VERSION ""

NS_ :

BS_:

BU_: VDM CMR_DSMC SOBDMC_HPCM_FD1 IPMA_ADAS PSCM ABS_ESC TCCM TCM_DSL PCM_HEV PCM ECM_Diesel GENERIC_GWMWakeup GWM _delete TSTR

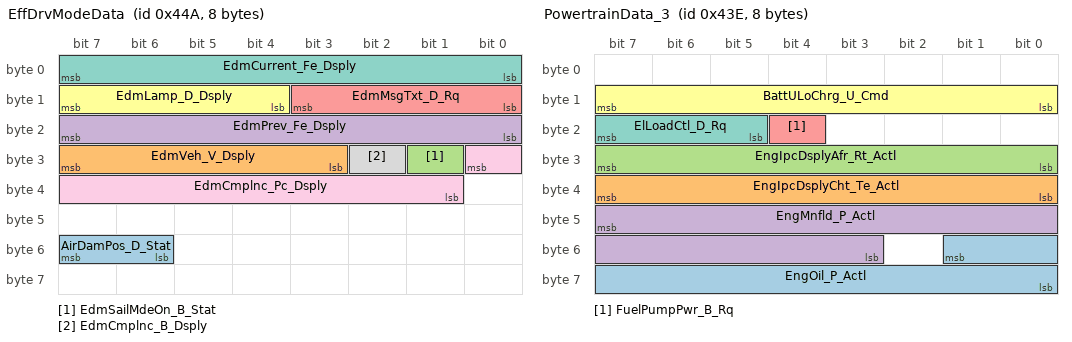
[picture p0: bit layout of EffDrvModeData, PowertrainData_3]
BO_ 1098 EffDrvModeData: 8 ECM_Diesel
 SG_ AirDamPos_D_Stat : 55|2@0+ (1,0) [0|3] "SED"  GWM
 SG_ EdmVeh_V_Dsply : 31|5@0+ (5,0) [0|155] "km/h"  GWM
 SG_ EdmSailMdeOn_B_Stat : 25|1@0+ (1,0) [0|1] "SED"  GWM
 SG_ EdmPrev_Fe_Dsply : 23|8@0+ (0.1,0) [0|25.5] "litre/100km"  GWM
 SG_ EdmMsgTxt_D_Rq : 11|4@0+ (1,0) [0|15] "SED"  GWM
 SG_ EdmLamp_D_Dsply : 15|4@0+ (1,0) [0|15] "SED"  GWM
 SG_ EdmCurrent_Fe_Dsply : 7|8@0+ (0.1,0) [0|25.5] "litre/100km"  GWM
 SG_ EdmCmplnc_B_Dsply : 26|1@0+ (1,0) [0|1] "SED"  GWM
 SG_ EdmCmplnc_Pc_Dsply : 24|8@0+ (0.392157,0) [0|100.000035] "percent"  GWM

BO_ 1086 PowertrainData_3: 8 PCM_HEV
 SG_ EngOil_P_Actl : 49|10@0+ (1,0) [0|1023] "kilopascal"  GWM
 SG_ EngIpcDsplyCht_Te_Actl : 39|8@0+ (1,-60) [-60|195] "degC"  GWM
 SG_ EngIpcDsplyAfr_Rt_Actl : 31|8@0+ (0.1,0) [0|25.5] "unitless"  GWM
 SG_ EngMnfld_P_Actl : 47|13@0+ (0.1,-206.8) [-206.8|612.3] "kilopascal"  GWM
 SG_ FuelPumpPwr_B_Rq : 20|1@0+ (1,0) [0|1] "SED"  GWM
 SG_ BattULoChrg_U_Cmd : 15|8@0+ (0.025,10.6) [10.6|16.975] "volt"  GWM
 SG_ ElLoadCtl_D_Rq : 23|3@0+ (1,0) [0|7] "SED"  GWM

BO_ 1071 Engine_Clutch_Data: 8 PCM_HEV
 SG_ EngAout_N_Dsply : 52|13@0+ (2,0) [0|16382] "rpm"  GWM
 SG_ CluPdl_PcRate_Actl : 7|8@0+ (0.04,-5) [-5|5.2] "%/ms"  GWM
 SG_ CluPdlPosPcMeas_D_Qf : 11|2@0+ (1,0) [0|3] "SED"  ABS_ESC,GWM
 SG_ CluPdlPos_Pc_Meas : 9|10@0+ (0.1,0) [0|102.3] "%"  ABS_ESC,GWM
 SG_ EngAoutIdl_N_Ntrl : 31|11@0+ (2,0) [0|4094] "rpm"  ABS_ESC,GWM

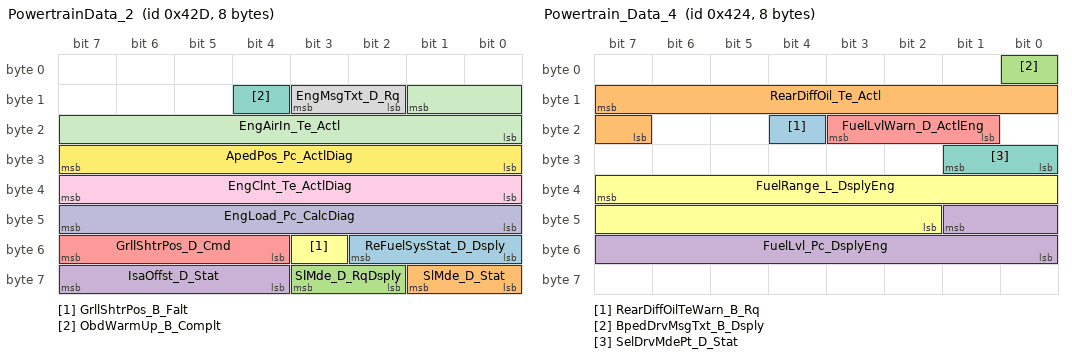
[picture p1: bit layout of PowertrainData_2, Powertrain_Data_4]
BO_ 1069 PowertrainData_2: 8 PCM_HEV
 SG_ ReFuelSysStat_D_Dsply : 50|3@0+ (1,0) [0|7] "SED"  GWM
 SG_ SlMde_D_Stat : 57|2@0+ (1,0) [0|3] "SED"  GWM
 SG_ SlMde_D_RqDsply : 59|2@0+ (1,0) [0|3] "SED"  GWM
 SG_ IsaOffst_D_Stat : 63|4@0+ (1,0) [0|15] "SED"  GWM
 SG_ GrllShtrPos_D_Cmd : 55|4@0+ (1,0) [0|15] "SED"  GWM
 SG_ GrllShtrPos_B_Falt : 51|1@0+ (1,0) [0|1] "SED"  GWM
 SG_ ObdWarmUp_B_Complt : 12|1@0+ (1,0) [0|1] "SED"  SOBDMC_HPCM_FD1,GWM
 SG_ EngMsgTxt_D_Rq : 11|2@0+ (1,0) [0|3] "SED"  GWM
 SG_ EngClnt_Te_ActlDiag : 39|8@0+ (1,-40) [-40|215] "degC"  SOBDMC_HPCM_FD1,TCM_DSL,GWM
 SG_ EngLoad_Pc_CalcDiag : 47|8@0+ (0.392157,0) [0|100.000035] "%"  SOBDMC_HPCM_FD1,TCM_DSL,GWM
 SG_ EngAirIn_Te_Actl : 9|10@0+ (0.25,-128) [-128|127.25] "degC"  GWM,TCM_DSL
 SG_ ApedPos_Pc_ActlDiag : 31|8@0+ (0.392157,0) [0|100.000035] "%"  SOBDMC_HPCM_FD1,TCM_DSL,GWM

BO_ 1060 Powertrain_Data_4: 8 PCM_HEV
 SG_ RearDiffOilTeWarn_B_Rq : 20|1@0+ (1,0) [0|1] "SED"  GWM
 SG_ RearDiffOil_Te_Actl : 15|9@0+ (1,-40) [-40|470] "degC"  GWM
 SG_ BpedDrvMsgTxt_B_Dsply : 0|1@0+ (1,0) [0|1] "SED"  GWM
 SG_ FuelLvl_Pc_DsplyEng : 41|10@0+ (0.108696,-5.217408) [-5.217408|105.9786] "percent"  GWM
 SG_ FuelLvlWarn_D_ActlEng : 19|3@0+ (1,0) [0|7] "SED"  GWM
 SG_ FuelRange_L_DsplyEng : 39|14@0+ (0.1,0) [0|1638.3] "kilometer"  GWM
 SG_ SelDrvMdePt_D_Stat : 25|2@0+ (1,0) [0|3] "SED"  ABS_ESC,GWM

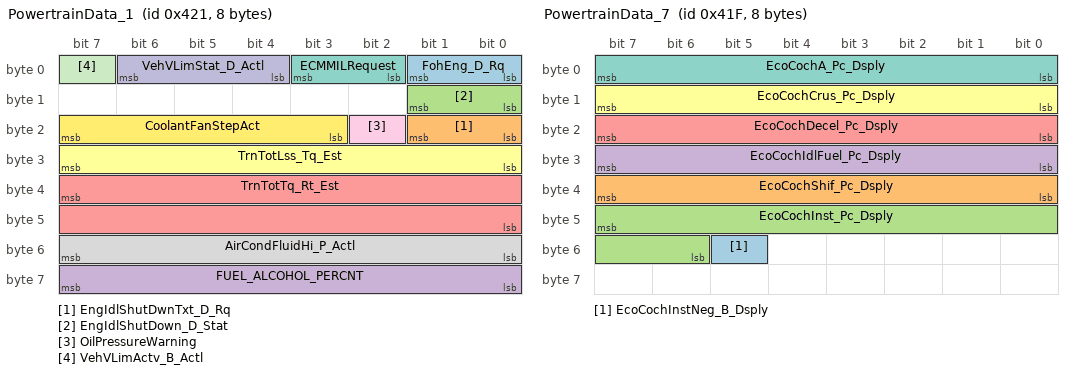
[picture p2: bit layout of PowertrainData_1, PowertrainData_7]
BO_ 1057 PowertrainData_1: 8 PCM_HEV
 SG_ FohEng_D_Rq : 1|2@0+ (1,0) [0|3] "SED"  GWM
 SG_ EngIdlShutDwnTxt_D_Rq : 17|2@0+ (1,0) [0|3] "SED"  GWM
 SG_ EngIdlShutDown_D_Stat : 9|2@0+ (1,0) [0|3] "SED"  GWM
 SG_ FUEL_ALCOHOL_PERCNT : 63|8@0+ (0.393700787,0) [0|99.999899898] "Percent"  GWM
 SG_ TrnTotTq_Rt_Est : 39|16@0+ (0.001,0) [0|65.533] "Unitless"  GWM
 SG_ TrnTotLss_Tq_Est : 31|8@0+ (0.5,0) [0|126.5] "Nm"  GWM
 SG_ ECMMILRequest : 3|2@0+ (1,0) [0|3] "SED"  GWM
 SG_ AirCondFluidHi_P_Actl : 55|8@0+ (0.125,0) [0|31.625] "bar"  SOBDMC_HPCM_FD1,GWM
 SG_ OilPressureWarning : 18|1@0+ (1,0) [0|1] "SED"  GWM
 SG_ VehVLimStat_D_Actl : 6|3@0+ (1,0) [0|7] "SED"  GWM,TCM_DSL
 SG_ VehVLimActv_B_Actl : 7|1@0+ (1,0) [0|1] "SED"  GWM,TCM_DSL
 SG_ CoolantFanStepAct : 23|5@0+ (1,0) [0|31] "Steps"  GWM

BO_ 1055 PowertrainData_7: 8 PCM_HEV
 SG_ EcoCochInstNeg_B_Dsply : 53|1@0+ (1,0) [0|1] "SED"  GWM
 SG_ EcoCochShif_Pc_Dsply : 39|8@0+ (0.392157,0) [0|100.000035] "percent"  GWM
 SG_ EcoCochInst_Pc_Dsply : 47|10@0+ (0.1,0) [0|102.3] "percent"  GWM
 SG_ EcoCochIdlFuel_Pc_Dsply : 31|8@0+ (0.392157,0) [0|100.000035] "percent"  GWM
 SG_ EcoCochDecel_Pc_Dsply : 23|8@0+ (0.392157,0) [0|100.000035] "percent"  GWM
 SG_ EcoCochCrus_Pc_Dsply : 15|8@0+ (0.392157,0) [0|100.000035] "percent"  GWM
 SG_ EcoCochA_Pc_Dsply : 7|8@0+ (0.392157,0) [0|100.000035] "percent"  GWM

BO_ 562 PowertrainData_11: 8 ECM_Diesel
 SG_ GearNtrl_No_Cs : 15|8@0+ (1,0) [0|255] "unitless"  GWM
 SG_ GearNtrl_No_Cnt : 5|4@0+ (1,0) [0|15] "unitless"  GWM
 SG_ GearNtrl_D_Stat : 7|2@0+ (1,0) [0|3] "SED"  ABS_ESC,GWM

BO_ 523 Engine_Data_18: 8 ECM_Diesel
 SG_ EngAirFiltMsgTxt_D_Rq : 2|3@0+ (1,0) [0|7] "SED"  GWM
 SG_ WaterInFuel_B_Falt : 8|1@0+ (1,0) [0|1] "SED"  GWM
 SG_ UreaMnAdd_L2_Actl : 23|8@0+ (0.1,0) [0|25.4] "litre"  GWM
 SG_ VehUreaRnge3_L_DsplyMx : 31|16@0+ (1,0) [0|65535] "unitless"  GWM
 SG_ UreaMxAdd_L2_Actl : 47|9@0+ (0.1,0) [0|51] "litre"  GWM

BO_ 517 PowertrainData_6: 8 PCM_HEV
 SG_ FapLc_B_Err : 10|1@0+ (1,0) [0|1] "SED"  IPMA_ADAS,GWM
 SG_ BrkTot_Tq_RqFapLc : 7|13@0+ (4,0) [0|32764] "Nm"  ABS_ESC,GWM
 SG_ TrnAin_Pc_RqDrv : 9|10@0+ (0.1,0) [0|102.3] "percent"  TCCM,GWM

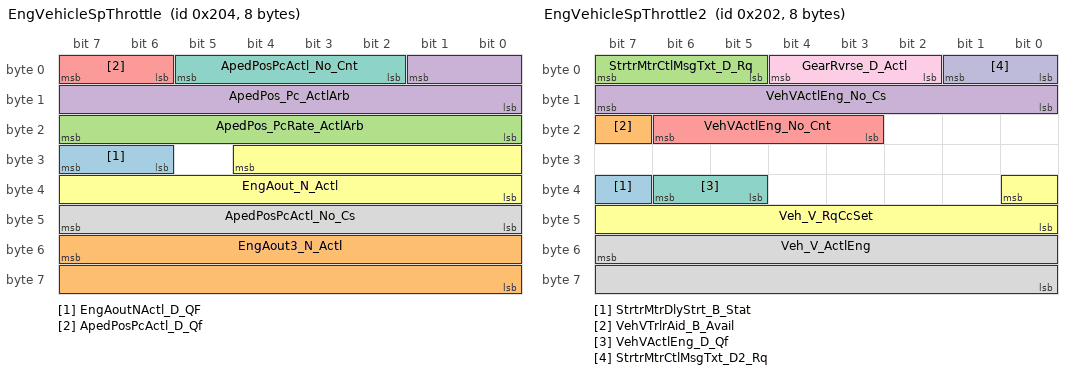
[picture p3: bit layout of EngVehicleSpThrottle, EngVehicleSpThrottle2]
BO_ 516 EngVehicleSpThrottle: 8 PCM_HEV
 SG_ EngAoutNActl_D_QF : 31|2@0+ (1,0) [0|3] "SED"  TCM_DSL,GWM
 SG_ EngAout3_N_Actl : 55|16@0+ (0.25,0) [0|16383.5] "RPM"  SOBDMC_HPCM_FD1,GWM
 SG_ ApedPos_PcRate_ActlArb : 23|8@0+ (0.04,-5) [-5|5.12] "%/ms"  TCM_DSL,GWM
 SG_ ApedPos_Pc_ActlArb : 1|10@0+ (0.1,0) [0|102.3] "%"  VDM,CMR_DSMC,SOBDMC_HPCM_FD1,IPMA_ADAS,TCCM,ABS_ESC,PSCM,TCM_DSL,GWM
 SG_ ApedPosPcActl_D_Qf : 7|2@0+ (1,0) [0|3] "SED"  VDM,CMR_DSMC,IPMA_ADAS,SOBDMC_HPCM_FD1,ABS_ESC,PSCM,TCM_DSL,GWM
 SG_ EngAout_N_Actl : 28|13@0+ (2,0) [0|16382] "rpm"  VDM,ABS_ESC,PSCM,TCCM,TCM_DSL,GWM
 SG_ ApedPosPcActl_No_Cnt : 5|4@0+ (1,0) [0|15] "Unitless"  SOBDMC_HPCM_FD1,GWM
 SG_ ApedPosPcActl_No_Cs : 47|8@0+ (1,0) [0|255] "Unitless"  ABS_ESC,SOBDMC_HPCM_FD1,GWM

BO_ 514 EngVehicleSpThrottle2: 8 PCM_HEV
 SG_ StrtrMtrDlyStrt_B_Stat : 39|1@0+ (1,0) [0|1] "SED"  GWM
 SG_ VehVTrlrAid_B_Avail : 23|1@0+ (1,0) [0|1] "SED"  PSCM,GWM
 SG_ StrtrMtrCtlMsgTxt_D_Rq : 7|3@0+ (1,0) [0|7] "SED"  GWM
 SG_ VehVActlEng_No_Cs : 15|8@0+ (1,0) [0|255] "Unitless"  PSCM,GWM
 SG_ VehVActlEng_No_Cnt : 22|4@0+ (1,0) [0|15] "Unitless"  PSCM,GWM
 SG_ Veh_V_RqCcSet : 32|9@0+ (0.5,0) [0|255.5] "kph"  IPMA_ADAS,ABS_ESC,TCM_DSL,GWM
 SG_ VehVActlEng_D_Qf : 38|2@0+ (1,0) [0|3] "SED"  VDM,IPMA_ADAS,ABS_ESC,PSCM,TCM_DSL,GWM
 SG_ Veh_V_ActlEng : 55|16@0+ (0.01,0) [0|655.35] "kph"  VDM,SOBDMC_HPCM_FD1,IPMA_ADAS,ABS_ESC,PSCM,TCM_DSL,GWM
 SG_ GearRvrse_D_Actl : 4|3@0+ (1,0) [0|7] "SED"  CMR_DSMC,IPMA_ADAS,ABS_ESC,PSCM,GWM
 SG_ StrtrMtrCtlMsgTxt_D2_Rq : 1|2@0+ (1,0) [0|3] "SED"  GWM

BO_ 512 TorqueDataEngFlags: 8 PCM_HEV
 SG_ PrplWhlTotTqRq_No_Cs : 63|8@0+ (1,0) [0|255] "Unitless"  ABS_ESC,GWM
 SG_ PrplWhlTotTqRq_No_Cnt : 51|4@0+ (1,0) [0|15] "Unitless"  ABS_ESC,GWM
 SG_ PrplWhlTot_Tq_Rq : 39|16@0+ (4,-131072) [-131072|131068] "Nm"  VDM,TCCM,ABS_ESC,GWM
 SG_ PrplWhlTot_Tq_LimMn : 23|16@0+ (4,-131072) [-131072|131068] "Nm"  ABS_ESC,GWM
 SG_ PtDrvMde_D_Stat : 55|4@0+ (1,0) [0|15] "SED"  IPMA_ADAS,GWM

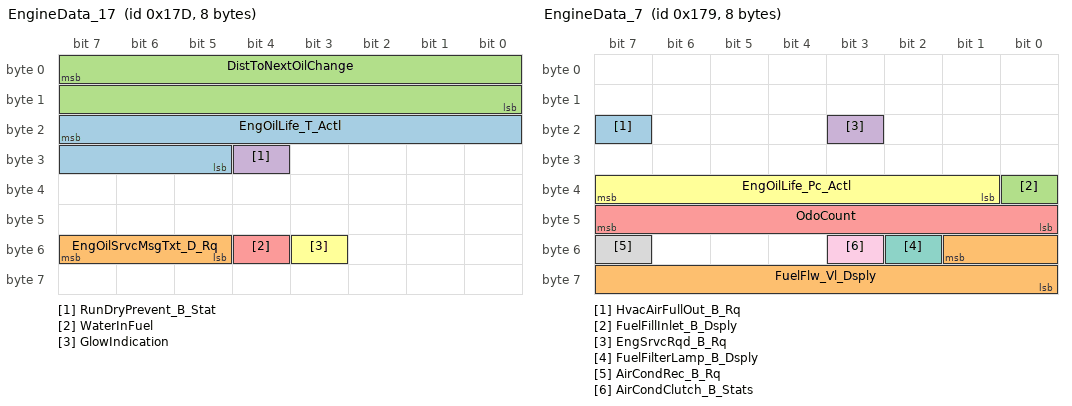
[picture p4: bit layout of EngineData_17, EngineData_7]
BO_ 381 EngineData_17: 8 ECM_Diesel
 SG_ EngOilLife_T_Actl : 23|11@0+ (1,0) [0|2047] "days"  GWM
 SG_ EngOilSrvcMsgTxt_D_Rq : 55|3@0+ (1,0) [0|7] "SED"  GWM
 SG_ DistToNextOilChange : 7|16@0+ (1,0) [0|65535] "unitless"  GWM
 SG_ RunDryPrevent_B_Stat : 28|1@0+ (1,0) [0|1] "SED"  GWM
 SG_ WaterInFuel : 52|1@0+ (1,0) [0|1] "SED"  GWM
 SG_ GlowIndication : 51|1@0+ (1,0) [0|1] "SED"  GWM

BO_ 380 EngineData_16: 8 PCM
 SG_ EngOilLvlWarn_D_Rq1 : 55|3@0+ (1,0) [0|7] "SED"  GWM
 SG_ EngExhBrkOnLamp_B_Rq : 27|1@0+ (1,0) [0|1] "SED"  GWM
 SG_ EngExhBrkAutoLamp_B_Rq : 3|1@0+ (1,0) [0|1] "SED"  GWM
 SG_ EngAout_N_MxAllw : 52|13@0+ (2,0) [0|16382] "rpm"  SOBDMC_HPCM_FD1,GWM
 SG_ EngExhBrkMde_D_Actl : 31|4@0+ (1,0) [0|15] "SED"  TCM_DSL,GWM

BO_ 377 EngineData_7: 8 PCM_HEV
 SG_ HvacAirFullOut_B_Rq : 23|1@0+ (1,0) [0|1] "SED"  GWM
 SG_ FuelFlw_Vl_Dsply : 49|10@0+ (25,0) [0|25575] "Micro_Liter"  GWM
 SG_ FuelFillInlet_B_Dsply : 32|1@0+ (1,0) [0|1] "SED"  GWM
 SG_ EngSrvcRqd_B_Rq : 19|1@0+ (1,0) [0|1] "SED"  GWM
 SG_ OdoCount : 47|8@0+ (0.2,0) [0|50.8] "Meters"  GWM
 SG_ EngOilLife_Pc_Actl : 39|7@0+ (1,0) [0|100] "Percent"  GWM
 SG_ FuelFilterLamp_B_Dsply : 50|1@0+ (1,0) [0|1] "SED"  GWM
 SG_ AirCondRec_B_Rq : 55|1@0+ (1,0) [0|1] "SED"  GWM
 SG_ AirCondClutch_B_Stats : 51|1@0+ (1,0) [0|1] "SED"  GWM

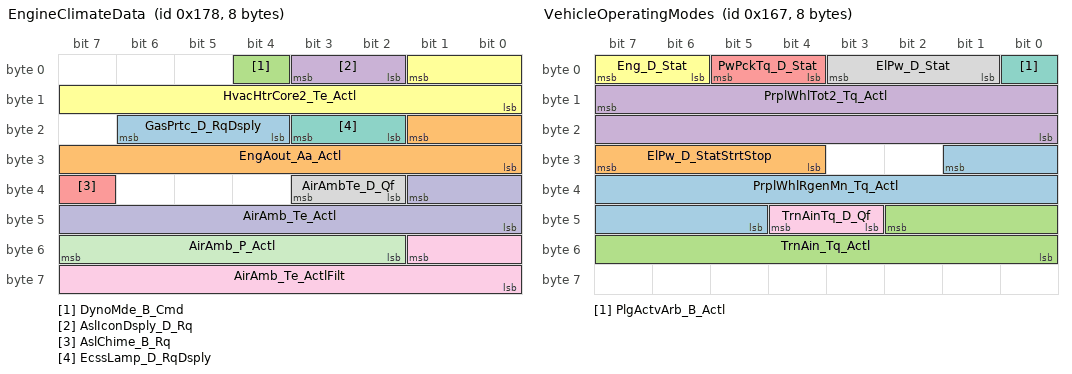
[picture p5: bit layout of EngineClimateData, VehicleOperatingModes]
BO_ 376 EngineClimateData: 8 PCM_HEV
 SG_ GasPrtc_D_RqDsply : 22|3@0+ (1,0) [0|7] "SED"  GWM
 SG_ EngAout_Aa_Actl : 17|10@0+ (0.05,-25.6) [-25.6|25.55] "rpm/ms"  ABS_ESC,GWM
 SG_ DynoMde_B_Cmd : 4|1@0+ (1,0) [0|1] "SED"  TCM_DSL,ABS_ESC,GWM
 SG_ AslIconDsply_D_Rq : 3|2@0+ (1,0) [0|3] "SED"  GWM
 SG_ AslChime_B_Rq : 39|1@0+ (1,0) [0|1] "SED"  GWM
 SG_ HvacHtrCore2_Te_Actl : 1|10@0+ (0.25,-50) [-50|205.5] "degC"  SOBDMC_HPCM_FD1,GWM
 SG_ EcssLamp_D_RqDsply : 19|2@0+ (1,0) [0|3] "SED"  GWM
 SG_ AirAmbTe_D_Qf : 35|2@0+ (1,0) [0|3] "SED"  SOBDMC_HPCM_FD1,IPMA_ADAS,ABS_ESC,TCCM,GWM
 SG_ AirAmb_Te_ActlFilt : 49|10@0+ (0.25,-128) [-128|127.75] "deg C"  SOBDMC_HPCM_FD1,IPMA_ADAS,GWM
 SG_ AirAmb_Te_Actl : 33|10@0+ (0.25,-128) [-128|127.75] "degC"  ABS_ESC,TCCM,GWM
 SG_ AirAmb_P_Actl : 55|6@0+ (10,500) [500|1110] "mbar"  ABS_ESC,TCM_DSL,GWM

BO_ 373 EngineData_11: 8 ECM_Diesel
 SG_ DieslPrtc2_D_RqDsply : 47|4@0+ (1,0) [0|15] "SED"  GWM
 SG_ DieslPrtcRgen_D_Actl : 38|2@0+ (1,0) [0|3] "SED"  TCM_DSL,GWM
 SG_ EngTeColdPrtct_D_Stats : 4|2@0+ (1,0) [0|3] "SED"  GWM
 SG_ EngExhOvrTe_B_RqDsply : 39|1@0+ (1,0) [0|1] "SED"  GWM

BO_ 359 VehicleOperatingModes: 8 PCM_HEV
 SG_ PrplWhlRgenMn_Tq_Actl : 25|13@0+ (4,-16380) [-16380|16380] "Nm"  ABS_ESC,GWM
 SG_ ElPw_D_StatStrtStop : 31|4@0+ (1,0) [0|15] "SED"  ABS_ESC,PSCM,GWM
 SG_ TrnAin_Tq_Actl : 42|11@0+ (1,-500) [-500|1547] "Nm"  ABS_ESC,GWM
 SG_ PrplWhlTot2_Tq_Actl : 15|16@0+ (4,-131072) [-131072|131060] "Nm"  ABS_ESC,PSCM,TCCM,GWM
 SG_ PwPckTq_D_Stat : 5|2@0+ (1,0) [0|3] "SED"  SOBDMC_HPCM_FD1,VDM,CMR_DSMC,IPMA_ADAS,ABS_ESC,PSCM,TCCM,TCM_DSL,GWM
 SG_ Eng_D_Stat : 7|2@0+ (1,0) [0|3] "SED"  ABS_ESC,GWM
 SG_ PlgActvArb_B_Actl : 0|1@0+ (1,0) [0|1] "SED"  GWM
 SG_ ElPw_D_Stat : 3|3@0+ (1,0) [0|7] "SED"  VDM,CMR_DSMC,IPMA_ADAS,ABS_ESC,PSCM,TCCM,TCM_DSL,GWM
 SG_ TrnAinTq_D_Qf : 44|2@0+ (1,0) [0|3] "SED"  ABS_ESC,GWM

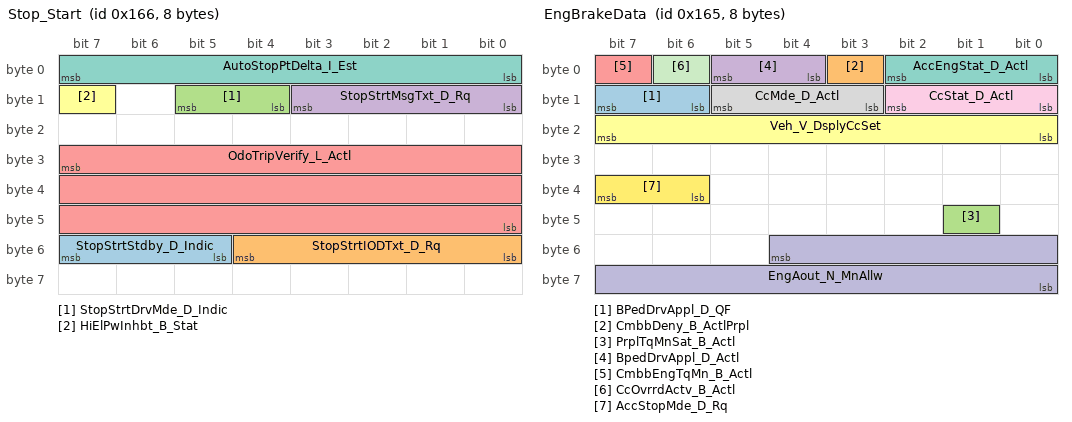
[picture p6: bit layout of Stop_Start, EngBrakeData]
BO_ 358 Stop_Start: 8 PCM_HEV
 SG_ StopStrtStdby_D_Indic : 55|3@0+ (1,0) [0|7] "SED"  GWM
 SG_ StopStrtIODTxt_D_Rq : 52|5@0+ (1,0) [0|31] "SED"  GWM
 SG_ StopStrtDrvMde_D_Indic : 13|2@0+ (1,0) [0|3] "SED"  GWM
 SG_ StopStrtMsgTxt_D_Rq : 11|4@0+ (1,0) [0|15] "SED"  GWM
 SG_ OdoTripVerify_L_Actl : 31|24@0+ (0.1,0) [0|1677721.4] "km"  GWM
 SG_ HiElPwInhbt_B_Stat : 15|1@0+ (1,0) [0|1] "SED"  GWM
 SG_ AutoStopPtDelta_I_Est : 7|8@0+ (1,-127) [-127|127] "Amps"  GWM

BO_ 357 EngBrakeData: 8 PCM_HEV
 SG_ BPedDrvAppl_D_QF : 15|2@0+ (1,0) [0|3] "SED"  CMR_DSMC,SOBDMC_HPCM_FD1,IPMA_ADAS,ABS_ESC,PSCM,TCM_DSL,GWM
 SG_ CmbbDeny_B_ActlPrpl : 3|1@0+ (1,0) [0|1] "SED"  IPMA_ADAS,GWM
 SG_ PrplTqMnSat_B_Actl : 41|1@0+ (1,0) [0|1] "SED"  IPMA_ADAS,GWM
 SG_ BpedDrvAppl_D_Actl : 5|2@0+ (1,0) [0|3] "SED"  CMR_DSMC,SOBDMC_HPCM_FD1,IPMA_ADAS,ABS_ESC,PSCM,TCCM,TCM_DSL,GWM
 SG_ CmbbEngTqMn_B_Actl : 7|1@0+ (1,0) [0|1] "SED"  IPMA_ADAS,GWM
 SG_ Veh_V_DsplyCcSet : 23|8@0+ (1,0) [0|253] "Unitless"  GWM,IPMA_ADAS
 SG_ AccEngStat_D_Actl : 2|3@0+ (1,0) [0|7] "SED"  IPMA_ADAS,GWM
 SG_ CcMde_D_Actl : 13|3@0+ (1,0) [0|7] "SED"  VDM,TCM_DSL,ABS_ESC,GWM
 SG_ CcStat_D_Actl : 10|3@0+ (1,0) [0|7] "SED"  CMR_DSMC,SOBDMC_HPCM_FD1,IPMA_ADAS,ABS_ESC,TCCM,TCM_DSL,GWM
 SG_ EngAout_N_MnAllw : 52|13@0+ (2,0) [0|16382] "rpm"  SOBDMC_HPCM_FD1,GWM
 SG_ CcOvrrdActv_B_Actl : 6|1@0+ (1,0) [0|1] "SED"  VDM,IPMA_ADAS,ABS_ESC,TCCM,TCM_DSL,GWM
 SG_ AccStopMde_D_Rq : 39|2@0+ (1,0) [0|3] "SED"  IPMA_ADAS,ABS_ESC,GWM

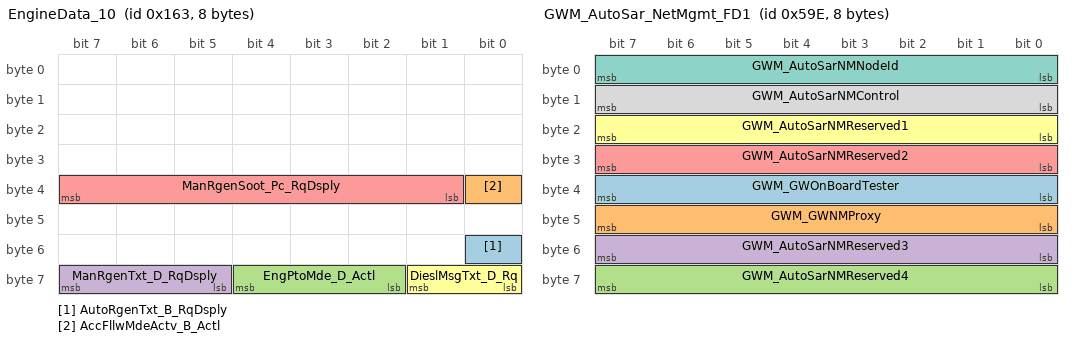
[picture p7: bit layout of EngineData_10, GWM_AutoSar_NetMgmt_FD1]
BO_ 355 EngineData_10: 8 ECM_Diesel
 SG_ AutoRgenTxt_B_RqDsply : 48|1@0+ (1,0) [0|1] "SED"  GWM
 SG_ AccFllwMdeActv_B_Actl : 32|1@0+ (1,0) [0|1] "SED"  GWM
 SG_ EngPtoMde_D_Actl : 60|3@0+ (1,0) [0|7] "SED"  GWM
 SG_ ManRgenTxt_D_RqDsply : 63|3@0+ (1,0) [0|7] "SED"  GWM
 SG_ ManRgenSoot_Pc_RqDsply : 39|7@0+ (1,0) [0|126] "%"  GWM
 SG_ DieslMsgTxt_D_Rq : 57|2@0+ (1,0) [0|3] "SED"  GWM

BO_ 342 EngineData_6: 8 PCM_HEV
 SG_ EngOvrhtMitgActv_D_Ind : 36|2@0+ (1,0) [0|3] "SED"  GWM
 SG_ EngClntTe_D_Qf : 33|2@0+ (1,0) [0|3] "SED"  VDM,SOBDMC_HPCM_FD1,TCM_DSL,GWM
 SG_ EngGoutLss_Tq_Est : 31|8@0+ (1,0) [0|255] "Nm"  SOBDMC_HPCM_FD1,GWM
 SG_ EngOil_Te_Actl : 15|8@0+ (1,-60) [-60|193] "degC"  GWM
 SG_ EngClnt_Te_Actl : 7|8@0+ (1,-60) [-60|195] "degC"  VDM,SOBDMC_HPCM_FD1,TCM_DSL,GWM

BO_ 71 Global_PATS_TargetInfo: 8 PCM_HEV
 SG_ immoTarget1Status : 7|3@0+ (1,0) [0|7] "SED"  ABS_ESC,TCM_DSL,GWM
 SG_ immoTarget1Data : 15|40@0+ (1,0) [0|1099511627775] "Encrypted"  ABS_ESC,GWM
 SG_ immoTarget1Cmd : 4|3@0+ (1,0) [0|7] "SED"  ABS_ESC,GWM

BO_ 1822 TesterPhysicalResGWM_FD1: 64 GWM
 SG_ TesterPhysicalResGWM_F1 : 7|64@0+ (1,0) [0|1.84467E+019] "unitless"  TSTR

BO_ 1438 GWM_AutoSar_NetMgmt_FD1: 8 GWM
 SG_ GWM_GWOnBoardTester : 39|8@0+ (1,0) [0|255] "unitless"  CMR_DSMC,PCM_HEV,PCM,SOBDMC_HPCM_FD1,PSCM,ABS_ESC
 SG_ GWM_GWNMProxy : 47|8@0+ (1,0) [0|255] "unitless"  CMR_DSMC,PCM_HEV,PCM,SOBDMC_HPCM_FD1,PSCM,ABS_ESC
 SG_ GWM_AutoSarNMReserved4 : 63|8@0+ (1,0) [0|255] "unitless"  CMR_DSMC,PCM_HEV,PCM,SOBDMC_HPCM_FD1,PSCM,ABS_ESC
 SG_ GWM_AutoSarNMReserved3 : 55|8@0+ (1,0) [0|255] "unitless"  CMR_DSMC,PCM_HEV,PCM,SOBDMC_HPCM_FD1,PSCM,ABS_ESC
 SG_ GWM_AutoSarNMReserved2 : 31|8@0+ (1,0) [0|255] "unitless"  CMR_DSMC,PCM_HEV,PCM,SOBDMC_HPCM_FD1,PSCM,ABS_ESC
 SG_ GWM_AutoSarNMReserved1 : 23|8@0+ (1,0) [0|255] "unitless"  CMR_DSMC,PCM_HEV,PCM,SOBDMC_HPCM_FD1,PSCM,ABS_ESC
 SG_ GWM_AutoSarNMNodeId : 7|8@0+ (1,0) [0|255] "unitless"  CMR_DSMC,PCM_HEV,PCM,SOBDMC_HPCM_FD1,PSCM,ABS_ESC
 SG_ GWM_AutoSarNMControl : 15|8@0+ (1,0) [0|255] "unitless"  CMR_DSMC,PCM_HEV,PCM,SOBDMC_HPCM_FD1,PSCM,ABS_ESC

BO_ 954 Body_Info_10_FD1: 8 GWM
 SG_ GenericSwtch3_No_Actl : 15|3@0+ (1,0) [0|7] "unitless" Vector__XXX
 SG_ GenericSwtch2_No_Actl : 4|3@0+ (1,0) [0|7] "unitless"  PCM_HEV,PCM
 SG_ GenericSwtch1_No_Actl : 7|3@0+ (1,0) [0|7] "unitless" Vector__XXX

BO_ 1006 Personality_IPMB_Data: 8 IPMA_ADAS
 SG_ PersIndexIpmb_D_Actl : 39|3@0+ (1,0) [0|7] "SED"  GWM
 SG_ FeatNoIpmbActl : 23|16@0+ (1,0) [0|65535] "Number"  GWM
 SG_ FeatConfigIpmbActl : 7|16@0+ (1,0) [0|65535] "Undefined"  GWM

BO_ 820 Adaptive_Headlamp_Stat: 8 GWM
 SG_ AhbStatGfhbFdbk_D_Actl : 53|2@0+ (1,0) [0|3] "SED"  IPMA_ADAS
 SG_ HeadLghtDrvSide_B_Stat : 33|1@0+ (1,0) [0|1] "SED"  IPMA_ADAS
 SG_ HeadLghtHiOn_B_StatHcm : 0|1@0+ (1,0) [0|1] "SED" Vector__XXX
 SG_ Adaptive_Hdlmp_Fault : 7|1@0+ (1,0) [0|1] "SED" Vector__XXX

BO_ 137 ActiveFrontStrg_Stat_FD1: 8 GWM
 SG_ SteWhlOffstRq_D_Stat : 43|2@0+ (1,0) [0|3] "SED" Vector__XXX
 SG_ SteWhlOffst_An_TotActl : 23|15@0+ (0.1,-1600) [-1600|1676.5] "degrees" Vector__XXX
 SG_ SteWhlBrkOffst_An_Actl : 7|15@0+ (0.1,-1600) [-1600|1676.5] "degrees" Vector__XXX
 SG_ SteWhlBrkAnActl_No_Cs : 39|8@0+ (1,0) [0|255] "Unitless" Vector__XXX
 SG_ SteWhlBrkAnActl_No_Cnt : 47|4@0+ (1,0) [0|15] "Unitless" Vector__XXX

BO_ 129 Steering_Wheel_Data2_FD1: 8 GWM
 SG_ SelDrvMdeSwtch3_D_Stat4 : 25|2@0+ (1,0) [0|3] "SED"  ABS_ESC
 SG_ SelDrvMdeSwtch2_D_Stat4 : 27|2@0+ (1,0) [0|3] "SED"  ABS_ESC
 SG_ SelDrvMdeSwtch1_D_Stat4 : 29|2@0+ (1,0) [0|3] "SED"  ABS_ESC
 SG_ SelDrvMdeSwtch_D_Stat4 : 21|2@0+ (1,0) [0|3] "SED"  ABS_ESC
 SG_ SteWhlSwtchView_B_Stat : 23|1@0+ (1,0) [0|1] "SED" Vector__XXX
 SG_ SteWhlSwtchSet_B_Stat : 8|1@0+ (1,0) [0|1] "SED" Vector__XXX
 SG_ SteWhlSwtchPhon_B_Stat : 9|1@0+ (1,0) [0|1] "SED" Vector__XXX
 SG_ SteWhlSwtchNav_B_Stat : 10|1@0+ (1,0) [0|1] "SED" Vector__XXX
 SG_ SteWhlSwtchMed_B_Stat : 11|1@0+ (1,0) [0|1] "SED" Vector__XXX
 SG_ SteWhlSwtchIod_B_Stat : 12|1@0+ (1,0) [0|1] "SED" Vector__XXX
 SG_ SteWhlSwtchHud_B_Stat : 13|1@0+ (1,0) [0|1] "SED" Vector__XXX
 SG_ SteWhlSwtchBack_B_Stat : 14|1@0+ (1,0) [0|1] "SED" Vector__XXX
 SG_ SteWhlSwtchMenu_B_Stat : 22|1@0+ (1,0) [0|1] "SED" Vector__XXX
 SG_ SteEffortInc_B_RqDrv : 5|1@0+ (1,0) [0|1] "SED" Vector__XXX
 SG_ SelDrvMdeInc_B_RqDrv : 6|1@0+ (1,0) [0|1] "SED" Vector__XXX
 SG_ SelDrvMdeDec_B_RqDrv : 7|1@0+ (1,0) [0|1] "SED" Vector__XXX
 SG_ SuspDampInc_B_RqDrv : 15|1@0+ (1,0) [0|1] "SED" Vector__XXX
 SG_ SteWhlSwtchUp_B_Stat : 3|1@0+ (1,0) [0|1] "SED" Vector__XXX
 SG_ SteWhlSwtchRght_B_Stat : 2|1@0+ (1,0) [0|1] "SED" Vector__XXX
 SG_ SteWhlSwtchOk_B_Stat : 4|1@0+ (1,0) [0|1] "SED" Vector__XXX
 SG_ SteWhlSwtchLeft_B_Stat : 1|1@0+ (1,0) [0|1] "SED" Vector__XXX
 SG_ SteWhlSwtchDown_B_Stat : 0|1@0+ (1,0) [0|1] "SED" Vector__XXX
 SG_ SteWhlSwtchHome_B_Stat : 19|1@0+ (1,0) [0|1] "SED" Vector__XXX
 SG_ SteWhlSwtchInfo_B_Stat : 18|1@0+ (1,0) [0|1] "SED" Vector__XXX

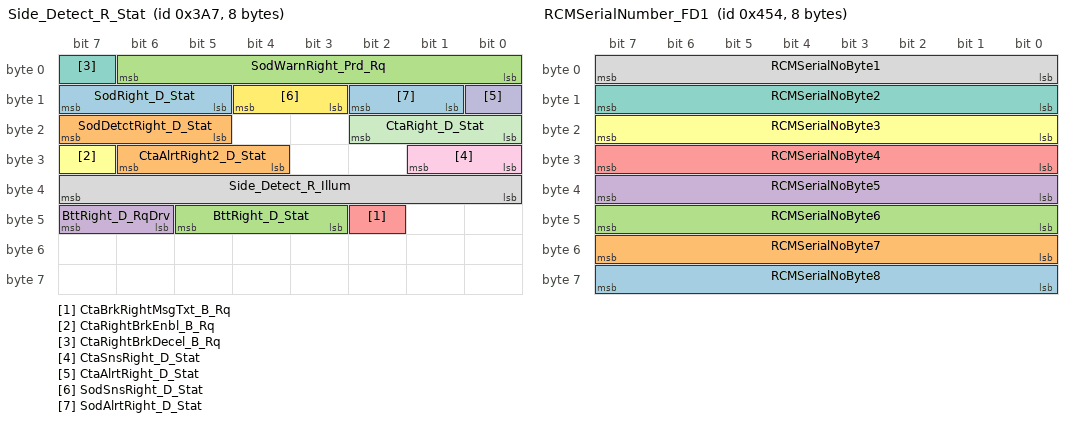
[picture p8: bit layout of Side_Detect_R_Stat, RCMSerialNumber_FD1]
BO_ 935 Side_Detect_R_Stat: 8 IPMA_ADAS
 SG_ SodRight_D_Stat : 15|3@0+ (1,0) [0|7] "SED"  GWM
 SG_ CtaAlrtRight2_D_Stat : 30|3@0+ (1,0) [0|7] "SED"  GWM
 SG_ BttRight_D_Stat : 45|3@0+ (1,0) [0|7] "SED"  GWM
 SG_ BttRight_D_RqDrv : 47|2@0+ (1,0) [0|3] "SED"  GWM
 SG_ CtaBrkRightMsgTxt_B_Rq : 42|1@0+ (1,0) [0|1] "SED"  GWM
 SG_ CtaRightBrkEnbl_B_Rq : 31|1@0+ (1,0) [0|1] "SED"  GWM,ABS_ESC
 SG_ CtaRightBrkDecel_B_Rq : 7|1@0+ (1,0) [0|1] "SED"  GWM,ABS_ESC
 SG_ Side_Detect_R_Illum : 39|8@0+ (1,0) [0|255] "Percent"  GWM
 SG_ CtaSnsRight_D_Stat : 25|2@0+ (1,0) [0|3] "SED"  GWM
 SG_ CtaAlrtRight_D_Stat : 8|1@0+ (1,0) [0|1] "SED"  GWM
 SG_ CtaRight_D_Stat : 18|3@0+ (1,0) [0|7] "SED"  GWM
 SG_ SodSnsRight_D_Stat : 12|2@0+ (1,0) [0|3] "SED"  GWM
 SG_ SodAlrtRight_D_Stat : 10|2@0+ (1,0) [0|3] "SED"  GWM
 SG_ SodDetctRight_D_Stat : 23|3@0+ (1,0) [0|7] "SED"  GWM
 SG_ SodWarnRight_Prd_Rq : 6|7@0+ (1,0) [0|127] "millisecond"  GWM

BO_ 1108 RCMSerialNumber_FD1: 8 GWM
 SG_ RCMSerialNoByte8 : 63|8@0+ (1,0) [0|253] "Unitless"  ABS_ESC
 SG_ RCMSerialNoByte7 : 55|8@0+ (1,0) [0|253] "Unitless"  ABS_ESC
 SG_ RCMSerialNoByte6 : 47|8@0+ (1,0) [0|253] "Unitless"  ABS_ESC
 SG_ RCMSerialNoByte5 : 39|8@0+ (1,0) [0|253] "Unitless"  ABS_ESC
 SG_ RCMSerialNoByte4 : 31|8@0+ (1,0) [0|253] "Unitless"  ABS_ESC
 SG_ RCMSerialNoByte3 : 23|8@0+ (1,0) [0|253] "Unitless"  ABS_ESC
 SG_ RCMSerialNoByte2 : 15|8@0+ (1,0) [0|253] "Unitless"  ABS_ESC
 SG_ RCMSerialNoByte1 : 7|8@0+ (1,0) [0|253] "Unitless"  ABS_ESC

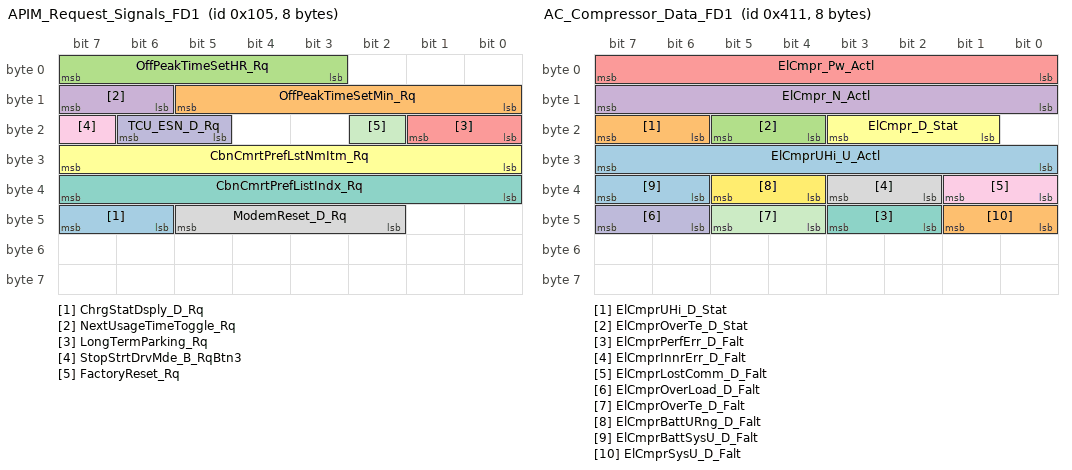
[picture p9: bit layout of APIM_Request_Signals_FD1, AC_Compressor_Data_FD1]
BO_ 261 APIM_Request_Signals_FD1: 8 GWM
 SG_ ChrgStatDsply_D_Rq : 47|2@0+ (1,0) [0|3] "SED" Vector__XXX
 SG_ OffPeakTimeSetMin_Rq : 13|6@0+ (1,0) [0|63] "unitless" Vector__XXX
 SG_ OffPeakTimeSetHR_Rq : 7|5@0+ (1,0) [0|31] "unitless" Vector__XXX
 SG_ NextUsageTimeToggle_Rq : 15|2@0+ (1,0) [0|3] "SED" Vector__XXX
 SG_ LongTermParking_Rq : 17|2@0+ (1,0) [0|3] "SED" Vector__XXX
 SG_ CbnCmrtPrefLstNmItm_Rq : 31|8@0+ (1,0) [0|255] "unitless" Vector__XXX
 SG_ CbnCmrtPrefListIndx_Rq : 39|8@0+ (1,0) [0|255] "unitless" Vector__XXX
 SG_ ModemReset_D_Rq : 45|4@0+ (1,0) [0|15] "SED"  SOBDMC_HPCM_FD1
 SG_ StopStrtDrvMde_B_RqBtn3 : 23|1@0+ (1,0) [0|1] "SED" Vector__XXX
 SG_ TCU_ESN_D_Rq : 22|2@0+ (1,0) [0|3] "SED" Vector__XXX
 SG_ FactoryReset_Rq : 18|1@0+ (1,0) [0|1] "SED"  SOBDMC_HPCM_FD1

BO_ 1146 TrailerInfo_2_FD1: 8 GWM
 SG_ TrlrAidSwtch_D_RqDrv : 35|2@0+ (1,0) [0|3] "SED"  PSCM,IPMA_ADAS
 SG_ TrlrAidCtl_U_RqDrv : 31|12@0+ (0.00125,0) [0|5.11625] "volt"  PSCM

BO_ 533 APIM_Send_Signals_2_FD1: 8 GWM
 SG_ DcacPw_D_Rq : 62|2@0+ (1,0) [0|3] "SED"  PCM_HEV,PCM
 SG_ DcacPwReset_B_Rq : 63|1@0+ (1,0) [0|1] "SED"  PCM_HEV,PCM
 SG_ DcacMdeButtn_B_Stat : 8|1@0+ (1,0) [0|1] "SED"  PCM_HEV,PCM
 SG_ DcacPwButtn_B_Stat : 10|1@0+ (1,0) [0|1] "SED"  PCM_HEV,PCM
 SG_ DcacGfciTestBttn_B_Stat : 9|1@0+ (1,0) [0|1] "SED"  PCM,PCM_HEV
 SG_ TrlrBrkGain_No_Rq : 55|5@0+ (0.5,0) [0|15.5] "unitless" Vector__XXX
 SG_ DcacPwResetButtn_B_Stat : 11|1@0+ (1,0) [0|1] "SED"  PCM,PCM_HEV
 SG_ DcacPwOffButtn_B_Stat : 12|1@0+ (1,0) [0|1] "SED"  PCM,PCM_HEV
 SG_ DcacPwLoButtn_B_Stat : 13|1@0+ (1,0) [0|1] "SED"  PCM,PCM_HEV
 SG_ DcacPwHiButtn_B_Stat : 14|1@0+ (1,0) [0|1] "SED"  PCM,PCM_HEV
 SG_ DcacPwButtn_B_Falt : 15|1@0+ (1,0) [0|1] "SED"  PCM,PCM_HEV
 SG_ TrlrHitch_D_RqMnu : 23|4@0+ (1,0) [0|15] "SED"  IPMA_ADAS
 SG_ AutoEpbZoomView_B_Stat : 32|1@0+ (1,0) [0|1] "SED"  ABS_ESC
 SG_ AutoEpbButtn_B_Stat : 19|1@0+ (1,0) [0|1] "SED"  ABS_ESC
 SG_ TrlrAidMde_D_Rq : 5|2@0+ (1,0) [0|3] "SED"  PSCM
 SG_ TCU_Init_Actvtn_St : 1|2@0+ (1,0) [0|3] "SED" Vector__XXX
 SG_ TCU_Final_Actvtn_St : 3|2@0+ (1,0) [0|3] "SED" Vector__XXX
 SG_ OtaTrg_D_Stat : 41|2@0+ (1,0) [0|3] "SED" Vector__XXX
 SG_ OnbChrgGoTTouch_D_Rq : 43|2@0+ (1,0) [0|3] "SED"  SOBDMC_HPCM_FD1
 SG_ OnbChrgGoTPrcond_D_Rq : 34|2@0+ (1,0) [0|3] "SED"  SOBDMC_HPCM_FD1
 SG_ OnbChrgGoTOn_D_Rq : 25|2@0+ (1,0) [0|3] "SED"  SOBDMC_HPCM_FD1
 SG_ OnbChrgGoTMnte_D_Rq : 47|4@0+ (1,0) [0|15] "minute"  SOBDMC_HPCM_FD1
 SG_ OnbChrgGoTHr_T_Rq : 39|5@0+ (1,0) [0|29] "hour"  SOBDMC_HPCM_FD1
 SG_ OnbChrgGoTExtHtr_D_Rq : 27|2@0+ (1,0) [0|3] "SED"  SOBDMC_HPCM_FD1
 SG_ OnbChrgGoTElement_D_Rq : 31|4@0+ (1,0) [0|15] "Unitless"  SOBDMC_HPCM_FD1
 SG_ OnbChrgGoTDelete_B_Rq : 17|1@0+ (1,0) [0|1] "SED"  SOBDMC_HPCM_FD1
 SG_ OnbChrgClearAll_B_Rq : 18|1@0+ (1,0) [0|1] "SED"  SOBDMC_HPCM_FD1
 SG_ PaakMyKey_D_Rq : 7|2@0+ (1,0) [0|3] "SED" Vector__XXX
 SG_ OnbChrgGoTUpdate_B_Rq : 16|1@0+ (1,0) [0|1] "SED"  SOBDMC_HPCM_FD1

BO_ 1041 AC_Compressor_Data_FD1: 8 GWM
 SG_ ElCmprUHi_U_Actl : 31|8@0+ (2,0) [0|510] "volt"  SOBDMC_HPCM_FD1
 SG_ ElCmprUHi_D_Stat : 23|2@0+ (1,0) [0|3] "SED"  SOBDMC_HPCM_FD1
 SG_ ElCmprOverTe_D_Stat : 21|2@0+ (1,0) [0|3] "SED"  SOBDMC_HPCM_FD1
 SG_ ElCmpr_N_Actl : 15|8@0+ (50,0) [0|12700] "RPM"  SOBDMC_HPCM_FD1
 SG_ ElCmpr_Pw_Actl : 7|8@0+ (40,0) [0|10160] "watts"  SOBDMC_HPCM_FD1,PCM_HEV
 SG_ ElCmpr_D_Stat : 19|3@0+ (1,0) [0|7] "SED"  SOBDMC_HPCM_FD1
 SG_ ElCmprPerfErr_D_Falt : 43|2@0+ (1,0) [0|3] "SED"  SOBDMC_HPCM_FD1
 SG_ ElCmprInnrErr_D_Falt : 35|2@0+ (1,0) [0|3] "SED"  SOBDMC_HPCM_FD1
 SG_ ElCmprLostComm_D_Falt : 33|2@0+ (1,0) [0|3] "SED"  SOBDMC_HPCM_FD1
 SG_ ElCmprOverLoad_D_Falt : 47|2@0+ (1,0) [0|3] "SED"  SOBDMC_HPCM_FD1
 SG_ ElCmprOverTe_D_Falt : 45|2@0+ (1,0) [0|3] "SED"  SOBDMC_HPCM_FD1
 SG_ ElCmprBattURng_D_Falt : 37|2@0+ (1,0) [0|3] "SED"  SOBDMC_HPCM_FD1
 SG_ ElCmprBattSysU_D_Falt : 39|2@0+ (1,0) [0|3] "SED"  SOBDMC_HPCM_FD1
 SG_ ElCmprSysU_D_Falt : 41|2@0+ (1,0) [0|3] "SED"  SOBDMC_HPCM_FD1

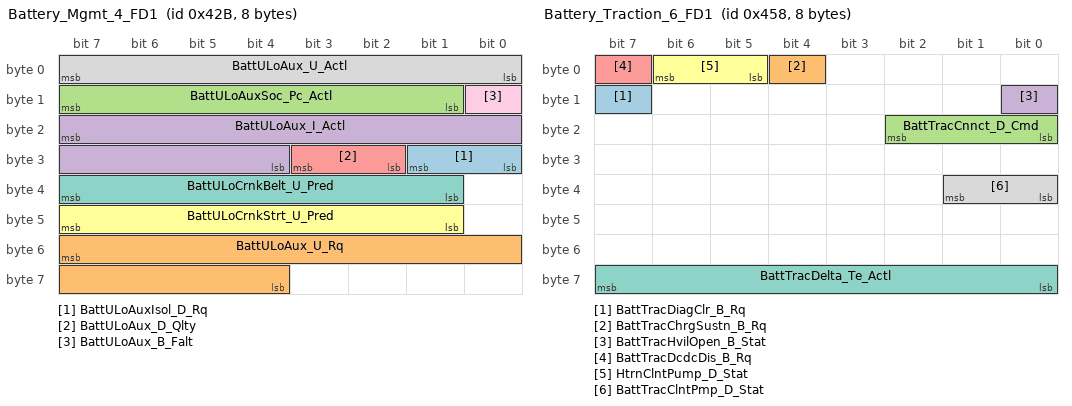
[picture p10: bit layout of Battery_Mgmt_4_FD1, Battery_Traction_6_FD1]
BO_ 1067 Battery_Mgmt_4_FD1: 8 GWM
 SG_ BattULoAuxIsol_D_Rq : 25|2@0+ (1,0) [0|3] "SED" Vector__XXX
 SG_ BattULoAux_U_Rq : 55|12@0+ (0.00390625,0) [0|15.9921875] "volt" Vector__XXX
 SG_ BattULoAuxSoc_Pc_Actl : 15|7@0+ (1,0) [0|127] "percent" Vector__XXX
 SG_ BattULoAux_I_Actl : 23|12@0+ (0.0625,-128) [-128|127.875] "ampere" Vector__XXX
 SG_ BattULoAux_D_Qlty : 27|2@0+ (1,0) [0|3] "SED" Vector__XXX
 SG_ BattULoCrnkStrt_U_Pred : 47|7@0+ (0.1,0) [0|12.7] "volt" Vector__XXX
 SG_ BattULoCrnkBelt_U_Pred : 39|7@0+ (0.1,0) [0|12.7] "volt" Vector__XXX
 SG_ BattULoAux_U_Actl : 7|8@0+ (0.0625,0) [0|15.875] "volt" Vector__XXX
 SG_ BattULoAux_B_Falt : 8|1@0+ (1,0) [0|1] "SED" Vector__XXX

BO_ 1112 Battery_Traction_6_FD1: 8 GWM
 SG_ BattTracDiagClr_B_Rq : 15|1@0+ (1,0) [0|1] "SED"  PCM_HEV
 SG_ BattTracChrgSustn_B_Rq : 4|1@0+ (1,0) [0|1] "SED"  SOBDMC_HPCM_FD1
 SG_ BattTracCnnct_D_Cmd : 18|3@0+ (1,0) [0|7] "SED"  SOBDMC_HPCM_FD1,PCM_HEV
 SG_ BattTracHvilOpen_B_Stat : 8|1@0+ (1,0) [0|1] "SED"  SOBDMC_HPCM_FD1,PCM_HEV
 SG_ BattTracDcdcDis_B_Rq : 7|1@0+ (1,0) [0|1] "SED"  PCM_HEV
 SG_ HtrnClntPump_D_Stat : 6|2@0+ (1,0) [0|3] "SED"  SOBDMC_HPCM_FD1
 SG_ BattTracDelta_Te_Actl : 63|8@0+ (0.5,-60) [-60|67.5] "degC"  SOBDMC_HPCM_FD1
 SG_ BattTracClntPmp_D_Stat : 33|2@0+ (1,0) [0|3] "SED"  SOBDMC_HPCM_FD1

BO_ 139 CruiseCtrl_Strg_Data_FD1: 8 GWM
 SG_ AfsPw_B_Rq : 24|1@0+ (1,0) [0|1] "SED"  PCM
 SG_ AccButtnGpTogglePress2 : 25|1@0+ (1,0) [0|1] "SED" Vector__XXX
 SG_ TjaButtnOnOffPress2 : 26|1@0+ (1,0) [0|1] "SED" Vector__XXX
 SG_ ActvFrontSteMsgTxt_D_Rq : 31|3@0+ (1,0) [0|7] "SED" Vector__XXX
 SG_ ActvFrontSteLck_D_Stat : 17|2@0+ (1,0) [0|3] "SED"  ECM_Diesel,PCM,PCM_HEV
 SG_ SelDrvMdeAdptSte_D_Stat : 28|2@0+ (1,0) [0|3] "SED"  ABS_ESC
 SG_ AslButtnOnOffPress2 : 4|1@0+ (1,0) [0|1] "SED" Vector__XXX
 SG_ AslButtnOnOffCnclPres2 : 5|1@0+ (1,0) [0|1] "SED" Vector__XXX
 SG_ CcButtnOnPress2 : 18|1@0+ (1,0) [0|1] "SED" Vector__XXX
 SG_ CcButtnOnOffPress2 : 19|1@0+ (1,0) [0|1] "SED" Vector__XXX
 SG_ CcButtnOnOffCnclPress2 : 20|1@0+ (1,0) [0|1] "SED" Vector__XXX
 SG_ CcButtnOffPress2 : 21|1@0+ (1,0) [0|1] "SED" Vector__XXX
 SG_ CcAsllButtnResPress2 : 22|1@0+ (1,0) [0|1] "SED" Vector__XXX
 SG_ CcAslButtnSetPress2 : 23|1@0+ (1,0) [0|1] "SED" Vector__XXX
 SG_ CcAslButtnSetIncPress2 : 8|1@0+ (1,0) [0|1] "SED" Vector__XXX
 SG_ CcAslButtnSetDecPress2 : 9|1@0+ (1,0) [0|1] "SED" Vector__XXX
 SG_ CcAslButtnResIncPress2 : 10|1@0+ (1,0) [0|1] "SED" Vector__XXX
 SG_ CcAslButtnResDecPress2 : 11|1@0+ (1,0) [0|1] "SED" Vector__XXX
 SG_ CcAslButtnOnPress2 : 12|1@0+ (1,0) [0|1] "SED" Vector__XXX
 SG_ CcAslButtnOnOffCncl2 : 13|1@0+ (1,0) [0|1] "SED" Vector__XXX
 SG_ CcAslButtnOffCnclPres2 : 14|1@0+ (1,0) [0|1] "SED" Vector__XXX
 SG_ CcAslButtnIndxIncPres2 : 15|1@0+ (1,0) [0|1] "SED" Vector__XXX
 SG_ CcAslButtnIndxDecPres2 : 0|1@0+ (1,0) [0|1] "SED" Vector__XXX
 SG_ CcAslButtnDeny_B_Actl2 : 1|1@0+ (1,0) [0|1] "SED" Vector__XXX
 SG_ CcAslButtnCnclResPres2 : 2|1@0+ (1,0) [0|1] "SED" Vector__XXX
 SG_ CcAslButtnCnclPress2 : 3|1@0+ (1,0) [0|1] "SED" Vector__XXX
 SG_ AccButtnGapIncPress2 : 6|1@0+ (1,0) [0|1] "SED" Vector__XXX
 SG_ AccButtnGapDecPress2 : 7|1@0+ (1,0) [0|1] "SED" Vector__XXX

BO_ 1121 AllTerrainControlData_FD1: 8 GWM
 SG_ SelDrvMdeSwtch_No_Actl : 2|2@0+ (1,0) [0|3] "unitless"  ABS_ESC
 SG_ SelDrvMdeSwtch_D_Stat : 4|2@0+ (1,0) [0|3] "SED"  ABS_ESC
 SG_ SelDrvMdeCnt_D_Stat : 7|3@0+ (1,0) [0|7] "Counts"  ABS_ESC

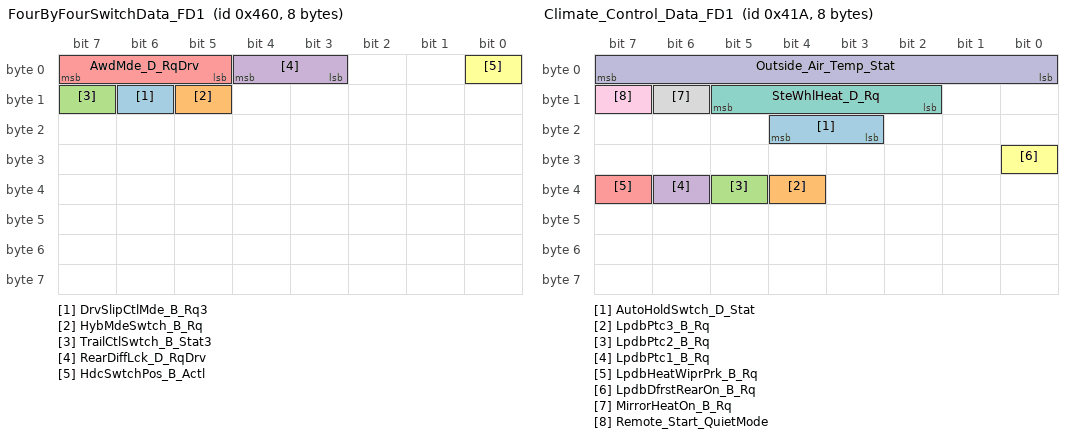
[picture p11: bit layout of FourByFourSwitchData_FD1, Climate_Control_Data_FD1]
BO_ 1120 FourByFourSwitchData_FD1: 8 GWM
 SG_ DrvSlipCtlMde_B_Rq3 : 14|1@0+ (1,0) [0|1] "SED"  ABS_ESC
 SG_ HybMdeSwtch_B_Rq : 13|1@0+ (1,0) [0|1] "SED"  PCM_HEV
 SG_ TrailCtlSwtch_B_Stat3 : 15|1@0+ (1,0) [0|1] "SED" Vector__XXX
 SG_ RearDiffLck_D_RqDrv : 4|2@0+ (1,0) [0|3] "SED"  PCM,TCCM
 SG_ AwdMde_D_RqDrv : 7|3@0+ (1,0) [0|7] "SED"  TCCM
 SG_ HdcSwtchPos_B_Actl : 0|1@0+ (1,0) [0|1] "SED"  ABS_ESC

BO_ 1050 Climate_Control_Data_FD1: 8 GWM
 SG_ AutoHoldSwtch_D_Stat : 20|2@0+ (1,0) [0|3] "SED"  ABS_ESC
 SG_ LpdbPtc3_B_Rq : 36|1@0+ (1,0) [0|1] "SED" Vector__XXX
 SG_ LpdbPtc2_B_Rq : 37|1@0+ (1,0) [0|1] "SED" Vector__XXX
 SG_ LpdbPtc1_B_Rq : 38|1@0+ (1,0) [0|1] "SED" Vector__XXX
 SG_ LpdbHeatWiprPrk_B_Rq : 39|1@0+ (1,0) [0|1] "SED" Vector__XXX
 SG_ LpdbDfrstRearOn_B_Rq : 24|1@0+ (1,0) [0|1] "SED"  ECM_Diesel
 SG_ SteWhlHeat_D_Rq : 13|4@0+ (1,0) [0|15] "SED" Vector__XXX
 SG_ MirrorHeatOn_B_Rq : 14|1@0+ (1,0) [0|1] "SED" Vector__XXX
 SG_ Remote_Start_QuietMode : 15|1@0+ (1,0) [0|1] "SED" Vector__XXX
 SG_ Outside_Air_Temp_Stat : 7|8@0+ (0.5,-40) [-40|86.5] "Degrees C"  VDM,ECM_Diesel,IPMA_ADAS,PCM,PCM_HEV,PSCM

BO_ 1137 Cluster_HEV_Data10_FD1: 8 PCM_HEV
 SG_ RngPerChrgAvg_L_Dsply : 7|12@0+ (0.1,0) [0|409.3] "km"  GWM

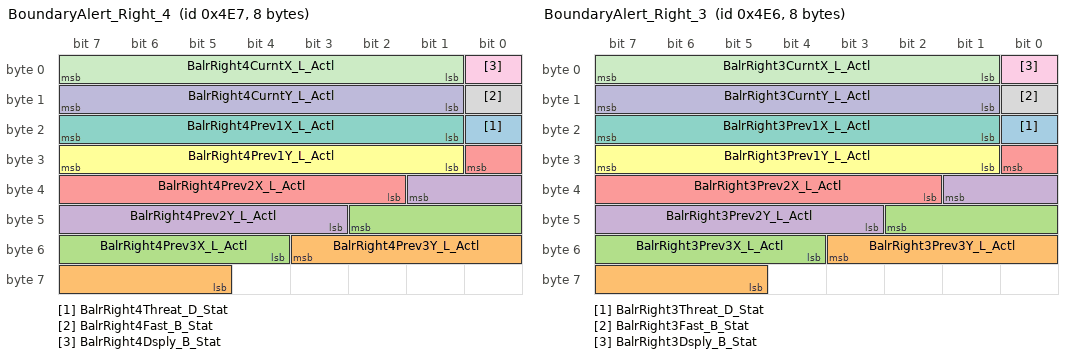
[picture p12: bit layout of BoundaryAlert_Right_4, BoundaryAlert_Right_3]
BO_ 1255 BoundaryAlert_Right_4: 8 IPMA_ADAS
 SG_ BalrRight4Threat_D_Stat : 16|1@0+ (1,0) [0|1] "SED"  GWM
 SG_ BalrRight4Prev3Y_L_Actl : 51|7@0+ (0.5,-32) [-32|31.5] "meter"  GWM
 SG_ BalrRight4Prev3X_L_Actl : 42|7@0+ (0.5,-32) [-32|31.5] "meter"  GWM
 SG_ BalrRight4Prev2Y_L_Actl : 33|7@0+ (0.5,-32) [-32|31.5] "meter"  GWM
 SG_ BalrRight4Prev2X_L_Actl : 24|7@0+ (0.5,-32) [-32|31.5] "meter"  GWM
 SG_ BalrRight4Prev1Y_L_Actl : 31|7@0+ (0.5,-32) [-32|31.5] "meter"  GWM
 SG_ BalrRight4Prev1X_L_Actl : 23|7@0+ (0.5,-32) [-32|31.5] "meter"  GWM
 SG_ BalrRight4Fast_B_Stat : 8|1@0+ (1,0) [0|1] "SED"  GWM
 SG_ BalrRight4Dsply_B_Stat : 0|1@0+ (1,0) [0|1] "SED"  GWM
 SG_ BalrRight4CurntY_L_Actl : 15|7@0+ (0.5,-32) [-32|31.5] "meter"  GWM
 SG_ BalrRight4CurntX_L_Actl : 7|7@0+ (0.5,-32) [-32|31.5] "meter"  GWM

BO_ 1254 BoundaryAlert_Right_3: 8 IPMA_ADAS
 SG_ BalrRight3Threat_D_Stat : 16|1@0+ (1,0) [0|1] "SED"  GWM
 SG_ BalrRight3Prev3Y_L_Actl : 51|7@0+ (0.5,-32) [-32|31.5] "meter"  GWM
 SG_ BalrRight3Prev3X_L_Actl : 42|7@0+ (0.5,-32) [-32|31.5] "meter"  GWM
 SG_ BalrRight3Prev2Y_L_Actl : 33|7@0+ (0.5,-32) [-32|31.5] "meter"  GWM
 SG_ BalrRight3Prev2X_L_Actl : 24|7@0+ (0.5,-32) [-32|31.5] "meter"  GWM
 SG_ BalrRight3Prev1Y_L_Actl : 31|7@0+ (0.5,-32) [-32|31.5] "meter"  GWM
 SG_ BalrRight3Prev1X_L_Actl : 23|7@0+ (0.5,-32) [-32|31.5] "meter"  GWM
 SG_ BalrRight3Fast_B_Stat : 8|1@0+ (1,0) [0|1] "SED"  GWM
 SG_ BalrRight3Dsply_B_Stat : 0|1@0+ (1,0) [0|1] "SED"  GWM
 SG_ BalrRight3CurntY_L_Actl : 15|7@0+ (0.5,-32) [-32|31.5] "meter"  GWM
 SG_ BalrRight3CurntX_L_Actl : 7|7@0+ (0.5,-32) [-32|31.5] "meter"  GWM

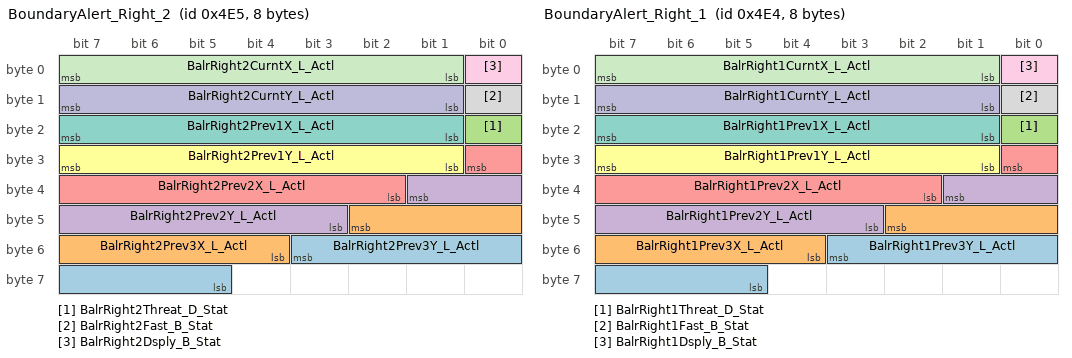
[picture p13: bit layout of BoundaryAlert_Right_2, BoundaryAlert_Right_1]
BO_ 1253 BoundaryAlert_Right_2: 8 IPMA_ADAS
 SG_ BalrRight2Prev3Y_L_Actl : 51|7@0+ (0.5,-32) [-32|31.5] "meter"  GWM
 SG_ BalrRight2Prev3X_L_Actl : 42|7@0+ (0.5,-32) [-32|31.5] "meter"  GWM
 SG_ BalrRight2Threat_D_Stat : 16|1@0+ (1,0) [0|1] "SED"  GWM
 SG_ BalrRight2Prev2Y_L_Actl : 33|7@0+ (0.5,-32) [-32|31.5] "meter"  GWM
 SG_ BalrRight2Prev2X_L_Actl : 24|7@0+ (0.5,-32) [-32|31.5] "meter"  GWM
 SG_ BalrRight2Prev1Y_L_Actl : 31|7@0+ (0.5,-32) [-32|31.5] "meter"  GWM
 SG_ BalrRight2Prev1X_L_Actl : 23|7@0+ (0.5,-32) [-32|31.5] "meter"  GWM
 SG_ BalrRight2Fast_B_Stat : 8|1@0+ (1,0) [0|1] "SED"  GWM
 SG_ BalrRight2Dsply_B_Stat : 0|1@0+ (1,0) [0|1] "SED"  GWM
 SG_ BalrRight2CurntY_L_Actl : 15|7@0+ (0.5,-32) [-32|31.5] "meter"  GWM
 SG_ BalrRight2CurntX_L_Actl : 7|7@0+ (0.5,-32) [-32|31.5] "meter"  GWM

BO_ 1252 BoundaryAlert_Right_1: 8 IPMA_ADAS
 SG_ BalrRight1Prev3Y_L_Actl : 51|7@0+ (0.5,-32) [-32|31.5] "meter"  GWM
 SG_ BalrRight1Prev3X_L_Actl : 42|7@0+ (0.5,-32) [-32|31.5] "meter"  GWM
 SG_ BalrRight1Threat_D_Stat : 16|1@0+ (1,0) [0|1] "SED"  GWM
 SG_ BalrRight1Prev2Y_L_Actl : 33|7@0+ (0.5,-32) [-32|31.5] "meter"  GWM
 SG_ BalrRight1Prev2X_L_Actl : 24|7@0+ (0.5,-32) [-32|31.5] "meter"  GWM
 SG_ BalrRight1Prev1Y_L_Actl : 31|7@0+ (0.5,-32) [-32|31.5] "meter"  GWM
 SG_ BalrRight1Prev1X_L_Actl : 23|7@0+ (0.5,-32) [-32|31.5] "meter"  GWM
 SG_ BalrRight1Fast_B_Stat : 8|1@0+ (1,0) [0|1] "SED"  GWM
 SG_ BalrRight1Dsply_B_Stat : 0|1@0+ (1,0) [0|1] "SED"  GWM
 SG_ BalrRight1CurntY_L_Actl : 15|7@0+ (0.5,-32) [-32|31.5] "meter"  GWM
 SG_ BalrRight1CurntX_L_Actl : 7|7@0+ (0.5,-32) [-32|31.5] "meter"  GWM

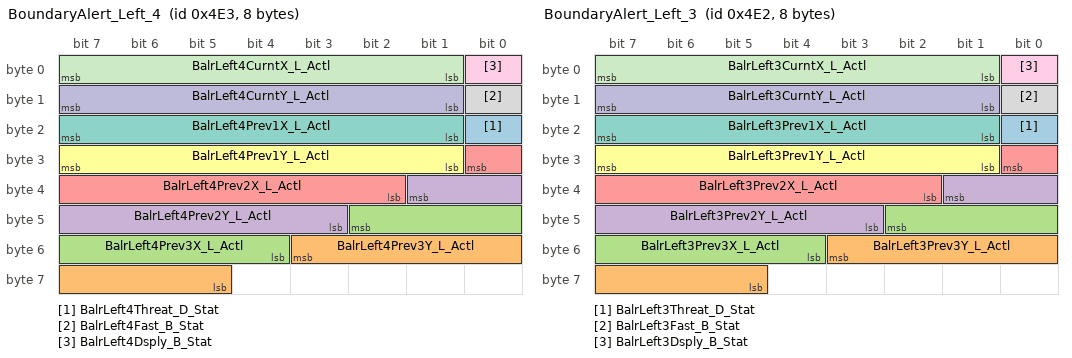
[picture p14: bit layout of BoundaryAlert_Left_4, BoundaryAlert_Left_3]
BO_ 1251 BoundaryAlert_Left_4: 8 IPMA_ADAS
 SG_ BalrLeft4Threat_D_Stat : 16|1@0+ (1,0) [0|1] "SED"  GWM
 SG_ BalrLeft4Prev3Y_L_Actl : 51|7@0+ (0.5,-32) [-32|31.5] "meter"  GWM
 SG_ BalrLeft4Prev3X_L_Actl : 42|7@0+ (0.5,-32) [-32|31.5] "meter"  GWM
 SG_ BalrLeft4Prev2Y_L_Actl : 33|7@0+ (0.5,-32) [-32|31.5] "meter"  GWM
 SG_ BalrLeft4Prev2X_L_Actl : 24|7@0+ (0.5,-32) [-32|31.5] "meter"  GWM
 SG_ BalrLeft4Prev1Y_L_Actl : 31|7@0+ (0.5,-32) [-32|31.5] "meter"  GWM
 SG_ BalrLeft4Prev1X_L_Actl : 23|7@0+ (0.5,-32) [-32|31.5] "meter"  GWM
 SG_ BalrLeft4Fast_B_Stat : 8|1@0+ (1,0) [0|1] "SED"  GWM
 SG_ BalrLeft4Dsply_B_Stat : 0|1@0+ (1,0) [0|1] "SED"  GWM
 SG_ BalrLeft4CurntY_L_Actl : 15|7@0+ (0.5,-32) [-32|31.5] "meter"  GWM
 SG_ BalrLeft4CurntX_L_Actl : 7|7@0+ (0.5,-32) [-32|31.5] "meter"  GWM

BO_ 1250 BoundaryAlert_Left_3: 8 IPMA_ADAS
 SG_ BalrLeft3Threat_D_Stat : 16|1@0+ (1,0) [0|1] "SED"  GWM
 SG_ BalrLeft3Prev3Y_L_Actl : 51|7@0+ (0.5,-32) [-32|31.5] "meter"  GWM
 SG_ BalrLeft3Prev3X_L_Actl : 42|7@0+ (0.5,-32) [-32|31.5] "meter"  GWM
 SG_ BalrLeft3Prev2Y_L_Actl : 33|7@0+ (0.5,-32) [-32|31.5] "meter"  GWM
 SG_ BalrLeft3Prev2X_L_Actl : 24|7@0+ (0.5,-32) [-32|31.5] "meter"  GWM
 SG_ BalrLeft3Prev1Y_L_Actl : 31|7@0+ (0.5,-32) [-32|31.5] "meter"  GWM
 SG_ BalrLeft3Prev1X_L_Actl : 23|7@0+ (0.5,-32) [-32|31.5] "meter"  GWM
 SG_ BalrLeft3Fast_B_Stat : 8|1@0+ (1,0) [0|1] "SED"  GWM
 SG_ BalrLeft3Dsply_B_Stat : 0|1@0+ (1,0) [0|1] "SED"  GWM
 SG_ BalrLeft3CurntY_L_Actl : 15|7@0+ (0.5,-32) [-32|31.5] "meter"  GWM
 SG_ BalrLeft3CurntX_L_Actl : 7|7@0+ (0.5,-32) [-32|31.5] "meter"  GWM

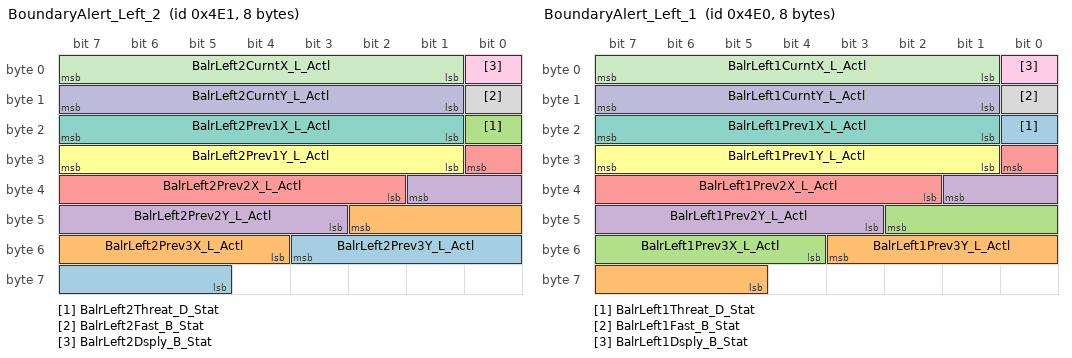
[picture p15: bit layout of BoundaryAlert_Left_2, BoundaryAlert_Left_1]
BO_ 1249 BoundaryAlert_Left_2: 8 IPMA_ADAS
 SG_ BalrLeft2Prev3Y_L_Actl : 51|7@0+ (0.5,-32) [-32|31.5] "meter"  GWM
 SG_ BalrLeft2Prev3X_L_Actl : 42|7@0+ (0.5,-32) [-32|31.5] "meter"  GWM
 SG_ BalrLeft2Threat_D_Stat : 16|1@0+ (1,0) [0|1] "SED"  GWM
 SG_ BalrLeft2Prev2Y_L_Actl : 33|7@0+ (0.5,-32) [-32|31.5] "meter"  GWM
 SG_ BalrLeft2Prev2X_L_Actl : 24|7@0+ (0.5,-32) [-32|31.5] "meter"  GWM
 SG_ BalrLeft2Prev1Y_L_Actl : 31|7@0+ (0.5,-32) [-32|31.5] "meter"  GWM
 SG_ BalrLeft2Prev1X_L_Actl : 23|7@0+ (0.5,-32) [-32|31.5] "meter"  GWM
 SG_ BalrLeft2Fast_B_Stat : 8|1@0+ (1,0) [0|1] "SED"  GWM
 SG_ BalrLeft2Dsply_B_Stat : 0|1@0+ (1,0) [0|1] "SED"  GWM
 SG_ BalrLeft2CurntY_L_Actl : 15|7@0+ (0.5,-32) [-32|31.5] "meter"  GWM
 SG_ BalrLeft2CurntX_L_Actl : 7|7@0+ (0.5,-32) [-32|31.5] "meter"  GWM

BO_ 1248 BoundaryAlert_Left_1: 8 IPMA_ADAS
 SG_ BalrLeft1Threat_D_Stat : 16|1@0+ (1,0) [0|1] "SED"  GWM
 SG_ BalrLeft1Prev3Y_L_Actl : 51|7@0+ (0.5,-32) [-32|31.5] "meter"  GWM
 SG_ BalrLeft1Prev3X_L_Actl : 42|7@0+ (0.5,-32) [-32|31.5] "meter"  GWM
 SG_ BalrLeft1Prev2Y_L_Actl : 33|7@0+ (0.5,-32) [-32|31.5] "meter"  GWM
 SG_ BalrLeft1Prev2X_L_Actl : 24|7@0+ (0.5,-32) [-32|31.5] "meter"  GWM
 SG_ BalrLeft1Prev1Y_L_Actl : 31|7@0+ (0.5,-32) [-32|31.5] "meter"  GWM
 SG_ BalrLeft1Prev1X_L_Actl : 23|7@0+ (0.5,-32) [-32|31.5] "meter"  GWM
 SG_ BalrLeft1Fast_B_Stat : 8|1@0+ (1,0) [0|1] "SED"  GWM
 SG_ BalrLeft1Dsply_B_Stat : 0|1@0+ (1,0) [0|1] "SED"  GWM
 SG_ BalrLeft1CurntY_L_Actl : 15|7@0+ (0.5,-32) [-32|31.5] "meter"  GWM
 SG_ BalrLeft1CurntX_L_Actl : 7|7@0+ (0.5,-32) [-32|31.5] "meter"  GWM

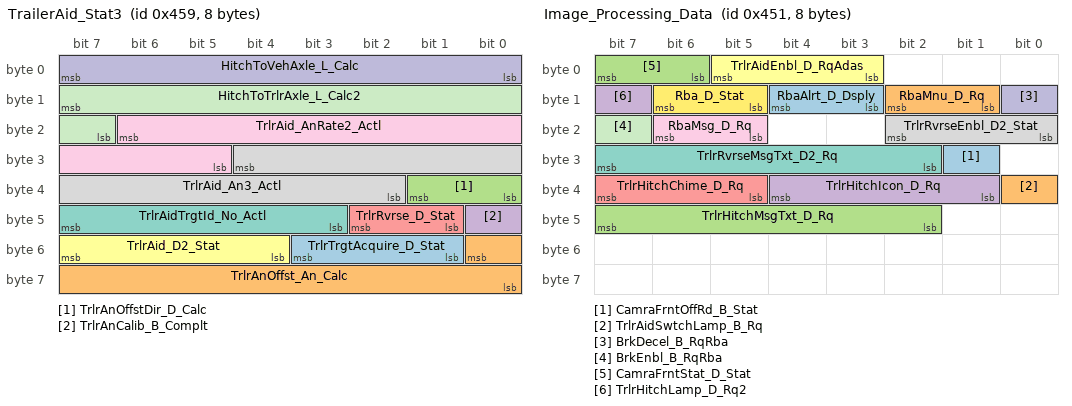
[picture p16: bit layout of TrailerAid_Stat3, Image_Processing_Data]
BO_ 1113 TrailerAid_Stat3: 8 IPMA_ADAS
 SG_ TrlrTrgtAcquire_D_Stat : 51|3@0+ (1,0) [0|7] "SED"  PSCM,GWM
 SG_ TrlrAnOffst_An_Calc : 48|9@0+ (0.1,0) [0|51.1] "degrees"  GWM
 SG_ TrlrAnOffstDir_D_Calc : 33|2@0+ (1,0) [0|3] "SED"  GWM
 SG_ TrlrAnCalib_B_Complt : 40|1@0+ (1,0) [0|1] "SED"  GWM
 SG_ TrlrRvrse_D_Stat : 42|2@0+ (1,0) [0|3] "SED"  GWM,PSCM
 SG_ TrlrAid_D2_Stat : 55|4@0+ (1,0) [0|15] "SED"  GWM,PSCM
 SG_ TrlrAidTrgtId_No_Actl : 47|5@0+ (1,0) [0|31] "unitless"  GWM,PSCM
 SG_ TrlrAid_An3_Actl : 28|11@0+ (0.125,-90) [-90|165.75] "degrees"  PSCM,GWM
 SG_ TrlrAid_AnRate2_Actl : 22|10@0+ (0.125,-50) [-50|77.75] "degrees/second"  PSCM,GWM
 SG_ HitchToVehAxle_L_Calc : 7|8@0+ (0.0127,-0.508) [-0.508|2.7178] "meter"  PSCM,GWM
 SG_ HitchToTrlrAxle_L_Calc2 : 15|9@0+ (0.0254,0) [0|12.9794] "meter"  GWM

BO_ 1105 Image_Processing_Data: 8 IPMA_ADAS
 SG_ CamraFrntOffRd_B_Stat : 25|1@0+ (1,0) [0|1] "SED"  GWM
 SG_ TrlrAidSwtchLamp_B_Rq : 32|1@0+ (1,0) [0|1] "SED"  GWM
 SG_ TrlrHitchMsgTxt_D_Rq : 47|6@0+ (1,0) [0|63] "SED"  GWM
 SG_ TrlrHitchIcon_D_Rq : 36|4@0+ (1,0) [0|15] "SED"  GWM
 SG_ TrlrHitchChime_D_Rq : 39|3@0+ (1,0) [0|7] "SED"  GWM
 SG_ TrlrAidEnbl_D_RqAdas : 5|3@0+ (1,0) [0|7] "SED"  GWM,PSCM
 SG_ TrlrRvrseMsgTxt_D2_Rq : 31|6@0+ (1,0) [0|63] "SED"  PSCM,GWM
 SG_ TrlrRvrseEnbl_D2_Stat : 18|3@0+ (1,0) [0|7] "SED"  PSCM,GWM
 SG_ RbaMsg_D_Rq : 22|2@0+ (1,0) [0|3] "SED"  GWM
 SG_ BrkDecel_B_RqRba : 8|1@0+ (1,0) [0|1] "SED"  GWM,ABS_ESC
 SG_ BrkEnbl_B_RqRba : 23|1@0+ (1,0) [0|1] "SED"  GWM,ABS_ESC
 SG_ Rba_D_Stat : 14|2@0+ (1,0) [0|3] "SED"  GWM
 SG_ RbaAlrt_D_Dsply : 12|2@0+ (1,0) [0|3] "SED"  GWM
 SG_ RbaMnu_D_Rq : 10|2@0+ (1,0) [0|3] "SED"  GWM
 SG_ CamraFrntStat_D_Stat : 7|2@0+ (1,0) [0|3] "SED"  GWM
 SG_ TrlrHitchLamp_D_Rq2 : 15|1@0+ (1,0) [0|1] "SED"  GWM

BO_ 938 ParkAid_Aud_Warn_Stat: 8 IPMA_ADAS
 SG_ SidePrkSnsR2_D_Stat : 59|4@0+ (1,0) [0|15] "SED"  GWM
 SG_ SidePrkSnsR1_D_Stat : 63|4@0+ (1,0) [0|15] "SED"  GWM
 SG_ SidePrkSnsL2_D_Stat : 51|4@0+ (1,0) [0|15] "SED"  GWM
 SG_ ApaMde_D_Stat : 23|3@0+ (1,0) [0|7] "SED"  GWM
 SG_ ApaActvSd_D_Actl : 14|2@0+ (1,0) [0|3] "SED"  GWM
 SG_ PrkAidSwtch_B_Stat : 8|1@0+ (1,0) [0|1] "SED"  GWM
 SG_ ApaMde_D_Avail : 12|4@0+ (1,0) [0|15] "SED"  GWM
 SG_ PrkAidSnsFrCrnr_D_Stat : 47|4@0+ (1,0) [0|15] "SED"  GWM
 SG_ PrkAidSnsFrCntr_D_Stat : 35|4@0+ (1,0) [0|15] "SED"  GWM
 SG_ PrkAidSnsFlCrnr_D_Stat : 27|4@0+ (1,0) [0|15] "SED"  GWM
 SG_ PrkAidSnsFlCntr_D_Stat : 31|4@0+ (1,0) [0|15] "SED"  GWM
 SG_ PrkBrkEl_B_RqFap : 20|1@0+ (1,0) [0|1] "SED"  GWM,ABS_ESC
 SG_ RpaChime_D_Rq : 7|4@0+ (1,0) [0|15] "SED"  GWM
 SG_ FpaChime_D_Rq : 3|4@0+ (1,0) [0|15] "SED"  GWM
 SG_ PrkAidMsgTxt_D_Rq : 19|4@0+ (1,0) [0|15] "SED"  GWM,PSCM
 SG_ SidePrkSnsL1_D_Stat : 55|4@0+ (1,0) [0|15] "SED"  GWM
 SG_ PrkAidAudioMute_B_Rq : 15|1@0+ (1,0) [0|1] "SED"  GWM

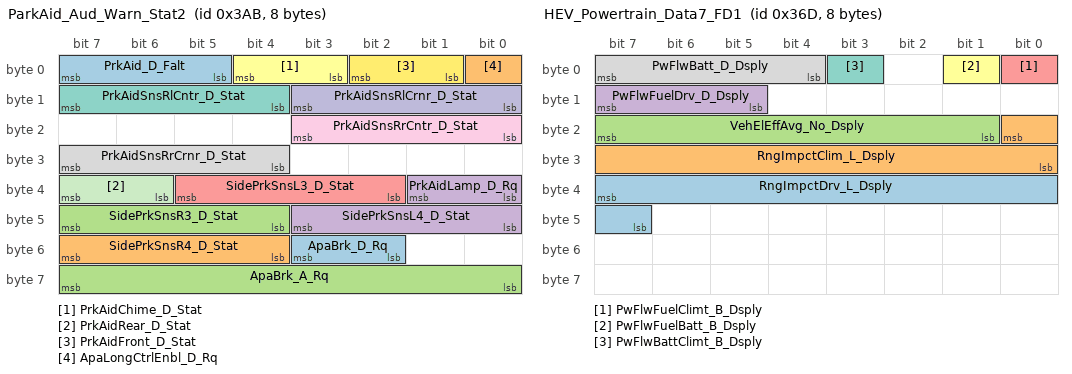
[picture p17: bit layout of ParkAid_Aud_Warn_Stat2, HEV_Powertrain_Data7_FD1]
BO_ 939 ParkAid_Aud_Warn_Stat2: 8 IPMA_ADAS
 SG_ ApaBrk_D_Rq : 51|2@0+ (1,0) [0|3] "SED"  GWM
 SG_ SidePrkSnsR4_D_Stat : 55|4@0+ (1,0) [0|15] "SED"  GWM
 SG_ SidePrkSnsR3_D_Stat : 47|4@0+ (1,0) [0|15] "SED"  GWM
 SG_ SidePrkSnsL4_D_Stat : 43|4@0+ (1,0) [0|15] "SED"  GWM
 SG_ SidePrkSnsL3_D_Stat : 37|4@0+ (1,0) [0|15] "SED"  GWM
 SG_ PrkAidChime_D_Stat : 4|2@0+ (1,0) [0|3] "SED"  GWM
 SG_ PrkAidSnsRlCntr_D_Stat : 15|4@0+ (1,0) [0|15] "SED"  GWM
 SG_ PrkAidSnsRrCrnr_D_Stat : 31|4@0+ (1,0) [0|15] "SED"  GWM
 SG_ PrkAidSnsRrCntr_D_Stat : 19|4@0+ (1,0) [0|15] "SED"  GWM
 SG_ PrkAidSnsRlCrnr_D_Stat : 11|4@0+ (1,0) [0|15] "SED"  GWM
 SG_ PrkAidRear_D_Stat : 39|2@0+ (1,0) [0|3] "SED"  GWM
 SG_ PrkAidFront_D_Stat : 2|2@0+ (1,0) [0|3] "SED"  GWM
 SG_ PrkAid_D_Falt : 7|3@0+ (1,0) [0|7] "SED"  GWM
 SG_ ApaLongCtrlEnbl_D_Rq : 0|1@0+ (1,0) [0|1] "SED"  ABS_ESC,ECM_Diesel,PCM,PCM_HEV,TCM_DSL,GWM
 SG_ ApaBrk_A_Rq : 63|8@0+ (0.05,-12.75) [-12.75|0] "m/sec^2"  ABS_ESC,ECM_Diesel,PCM,PCM_HEV,GWM
 SG_ PrkAidLamp_D_Rq : 33|2@0+ (1,0) [0|3] "SED"  GWM

BO_ 937 ParkAid_Data_2: 8 IPMA_ADAS
 SG_ Veh_V_RqFap : 31|8@0+ (0.1,0) [0|25.5] "km/h"  ECM_Diesel,PCM,PCM_HEV
 SG_ TrnRngDRqFap_No_Cs : 23|8@0+ (1,0) [0|255] "unitless"  PCM,PCM_HEV,TCM_DSL
 SG_ TrnRngDRqFap_No_Cnt : 15|4@0+ (1,0) [0|15] "unitless"  PCM,PCM_HEV,TCM_DSL
 SG_ TrnRng_D_RqFap : 11|3@0+ (1,0) [0|7] "SED"  ECM_Diesel,PCM,PCM_HEV,TCM_DSL,GWM
 SG_ FapLcDistToObj_L_Actl : 7|8@0+ (0.01,0) [0|2.53] "meter"  ECM_Diesel,PCM,PCM_HEV

BO_ 936 ParkAid_Data: 8 IPMA_ADAS
 SG_ ApaButtnPrssd_B_Stat : 58|1@0+ (1,0) [0|1] "SED"  PSCM
 SG_ SAPPStatusCoding : 7|8@0+ (1,0) [0|255] "unitless"  GWM
 SG_ ApaSys_D_Stat : 61|3@0+ (1,0) [0|7] "SED"  PSCM,GWM,ECM_Diesel,PCM,PCM_HEV
 SG_ ApaSteWhl_D_RqDrv : 63|2@0+ (1,0) [0|3] "SED"  GWM
 SG_ ApaSteScanMde_D_Stat : 49|2@0+ (1,0) [0|3] "SED"  GWM
 SG_ ApaSelSapp_D_Stat : 51|2@0+ (1,0) [0|3] "SED"  GWM
 SG_ ApaSelPpa_D_Stat : 53|2@0+ (1,0) [0|3] "SED"  GWM
 SG_ ApaSelPoa_D_Stat : 55|2@0+ (1,0) [0|3] "SED"  GWM
 SG_ ApaScan_D_Stat : 41|2@0+ (1,0) [0|3] "SED"  GWM
 SG_ ApaLongCtl_D_RqDrv : 44|3@0+ (1,0) [0|7] "SED"  GWM
 SG_ ApaGearShif_D_RqDrv : 47|3@0+ (1,0) [0|7] "SED"  GWM
 SG_ ApaActvSide2_D_Stat : 33|2@0+ (1,0) [0|3] "SED"  GWM
 SG_ ApaAcsy_D_RqDrv : 36|3@0+ (1,0) [0|7] "SED"  GWM
 SG_ ApaTrgtDist_D_Stat : 11|4@0+ (1,0) [0|15] "SED"  GWM
 SG_ ApaMsgTxt_D_Rq : 15|4@0+ (1,0) [0|15] "SED"  GWM
 SG_ ApaChime_D_Rq : 39|3@0+ (1,0) [0|7] "SED"  GWM
 SG_ EPASExtAngleStatReq : 23|1@0+ (1,0) [0|1] "SED"  PSCM,GWM,ABS_ESC
 SG_ ExtSteeringAngleReq2 : 22|15@0+ (0.1,-1000) [-1000|2276.5] "Degrees"  GWM,PSCM

BO_ 877 HEV_Powertrain_Data7_FD1: 8 PCM_HEV
 SG_ RngImpctDrv_L_Dsply : 39|9@0+ (1,-255) [-255|256] "km"  GWM
 SG_ RngImpctClim_L_Dsply : 16|9@0+ (1,-255) [-255|256] "km"  GWM
 SG_ VehElEffAvg_No_Dsply : 23|7@0+ (10,-100) [-100|1150] "wattHr/km"  GWM
 SG_ PwFlwFuelDrv_D_Dsply : 15|3@0+ (1,0) [0|7] "SED"  GWM
 SG_ PwFlwFuelClimt_B_Dsply : 0|1@0+ (1,0) [0|1] "SED"  GWM
 SG_ PwFlwFuelBatt_B_Dsply : 1|1@0+ (1,0) [0|1] "SED"  GWM
 SG_ PwFlwBattClimt_B_Dsply : 3|1@0+ (1,0) [0|1] "SED"  GWM
 SG_ PwFlwBatt_D_Dsply : 7|4@0+ (1,0) [0|15] "SED"  GWM

BO_ 589 Battery_Traction_5_FD1: 8 GWM
 SG_ BattTrac2_Pw_LimChrg : 31|13@0+ (50,0) [0|409550] "watts"  PCM_HEV
 SG_ BattTrac2_Pw_LimDchrg : 34|13@0+ (50,0) [0|409550] "watts"  PCM_HEV
 SG_ BattTrac2_Pw_DchrgInst : 53|13@0+ (50,0) [0|409550] "watts"  PCM_HEV
 SG_ BattTrac2_Pw_ChrgInst : 7|13@0+ (50,0) [0|409550] "watts"  PCM_HEV

BO_ 588 Battery_Traction_4_FD1: 8 GWM
 SG_ BattTracSoc2_Pc_Actl : 29|14@0+ (0.01,0) [0|163.81] "%"  SOBDMC_HPCM_FD1,PCM_HEV
 SG_ BattTrac_Te_Actl : 9|10@0+ (0.5,-50) [-50|460.5] "degC"  SOBDMC_HPCM_FD1,PCM_HEV

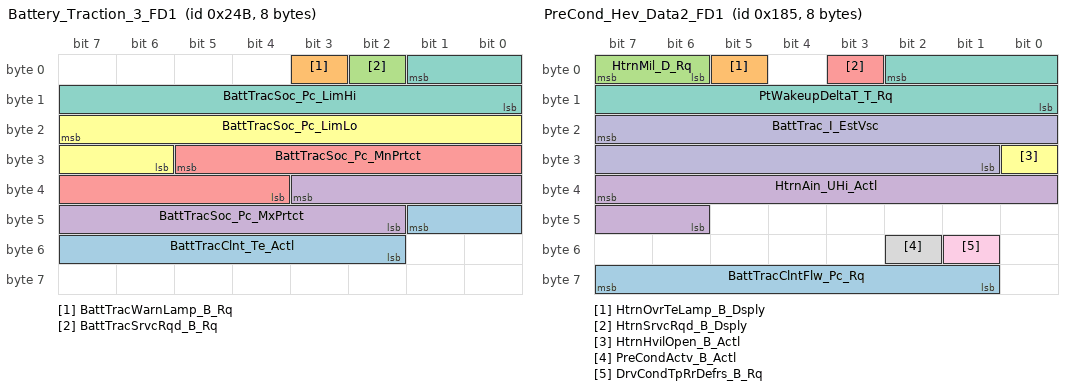
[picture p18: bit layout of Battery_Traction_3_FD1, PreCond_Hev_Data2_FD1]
BO_ 587 Battery_Traction_3_FD1: 8 GWM
 SG_ BattTracClnt_Te_Actl : 41|8@0+ (0.5,-60) [-60|67.5] "degC"  SOBDMC_HPCM_FD1
 SG_ BattTracWarnLamp_B_Rq : 3|1@0+ (1,0) [0|1] "SED" Vector__XXX
 SG_ BattTracSrvcRqd_B_Rq : 2|1@0+ (1,0) [0|1] "SED" Vector__XXX
 SG_ BattTracSoc_Pc_MxPrtct : 35|10@0+ (0.1,0) [0|100] "%"  SOBDMC_HPCM_FD1,PCM_HEV
 SG_ BattTracSoc_Pc_MnPrtct : 29|10@0+ (0.1,0) [0|100] "%"  PCM_HEV
 SG_ BattTracSoc_Pc_LimLo : 23|10@0+ (0.1,0) [0|100] "%"  PCM_HEV
 SG_ BattTracSoc_Pc_LimHi : 1|10@0+ (0.1,0) [0|100] "%"  PCM_HEV

BO_ 389 PreCond_Hev_Data2_FD1: 8 SOBDMC_HPCM_FD1
 SG_ BattTracClntFlw_Pc_Rq : 63|7@0+ (1,0) [0|127] "percent"  GWM
 SG_ HtrnOvrTeLamp_B_Dsply : 5|1@0+ (1,0) [0|1] "SED"  GWM
 SG_ HtrnMil_D_Rq : 7|2@0+ (1,0) [0|3] "SED"  GWM
 SG_ HtrnAin_UHi_Actl : 39|10@0+ (0.5,0) [0|510.5] "volt"  GWM,PCM_HEV
 SG_ HtrnSrvcRqd_B_Dsply : 3|1@0+ (1,0) [0|1] "SED"  GWM
 SG_ HtrnHvilOpen_B_Actl : 24|1@0+ (1,0) [0|1] "SED"  GWM,PCM_HEV
 SG_ PtWakeupDeltaT_T_Rq : 2|11@0+ (1,0) [0|2045] "minute"  GWM
 SG_ PreCondActv_B_Actl : 50|1@0+ (1,0) [0|1] "SED"  GWM
 SG_ DrvCondTpRrDefrs_B_Rq : 49|1@0+ (1,0) [0|1] "SED"  GWM
 SG_ BattTrac_I_EstVsc : 23|15@0+ (0.05,-750) [-750|888.25] "Amps"  GWM

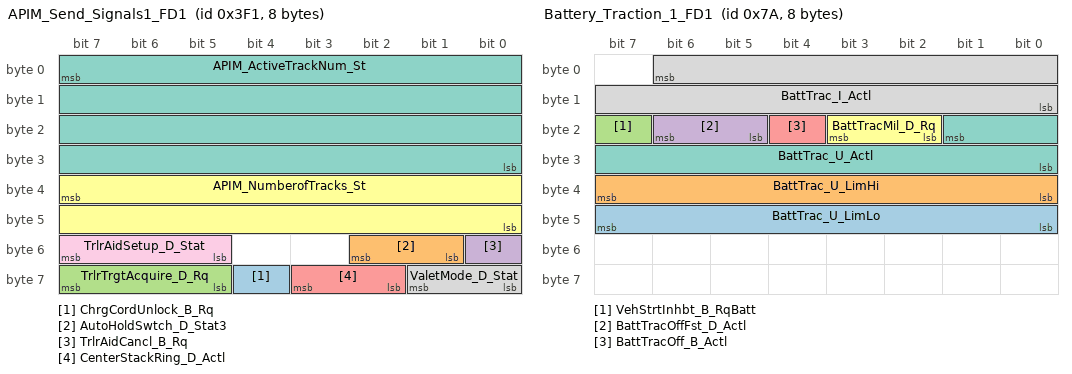
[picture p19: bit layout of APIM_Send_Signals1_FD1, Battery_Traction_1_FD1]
BO_ 1009 APIM_Send_Signals1_FD1: 8 GWM
 SG_ ChrgCordUnlock_B_Rq : 60|1@0+ (1,0) [0|1] "SED" Vector__XXX
 SG_ AutoHoldSwtch_D_Stat3 : 50|2@0+ (1,0) [0|3] "SED"  ABS_ESC
 SG_ TrlrTrgtAcquire_D_Rq : 63|3@0+ (1,0) [0|7] "SED" Vector__XXX
 SG_ TrlrAidCancl_B_Rq : 48|1@0+ (1,0) [0|1] "SED"  IPMA_ADAS,PSCM
 SG_ CenterStackRing_D_Actl : 59|2@0+ (1,0) [0|3] "SED" Vector__XXX
 SG_ APIM_NumberofTracks_St : 39|16@0+ (1,0) [0|65535] "unitless" Vector__XXX
 SG_ APIM_ActiveTrackNum_St : 7|32@0+ (1,0) [0|4294967295] "unitless" Vector__XXX
 SG_ ValetMode_D_Stat : 57|2@0+ (1,0) [0|3] "SED" Vector__XXX
 SG_ TrlrAidSetup_D_Stat : 55|3@0+ (1,0) [0|7] "SED" Vector__XXX

BO_ 360 Gear_Shift_by_Wire_2_FD1: 8 GWM
 SG_ GsmSrvcRqd_B_Rq : 23|1@0+ (1,0) [0|1] "SED" Vector__XXX
 SG_ TrnGearPwmFalt_B_Actl : 15|1@0+ (1,0) [0|1] "SED"  PCM,PCM_HEV
 SG_ GearButtnStuck_B_Actl : 14|1@0+ (1,0) [0|1] "SED"  PCM,PCM_HEV,TCM_DSL

BO_ 122 Battery_Traction_1_FD1: 8 GWM
 SG_ BattTrac_U_LimLo : 47|8@0+ (2,0) [0|510] "volt"  SOBDMC_HPCM_FD1,PCM_HEV
 SG_ BattTrac_U_LimHi : 39|8@0+ (2,0) [0|510] "volt"  SOBDMC_HPCM_FD1,PCM_HEV
 SG_ VehStrtInhbt_B_RqBatt : 23|1@0+ (1,0) [0|1] "SED"  SOBDMC_HPCM_FD1,PCM_HEV
 SG_ BattTracOffFst_D_Actl : 22|2@0+ (1,0) [0|3] "SED"  SOBDMC_HPCM_FD1,PCM_HEV
 SG_ BattTracOff_B_Actl : 20|1@0+ (1,0) [0|1] "SED"  SOBDMC_HPCM_FD1,PCM_HEV
 SG_ BattTracMil_D_Rq : 19|2@0+ (1,0) [0|3] "SED"  PCM_HEV
 SG_ BattTrac_U_Actl : 17|10@0+ (0.5,0) [0|510.5] "Volts"  SOBDMC_HPCM_FD1,PCM_HEV
 SG_ BattTrac_I_Actl : 6|15@0+ (0.05,-750) [-750|888.25] "Amps"  SOBDMC_HPCM_FD1,PCM_HEV

BO_TX_BU_ 1086 : ECM_Diesel,PCM,PCM_HEV;
BO_TX_BU_ 1071 : ECM_Diesel,PCM,PCM_HEV;
BO_TX_BU_ 1069 : ECM_Diesel,PCM,PCM_HEV;
BO_TX_BU_ 1060 : ECM_Diesel,PCM,PCM_HEV;
BO_TX_BU_ 1057 : ECM_Diesel,PCM,PCM_HEV;
BO_TX_BU_ 1055 : ECM_Diesel,PCM,PCM_HEV;
BO_TX_BU_ 517 : ECM_Diesel,PCM,PCM_HEV;
BO_TX_BU_ 516 : ECM_Diesel,PCM,PCM_HEV;
BO_TX_BU_ 514 : ECM_Diesel,PCM,PCM_HEV;
BO_TX_BU_ 512 : ECM_Diesel,PCM,PCM_HEV;
BO_TX_BU_ 380 : ECM_Diesel,PCM;
BO_TX_BU_ 377 : ECM_Diesel,PCM,PCM_HEV;
BO_TX_BU_ 376 : ECM_Diesel,PCM,PCM_HEV;
BO_TX_BU_ 359 : ECM_Diesel,PCM,PCM_HEV;
BO_TX_BU_ 358 : ECM_Diesel,PCM,PCM_HEV;
BO_TX_BU_ 357 : ECM_Diesel,PCM,PCM_HEV;
BO_TX_BU_ 342 : ECM_Diesel,PCM,PCM_HEV;
BO_TX_BU_ 71 : ECM_Diesel,PCM,PCM_HEV;
CM_ SG_ 1086 EngOil_P_Actl "Signal not transmitted on HEV & Diesel programs";
CM_ SG_ 1086 EngIpcDsplyCht_Te_Actl "Signal not transmitted on HEV & Diesel programs";
CM_ SG_ 1086 EngIpcDsplyAfr_Rt_Actl "Signal not transmitted on HEV & Diesel programs";
CM_ SG_ 1086 EngMnfld_P_Actl "Signal not transmitted on Diesel programs";
CM_ SG_ 1086 ElLoadCtl_D_Rq "Signal not transmitted on HEV variants.";
CM_ SG_ 1071 CluPdl_PcRate_Actl "Signal not transmitted on HEV and Gas variants.";
CM_ SG_ 1071 CluPdlPosPcMeas_D_Qf "Signal not transmitted on HEV and Gas variants.";
CM_ SG_ 1071 CluPdlPos_Pc_Meas "Signal not transmitted on HEV and Gas variants.";
CM_ SG_ 1071 EngAoutIdl_N_Ntrl "Signal not transmitted on HEV variants and diesel.";
CM_ SG_ 1069 ReFuelSysStat_D_Dsply "Signal not transmitted on Gas & Diesel variants";
CM_ SG_ 1069 SlMde_D_Stat "IPC and HUD_ADV Receve from HS3 FGW 0x42D, not HS3 0x38A, MSG DCR 506. Signal not transmitted on Gas & HEV variants";
CM_ SG_ 1069 SlMde_D_RqDsply "IPC and HUD_ADV Receve from HS3 FGW 0x42D, not HS3 0x38A, MSG DCR 506. Signal not transmitted on Gas & HEV variants";
CM_ SG_ 1069 IsaOffst_D_Stat "Signal not transmitted on Gas & HEV variants";
CM_ SG_ 1069 ObdWarmUp_B_Complt "Signal not transmitted on diesel variants.";
CM_ SG_ 1069 EngMsgTxt_D_Rq "Signal not transmitted on diesel variants.";
CM_ SG_ 1069 EngClnt_Te_ActlDiag "Signal not transmitted on gas variants.";
CM_ SG_ 1069 EngLoad_Pc_CalcDiag "Signal not transmitted on gas variants.";
CM_ SG_ 1069 ApedPos_Pc_ActlDiag "Signal not transmitted on gas variants.";
CM_ SG_ 1060 RearDiffOilTeWarn_B_Rq "Signal not transmitted on HEV & Diesel programs";
CM_ SG_ 1060 RearDiffOil_Te_Actl "Signal not transmitted on HEV & Diesel programs";
CM_ SG_ 1057 FohEng_D_Rq "Signal not transmitted on vehicles that do not have the fuel operated heater feature. Signal not transmitted on HEV programs";
CM_ SG_ 1057 EngIdlShutDown_D_Stat "Signal not transmitted on diesel variants.";
CM_ SG_ 1057 FUEL_ALCOHOL_PERCNT "signal not transmitted on diesel and HEV variants.";
CM_ SG_ 1057 TrnTotTq_Rt_Est "Signal not transmitted on gas and HEV variants.";
CM_ SG_ 1057 TrnTotLss_Tq_Est "Signal not transmitted on gas and HEV variants.";
CM_ SG_ 1057 VehVLimStat_D_Actl "Signal not transmitted on gas and HEV variants.";
CM_ SG_ 1057 VehVLimActv_B_Actl "Signal not transmitted on gas and HEV variants.";
CM_ SG_ 562 GearNtrl_No_Cs "Powersplit HEVs with HF45, HPCM will Tx  this message.  For all other programs it will be Tx by PCM or TCM. ";
CM_ SG_ 562 GearNtrl_No_Cnt "Powersplit HEVs with HF45, HPCM will Tx  this message.  For all other programs it will be Tx by PCM or TCM. ";
CM_ SG_ 516 EngAoutNActl_D_QF "Signal not transmitted on Gas & HEV variants";
CM_ SG_ 516 EngAout3_N_Actl "Signal not transmitted on gas and diesel variants.";
CM_ SG_ 516 ApedPos_Pc_ActlArb "ABSGenSigTimeoutTime=1000";
CM_ SG_ 516 ApedPosPcActl_No_Cnt "Signal not transmitted on gas and diesel variants.";
CM_ SG_ 516 ApedPosPcActl_No_Cs "Signal not transmitted on gas and diesel variants.";
CM_ SG_ 514 GearRvrse_D_Actl "Do not implement GearRvrse_D_Actl  until eTracker 8804151 is approved, 11/24/09";
CM_ SG_ 512 PrplWhlTotTqRq_No_Cs "Signal not transmitted on gas & Diesel variants.";
CM_ SG_ 512 PrplWhlTotTqRq_No_Cnt "Signal not transmitted on gas & Diesel variants.";
CM_ SG_ 512 PtDrvMde_D_Stat "Signal not transmitted on Gas & HEV variants.";
CM_ SG_ 380 EngExhBrkOnLamp_B_Rq "Signal not transmitted on Gas variants";
CM_ SG_ 380 EngExhBrkAutoLamp_B_Rq "Signal not transmitted on Gas variants";
CM_ SG_ 380 EngAout_N_MxAllw "Signal not transmitted on Gas variants";
CM_ SG_ 380 EngExhBrkMde_D_Actl "Signal not transmitted on Gas variants";
CM_ SG_ 377 HvacAirFullOut_B_Rq "Signal not transmitted on diesel variant";
CM_ SG_ 377 FuelFlw_Vl_Dsply "Signal not transmitted on diesel variants.";
CM_ SG_ 377 FuelFillInlet_B_Dsply "Signal not transmitted on diesel variants.";
CM_ SG_ 377 OdoCount "Signal not transmitted on diesel variants.";
CM_ SG_ 377 EngOilLife_Pc_Actl "Signal not transmitted on diesel variants.";
CM_ SG_ 377 FuelFilterLamp_B_Dsply "Signal not transmitted on Gas & HEV variants";
CM_ SG_ 377 AirCondRec_B_Rq "Signal not transmitted on diesel variants.";
CM_ SG_ 377 AirCondClutch_B_Stats "Signal not transmitted on diesel variants.";
CM_ SG_ 376 GasPrtc_D_RqDsply "Signal not transmitted on HEV & Diesel variants.";
CM_ SG_ 376 EngAout_Aa_Actl "Signal not transmitted on HEV variants.";
CM_ SG_ 376 AslChime_B_Rq "Signal not transmitted on HEV variants.";
CM_ SG_ 376 HvacHtrCore2_Te_Actl "Signal not transmitted on Gas & Diesel variants";
CM_ SG_ 376 EcssLamp_D_RqDsply "Signal not transmitted on Gas & HEV variants";
CM_ SG_ 376 AirAmb_Te_Actl "Signal not transmitted on Gas variants";
CM_ SG_ 359 PrplWhlRgenMn_Tq_Actl "Signal not transmitted on Gas & Diesel variants";
CM_ SG_ 359 ElPw_D_StatStrtStop "Signal not transmitted on HEV variants.";
CM_ SG_ 359 TrnAin_Tq_Actl "Signal not transmitted on HEV variances.";
CM_ SG_ 359 PlgActvArb_B_Actl "Only supported on PHEV programs.  PlgActvArb_B_Actl HPCM will Tx on Powersplit PHEV’s,  On MHT PHEVs the PCM_HEV will Tx and HPCM will Rx. 
";
CM_ SG_ 359 TrnAinTq_D_Qf "Signal not transmitted on HEV variances.";
CM_ SG_ 358 StopStrtStdby_D_Indic "Signal not transmitted on HEV variants.";
CM_ SG_ 358 StopStrtIODTxt_D_Rq "Signal not transmitted on HEV variants.";
CM_ SG_ 358 StopStrtDrvMde_D_Indic "Signal not transmitted on HEV variants.";
CM_ SG_ 358 StopStrtMsgTxt_D_Rq "Signal not transmitted on HEV variants.";
CM_ SG_ 358 HiElPwInhbt_B_Stat "Signal not transmitted on HEV programs";
CM_ SG_ 358 AutoStopPtDelta_I_Est "Signal not transmitted on HEV variants. ";
CM_ SG_ 357 BpedDrvAppl_D_Actl "CCMGenSigTimeoutTime=1000";
CM_ SG_ 357 CcStat_D_Actl "ABSGenSigTimeoutTime=1000";
CM_ SG_ 357 EngAout_N_MnAllw "Signal not transmitted on Gas & Diesel variants.";
CM_ SG_ 357 AccStopMde_D_Rq "ABSGenSigTimeoutTime=1000";
CM_ SG_ 342 EngOvrhtMitgActv_D_Ind "Signal not transmitted on diesel.";
CM_ SG_ 342 EngGoutLss_Tq_Est "Signal not transmitted on gas and diesel variants.";
CM_ SG_ 342 EngOil_Te_Actl "Signal not transmitted on HEV variants.";
CM_ BO_ 71 "Provide target function info. to control function of PATS";
CM_ SG_ 954 GenericSwtch2_No_Actl "U625 Police Wig Wag feature";
CM_ SG_ 129 SelDrvMdeSwtch3_D_Stat4 "ECM_HEV does not support or Transmit signal.";
CM_ SG_ 935 SodRight_D_Stat "IPCGenSigTimeoutTime=1600";
CM_ SG_ 935 Side_Detect_R_Illum "DDMGenSigTimeoutTime=2000";
CM_ SG_ 935 SodSnsRight_D_Stat "IPCGenSigTimeoutTime=1600";
CM_ SG_ 935 SodAlrtRight_D_Stat "DDMGenSigTimeoutTime=2000";
CM_ SG_ 1112 BattTracClntPmp_D_Stat "48V mHEV: ECM_HEVDSL is Tx,  MHT HEV: PCM_HEV is Tx,  Powersplit HEV: SOBDMC_HPCM is Tx";
CM_ SG_ 1050 Outside_Air_Temp_Stat "Filtered value, i.e. same as disply for customer";
CM_ BO_ 1009 "APIM Tx";
CM_ SG_ 1009 CenterStackRing_D_Actl "The Center Stack sends the CPLR a signal to turn On or Off the light Ring, This is a customer selectable preference switch";
CM_ SG_ 1009 APIM_NumberofTracks_St "Object NumberofTracks";
CM_ SG_ 1009 APIM_ActiveTrackNum_St "Object.ActiveTrackNum";
CM_ SG_ 360 GsmSrvcRqd_B_Rq "Signal not transmitted on vehicles that do not have shift by wire.";
CM_ SG_ 360 TrnGearPwmFalt_B_Actl "Signal not transmitted on vehicles that do not have shift by wire.";
CM_ SG_ 360 GearButtnStuck_B_Actl "Signal not transmitted on vehicles that do not have shift by wire.";
BA_DEF_ SG_  "U_CD542_MY2021_Rx" ENUM  "No","Yes";
BA_DEF_ SG_  "U_CD542_MY2021_Tx" ENUM  "No","Yes";
BA_DEF_ SG_  "U_U55X_MY2022_Tx" ENUM  "No","Yes";
BA_DEF_ BO_  "OvtpPushApplication" ENUM  "FALSE","TRUE";
BA_DEF_ SG_  "ECGUsedRxSignal" ENUM  "No","Yes";
BA_DEF_ SG_  "ECGUsedTxSignal" ENUM  "No","Yes";
BA_DEF_ BO_  "VFrameFormat" ENUM  "StandardCAN","ExtendedCAN","reserved","reserved","reserved","reserved","reserved","reserved","reserved","reserved","reserved","reserved","reserved","reserved","StandardCAN_FD","ExtendedCAN_FD";
BA_DEF_ BO_  "FrameRouting" STRING ;
BA_DEF_ BO_  "FrameGatewayNetwork" STRING ;
BA_DEF_ BO_  "NetworkInitialization" ENUM  "No","Yes";
BA_DEF_ BO_  "FrameGatewayId" HEX 0 1407;
BA_DEF_ BO_  "EventRateOfChange" INT 10 10000;
BA_DEF_ BO_  "GenMsgStartDelayTime" INT 0 10000;
BA_DEF_ BO_  "GenMsgNrOfRepetition" INT 0 100;
BA_DEF_ BO_  "GenMsgDelayTime" INT 0 1000;
BA_DEF_ BO_  "GenMsgCycleTime" INT 0 100000;
BA_DEF_ BO_  "GenMsgSendType" ENUM  "FixedPeriodic","Event","EnabledPeriodic","NotUsed","NotUsed","EventPeriodic","NotUsed","NotUsed","NoMsgSendType";
BA_DEF_ SG_  "U_T6_MCA_MY2020_Tx" ENUM  "No","Yes";
BA_DEF_ SG_  "U_P702_MY2021_Tx" ENUM  "No","Yes";
BA_DEF_ SG_  "U_CX727_MY2021_Tx" ENUM  "No","Yes";
BA_DEF_ SG_  "U_T6_MCA_MY2020_Rx" ENUM  "No","Yes";
BA_DEF_ SG_  "U_P702_MY2021_Rx" ENUM  "No","Yes";
BA_DEF_ SG_  "U_CX727_MY2021_Rx" ENUM  "No","Yes";
BA_DEF_ SG_  "GenSigStartValue" HEX 0 268435455;
BA_DEF_ SG_  "MetaData" ENUM  "No","Yes";
BA_DEF_ SG_  "ContentDependant" ENUM  "No","Yes";
BA_DEF_ SG_  "GenSigStartValueInteger" INT 0 1000000000;
BA_DEF_ SG_  "UsedOnPgmDBC" ENUM  "No","Yes";
BA_DEF_ SG_  "CrossOver_InfoCAN" ENUM  "No","Yes";
BA_DEF_ SG_  "WakeupSignal" ENUM  "No","Yes";
BA_DEF_ SG_  "GenSigInactiveValue" INT 0 100000;
BA_DEF_ SG_  "GenSigSendType" ENUM  "Cyclic","OnWrite","vector_leerstring","OnChange","vector_leerstring","IfActive","vector_leerstring","NoSigSendType";
BA_DEF_ BO_  "SCP_FreshnessValueLength" INT 0 512;
BA_DEF_ BO_  "AuthFreshnessCounterSyncAttempt" INT 0 512;
BA_DEF_ BO_  "SCP_FreshnessValueTxLength" INT 0 512;
BA_DEF_ BO_  "SCP_AuthInfoTxLength" INT 0 512;
BA_DEF_ BO_  "ProgBWConditional" STRING ;
BA_DEF_ BO_  "NmAsrMessage" ENUM  "No","Yes";
BA_DEF_ BO_  "TpApplType" STRING ;
BA_DEF_ BO_  "DiagState" ENUM  "No","Yes";
BA_DEF_ BO_  "TpTxIndex" INT 0 536870911;
BA_DEF_ BO_  "DiagRequest" ENUM  "No","Yes";
BA_DEF_ BO_  "DiagResponse" ENUM  "No","Yes";
BA_DEF_ BO_  "GenMsgILSupport" ENUM  "No","Yes";
BA_DEF_DEF_  "U_CD542_MY2021_Rx" "No";
BA_DEF_DEF_  "U_CD542_MY2021_Tx" "No";
BA_DEF_DEF_  "U_U55X_MY2022_Tx" "No";
BA_DEF_DEF_  "OvtpPushApplication" "FALSE";
BA_DEF_DEF_  "ECGUsedRxSignal" "No";
BA_DEF_DEF_  "ECGUsedTxSignal" "No";
BA_DEF_DEF_  "VFrameFormat" "ExtendedCAN_FD";
BA_DEF_DEF_  "FrameRouting" "NONE";
BA_DEF_DEF_  "FrameGatewayNetwork" "NONE";
BA_DEF_DEF_  "NetworkInitialization" "Yes";
BA_DEF_DEF_  "FrameGatewayId" 0;
BA_DEF_DEF_  "EventRateOfChange" 10000;
BA_DEF_DEF_  "GenMsgStartDelayTime" 0;
BA_DEF_DEF_  "GenMsgNrOfRepetition" 1;
BA_DEF_DEF_  "GenMsgDelayTime" 20;
BA_DEF_DEF_  "GenMsgCycleTime" 0;
BA_DEF_DEF_  "GenMsgSendType" "NoMsgSendType";
BA_DEF_DEF_  "U_T6_MCA_MY2020_Tx" "No";
BA_DEF_DEF_  "U_P702_MY2021_Tx" "No";
BA_DEF_DEF_  "U_CX727_MY2021_Tx" "No";
BA_DEF_DEF_  "U_T6_MCA_MY2020_Rx" "No";
BA_DEF_DEF_  "U_P702_MY2021_Rx" "No";
BA_DEF_DEF_  "U_CX727_MY2021_Rx" "No";
BA_DEF_DEF_  "GenSigStartValue" 0;
BA_DEF_DEF_  "MetaData" "No";
BA_DEF_DEF_  "ContentDependant" "No";
BA_DEF_DEF_  "GenSigStartValueInteger" 0;
BA_DEF_DEF_  "UsedOnPgmDBC" "Yes";
BA_DEF_DEF_  "CrossOver_InfoCAN" "No";
BA_DEF_DEF_  "WakeupSignal" "No";
BA_DEF_DEF_  "GenSigInactiveValue" 0;
BA_DEF_DEF_  "GenSigSendType" "NoSigSendType";
BA_DEF_DEF_  "SCP_FreshnessValueLength" 64;
BA_DEF_DEF_  "AuthFreshnessCounterSyncAttempt" 2;
BA_DEF_DEF_  "SCP_FreshnessValueTxLength" 11;
BA_DEF_DEF_  "SCP_AuthInfoTxLength" 53;
BA_DEF_DEF_  "ProgBWConditional" "NONE";
BA_DEF_DEF_  "NmAsrMessage" "No";
BA_DEF_DEF_  "TpApplType" "";
BA_DEF_DEF_  "DiagState" "No";
BA_DEF_DEF_  "TpTxIndex" 0;
BA_DEF_DEF_  "DiagRequest" "No";
BA_DEF_DEF_  "DiagResponse" "No";
BA_DEF_DEF_  "GenMsgILSupport" "Yes";
BA_ "GenMsgCycleTime" BO_ 1098 500;
BA_ "GenMsgSendType" BO_ 1098 5;
BA_ "FrameRouting" BO_ 1098 "";
BA_ "VFrameFormat" BO_ 1098 14;
BA_ "GenMsgCycleTime" BO_ 1086 100;
BA_ "GenMsgSendType" BO_ 1086 0;
BA_ "FrameRouting" BO_ 1086 "";
BA_ "VFrameFormat" BO_ 1086 14;
BA_ "GenMsgCycleTime" BO_ 1071 100;
BA_ "GenMsgSendType" BO_ 1071 0;
BA_ "FrameRouting" BO_ 1071 "";
BA_ "VFrameFormat" BO_ 1071 14;
BA_ "GenMsgCycleTime" BO_ 1069 100;
BA_ "GenMsgSendType" BO_ 1069 0;
BA_ "FrameRouting" BO_ 1069 "";
BA_ "VFrameFormat" BO_ 1069 14;
BA_ "GenMsgCycleTime" BO_ 1060 100;
BA_ "GenMsgSendType" BO_ 1060 0;
BA_ "FrameRouting" BO_ 1060 "";
BA_ "VFrameFormat" BO_ 1060 14;
BA_ "GenMsgCycleTime" BO_ 1057 100;
BA_ "GenMsgSendType" BO_ 1057 0;
BA_ "FrameRouting" BO_ 1057 "";
BA_ "VFrameFormat" BO_ 1057 14;
BA_ "GenMsgCycleTime" BO_ 1055 100;
BA_ "GenMsgSendType" BO_ 1055 0;
BA_ "FrameRouting" BO_ 1055 "";
BA_ "VFrameFormat" BO_ 1055 14;
BA_ "GenMsgCycleTime" BO_ 562 100;
BA_ "GenMsgSendType" BO_ 562 0;
BA_ "FrameRouting" BO_ 562 "";
BA_ "VFrameFormat" BO_ 562 14;
BA_ "GenMsgCycleTime" BO_ 523 1000;
BA_ "GenMsgSendType" BO_ 523 0;
BA_ "FrameRouting" BO_ 523 "";
BA_ "VFrameFormat" BO_ 523 14;
BA_ "GenMsgDelayTime" BO_ 517 10;
BA_ "GenMsgCycleTime" BO_ 517 20;
BA_ "GenMsgSendType" BO_ 517 0;
BA_ "FrameRouting" BO_ 517 "";
BA_ "VFrameFormat" BO_ 517 14;
BA_ "GenMsgDelayTime" BO_ 516 0;
BA_ "GenMsgCycleTime" BO_ 516 10;
BA_ "GenMsgSendType" BO_ 516 0;
BA_ "FrameRouting" BO_ 516 "";
BA_ "VFrameFormat" BO_ 516 14;
BA_ "GenMsgDelayTime" BO_ 514 10;
BA_ "GenMsgCycleTime" BO_ 514 20;
BA_ "GenMsgSendType" BO_ 514 0;
BA_ "FrameRouting" BO_ 514 "";
BA_ "VFrameFormat" BO_ 514 14;
BA_ "GenMsgDelayTime" BO_ 512 10;
BA_ "GenMsgCycleTime" BO_ 512 20;
BA_ "GenMsgSendType" BO_ 512 0;
BA_ "FrameRouting" BO_ 512 "";
BA_ "VFrameFormat" BO_ 512 14;
BA_ "GenMsgCycleTime" BO_ 381 100;
BA_ "GenMsgSendType" BO_ 381 0;
BA_ "FrameRouting" BO_ 381 "";
BA_ "VFrameFormat" BO_ 381 14;
BA_ "GenMsgCycleTime" BO_ 380 100;
BA_ "GenMsgSendType" BO_ 380 0;
BA_ "FrameRouting" BO_ 380 "";
BA_ "VFrameFormat" BO_ 380 14;
BA_ "GenMsgCycleTime" BO_ 377 100;
BA_ "GenMsgSendType" BO_ 377 0;
BA_ "FrameRouting" BO_ 377 "";
BA_ "VFrameFormat" BO_ 377 14;
BA_ "GenMsgCycleTime" BO_ 376 100;
BA_ "GenMsgSendType" BO_ 376 0;
BA_ "FrameRouting" BO_ 376 "";
BA_ "VFrameFormat" BO_ 376 14;
BA_ "GenMsgDelayTime" BO_ 373 10;
BA_ "GenMsgCycleTime" BO_ 373 20;
BA_ "GenMsgSendType" BO_ 373 0;
BA_ "FrameRouting" BO_ 373 "";
BA_ "VFrameFormat" BO_ 373 14;
BA_ "GenMsgDelayTime" BO_ 359 0;
BA_ "GenMsgCycleTime" BO_ 359 10;
BA_ "GenMsgSendType" BO_ 359 0;
BA_ "FrameRouting" BO_ 359 "";
BA_ "VFrameFormat" BO_ 359 14;
BA_ "GenMsgCycleTime" BO_ 358 100;
BA_ "GenMsgSendType" BO_ 358 0;
BA_ "FrameRouting" BO_ 358 "";
BA_ "VFrameFormat" BO_ 358 14;
BA_ "GenMsgDelayTime" BO_ 357 10;
BA_ "GenMsgCycleTime" BO_ 357 20;
BA_ "GenMsgSendType" BO_ 357 0;
BA_ "FrameRouting" BO_ 357 "";
BA_ "VFrameFormat" BO_ 357 14;
BA_ "GenMsgCycleTime" BO_ 355 100;
BA_ "GenMsgSendType" BO_ 355 0;
BA_ "FrameRouting" BO_ 355 "";
BA_ "VFrameFormat" BO_ 355 14;
BA_ "GenMsgCycleTime" BO_ 342 100;
BA_ "GenMsgSendType" BO_ 342 0;
BA_ "FrameRouting" BO_ 342 "";
BA_ "VFrameFormat" BO_ 342 14;
BA_ "GenMsgDelayTime" BO_ 71 10;
BA_ "GenMsgCycleTime" BO_ 71 20;
BA_ "GenMsgSendType" BO_ 71 0;
BA_ "FrameRouting" BO_ 71 "";
BA_ "VFrameFormat" BO_ 71 14;
BA_ "NetworkInitialization" BO_ 1822 0;
BA_ "GenMsgDelayTime" BO_ 1822 0;
BA_ "GenMsgSendType" BO_ 1822 1;
BA_ "DiagResponse" BO_ 1822 1;
BA_ "GenMsgILSupport" BO_ 1822 0;
BA_ "FrameRouting" BO_ 1822 "";
BA_ "VFrameFormat" BO_ 1822 14;
BA_ "NetworkInitialization" BO_ 1438 0;
BA_ "GenMsgCycleTime" BO_ 1438 1000;
BA_ "GenMsgSendType" BO_ 1438 0;
BA_ "NmAsrMessage" BO_ 1438 1;
BA_ "GenMsgILSupport" BO_ 1438 0;
BA_ "FrameRouting" BO_ 1438 "";
BA_ "VFrameFormat" BO_ 1438 14;
BA_ "FrameGatewayNetwork" BO_ 954 "HS1_CAN";
BA_ "FrameGatewayId" BO_ 954 954;
BA_ "FrameRouting" BO_ 954 "";
BA_ "VFrameFormat" BO_ 954 14;
BA_ "GenMsgCycleTime" BO_ 1006 1000;
BA_ "GenMsgSendType" BO_ 1006 5;
BA_ "FrameRouting" BO_ 1006 "";
BA_ "VFrameFormat" BO_ 1006 14;
BA_ "FrameGatewayId" BO_ 820 820;
BA_ "FrameGatewayNetwork" BO_ 820 "HS2_CAN";
BA_ "FrameRouting" BO_ 820 "";
BA_ "VFrameFormat" BO_ 820 14;
BA_ "FrameGatewayNetwork" BO_ 137 "HS2_CAN";
BA_ "FrameGatewayId" BO_ 137 137;
BA_ "FrameRouting" BO_ 137 "";
BA_ "VFrameFormat" BO_ 137 14;
BA_ "FrameGatewayNetwork" BO_ 129 "HS2_CAN";
BA_ "FrameGatewayId" BO_ 129 129;
BA_ "FrameRouting" BO_ 129 "";
BA_ "VFrameFormat" BO_ 129 14;
BA_ "GenMsgCycleTime" BO_ 935 200;
BA_ "GenMsgSendType" BO_ 935 5;
BA_ "FrameRouting" BO_ 935 "";
BA_ "VFrameFormat" BO_ 935 14;
BA_ "FrameGatewayNetwork" BO_ 1108 "HS2_CAN";
BA_ "FrameGatewayId" BO_ 1108 1108;
BA_ "FrameRouting" BO_ 1108 "";
BA_ "VFrameFormat" BO_ 1108 14;
BA_ "FrameGatewayNetwork" BO_ 261 "HS3_CAN";
BA_ "FrameGatewayId" BO_ 261 261;
BA_ "FrameRouting" BO_ 261 "";
BA_ "VFrameFormat" BO_ 261 14;
BA_ "FrameGatewayNetwork" BO_ 1146 "HS3_CAN";
BA_ "FrameGatewayId" BO_ 1146 1146;
BA_ "FrameRouting" BO_ 1146 "";
BA_ "VFrameFormat" BO_ 1146 14;
BA_ "FrameGatewayNetwork" BO_ 533 "HS3_CAN";
BA_ "FrameGatewayId" BO_ 533 533;
BA_ "FrameRouting" BO_ 533 "";
BA_ "VFrameFormat" BO_ 533 14;
BA_ "FrameGatewayNetwork" BO_ 1041 "HS1_CAN";
BA_ "FrameGatewayId" BO_ 1041 1041;
BA_ "FrameRouting" BO_ 1041 "";
BA_ "VFrameFormat" BO_ 1041 14;
BA_ "FrameGatewayNetwork" BO_ 1067 "HS1_CAN";
BA_ "FrameGatewayId" BO_ 1067 1067;
BA_ "FrameRouting" BO_ 1067 "";
BA_ "VFrameFormat" BO_ 1067 14;
BA_ "FrameGatewayNetwork" BO_ 1112 "HS1_CAN";
BA_ "FrameGatewayId" BO_ 1112 1112;
BA_ "FrameRouting" BO_ 1112 "";
BA_ "VFrameFormat" BO_ 1112 14;
BA_ "FrameGatewayNetwork" BO_ 139 "HS2_CAN";
BA_ "FrameGatewayId" BO_ 139 139;
BA_ "FrameRouting" BO_ 139 "";
BA_ "VFrameFormat" BO_ 139 14;
BA_ "FrameGatewayNetwork" BO_ 1121 "HS2_CAN";
BA_ "FrameGatewayId" BO_ 1121 1121;
BA_ "FrameRouting" BO_ 1121 "";
BA_ "VFrameFormat" BO_ 1121 14;
BA_ "FrameGatewayNetwork" BO_ 1120 "HS2_CAN";
BA_ "FrameGatewayId" BO_ 1120 1120;
BA_ "FrameRouting" BO_ 1120 "";
BA_ "VFrameFormat" BO_ 1120 14;
BA_ "FrameGatewayNetwork" BO_ 1050 "MS1_CAN";
BA_ "FrameGatewayId" BO_ 1050 1050;
BA_ "FrameRouting" BO_ 1050 "";
BA_ "VFrameFormat" BO_ 1050 14;
BA_ "GenMsgCycleTime" BO_ 1137 1000;
BA_ "GenMsgSendType" BO_ 1137 0;
BA_ "FrameRouting" BO_ 1137 "";
BA_ "VFrameFormat" BO_ 1137 14;
BA_ "GenMsgCycleTime" BO_ 1255 1000;
BA_ "GenMsgSendType" BO_ 1255 0;
BA_ "FrameRouting" BO_ 1255 "";
BA_ "VFrameFormat" BO_ 1255 14;
BA_ "GenMsgCycleTime" BO_ 1254 1000;
BA_ "GenMsgSendType" BO_ 1254 0;
BA_ "FrameRouting" BO_ 1254 "";
BA_ "VFrameFormat" BO_ 1254 14;
BA_ "GenMsgCycleTime" BO_ 1253 1000;
BA_ "GenMsgSendType" BO_ 1253 0;
BA_ "FrameRouting" BO_ 1253 "";
BA_ "VFrameFormat" BO_ 1253 14;
BA_ "GenMsgCycleTime" BO_ 1252 1000;
BA_ "GenMsgSendType" BO_ 1252 0;
BA_ "FrameRouting" BO_ 1252 "";
BA_ "VFrameFormat" BO_ 1252 14;
BA_ "GenMsgCycleTime" BO_ 1251 1000;
BA_ "GenMsgSendType" BO_ 1251 0;
BA_ "FrameRouting" BO_ 1251 "";
BA_ "VFrameFormat" BO_ 1251 14;
BA_ "GenMsgCycleTime" BO_ 1250 1000;
BA_ "GenMsgSendType" BO_ 1250 0;
BA_ "FrameRouting" BO_ 1250 "";
BA_ "VFrameFormat" BO_ 1250 14;
BA_ "GenMsgCycleTime" BO_ 1249 1000;
BA_ "GenMsgSendType" BO_ 1249 0;
BA_ "FrameRouting" BO_ 1249 "";
BA_ "VFrameFormat" BO_ 1249 14;
BA_ "GenMsgCycleTime" BO_ 1248 1000;
BA_ "GenMsgSendType" BO_ 1248 0;
BA_ "FrameRouting" BO_ 1248 "";
BA_ "VFrameFormat" BO_ 1248 14;
BA_ "GenMsgCycleTime" BO_ 1113 50;
BA_ "GenMsgSendType" BO_ 1113 0;
BA_ "FrameRouting" BO_ 1113 "";
BA_ "VFrameFormat" BO_ 1113 14;
BA_ "GenMsgCycleTime" BO_ 1105 1000;
BA_ "GenMsgSendType" BO_ 1105 5;
BA_ "FrameRouting" BO_ 1105 "";
BA_ "VFrameFormat" BO_ 1105 14;
BA_ "GenMsgCycleTime" BO_ 938 200;
BA_ "GenMsgSendType" BO_ 938 5;
BA_ "FrameRouting" BO_ 938 "";
BA_ "VFrameFormat" BO_ 938 14;
BA_ "GenMsgCycleTime" BO_ 939 200;
BA_ "GenMsgSendType" BO_ 939 5;
BA_ "FrameRouting" BO_ 939 "";
BA_ "VFrameFormat" BO_ 939 14;
BA_ "GenMsgDelayTime" BO_ 937 10;
BA_ "GenMsgCycleTime" BO_ 937 20;
BA_ "GenMsgSendType" BO_ 937 0;
BA_ "FrameRouting" BO_ 937 "";
BA_ "VFrameFormat" BO_ 937 14;
BA_ "GenMsgDelayTime" BO_ 936 10;
BA_ "GenMsgCycleTime" BO_ 936 20;
BA_ "GenMsgSendType" BO_ 936 0;
BA_ "FrameRouting" BO_ 936 "";
BA_ "VFrameFormat" BO_ 936 14;
BA_ "GenMsgCycleTime" BO_ 877 1000;
BA_ "GenMsgSendType" BO_ 877 5;
BA_ "FrameRouting" BO_ 877 "";
BA_ "VFrameFormat" BO_ 877 14;
BA_ "FrameGatewayNetwork" BO_ 589 "HS1_CAN";
BA_ "FrameGatewayId" BO_ 589 589;
BA_ "FrameRouting" BO_ 589 "";
BA_ "VFrameFormat" BO_ 589 14;
BA_ "FrameGatewayNetwork" BO_ 588 "HS1_CAN";
BA_ "FrameGatewayId" BO_ 588 588;
BA_ "FrameRouting" BO_ 588 "";
BA_ "VFrameFormat" BO_ 588 14;
BA_ "FrameGatewayNetwork" BO_ 587 "HS1_CAN";
BA_ "FrameGatewayId" BO_ 587 587;
BA_ "FrameRouting" BO_ 587 "";
BA_ "VFrameFormat" BO_ 587 14;
BA_ "GenMsgCycleTime" BO_ 389 100;
BA_ "GenMsgSendType" BO_ 389 0;
BA_ "FrameRouting" BO_ 389 "";
BA_ "VFrameFormat" BO_ 389 14;
BA_ "FrameGatewayNetwork" BO_ 1009 "HS3_CAN";
BA_ "FrameGatewayId" BO_ 1009 1009;
BA_ "FrameRouting" BO_ 1009 "";
BA_ "VFrameFormat" BO_ 1009 14;
BA_ "FrameGatewayNetwork" BO_ 360 "HS2_CAN";
BA_ "FrameGatewayId" BO_ 360 360;
BA_ "FrameRouting" BO_ 360 "";
BA_ "VFrameFormat" BO_ 360 14;
BA_ "FrameGatewayNetwork" BO_ 122 "HS1_CAN";
BA_ "FrameGatewayId" BO_ 122 122;
BA_ "FrameRouting" BO_ 122 "";
BA_ "VFrameFormat" BO_ 122 14;
BA_ "GenSigSendType" SG_ 1098 AirDamPos_D_Stat 3;
BA_ "U_T6_MCA_MY2020_Tx" SG_ 1098 EdmVeh_V_Dsply 1;
BA_ "U_P702_MY2021_Tx" SG_ 1098 EdmVeh_V_Dsply 1;
BA_ "U_T6_MCA_MY2020_Tx" SG_ 1098 EdmSailMdeOn_B_Stat 1;
BA_ "U_P702_MY2021_Tx" SG_ 1098 EdmSailMdeOn_B_Stat 1;
BA_ "GenSigSendType" SG_ 1098 EdmSailMdeOn_B_Stat 3;
BA_ "U_T6_MCA_MY2020_Tx" SG_ 1098 EdmPrev_Fe_Dsply 1;
BA_ "U_P702_MY2021_Tx" SG_ 1098 EdmPrev_Fe_Dsply 1;
BA_ "U_T6_MCA_MY2020_Tx" SG_ 1098 EdmMsgTxt_D_Rq 1;
BA_ "U_P702_MY2021_Tx" SG_ 1098 EdmMsgTxt_D_Rq 1;
BA_ "GenSigSendType" SG_ 1098 EdmMsgTxt_D_Rq 3;
BA_ "U_T6_MCA_MY2020_Tx" SG_ 1098 EdmLamp_D_Dsply 1;
BA_ "U_P702_MY2021_Tx" SG_ 1098 EdmLamp_D_Dsply 1;
BA_ "GenSigSendType" SG_ 1098 EdmLamp_D_Dsply 3;
BA_ "U_T6_MCA_MY2020_Tx" SG_ 1098 EdmCurrent_Fe_Dsply 1;
BA_ "U_P702_MY2021_Tx" SG_ 1098 EdmCurrent_Fe_Dsply 1;
BA_ "U_T6_MCA_MY2020_Tx" SG_ 1098 EdmCmplnc_B_Dsply 1;
BA_ "U_P702_MY2021_Tx" SG_ 1098 EdmCmplnc_B_Dsply 1;
BA_ "GenSigSendType" SG_ 1098 EdmCmplnc_B_Dsply 3;
BA_ "U_T6_MCA_MY2020_Tx" SG_ 1098 EdmCmplnc_Pc_Dsply 1;
BA_ "U_P702_MY2021_Tx" SG_ 1098 EdmCmplnc_Pc_Dsply 1;
BA_ "U_T6_MCA_MY2020_Tx" SG_ 1086 EngOil_P_Actl 1;
BA_ "GenSigStartValueInteger" SG_ 1086 EngIpcDsplyCht_Te_Actl 75;
BA_ "GenSigStartValue" SG_ 1086 EngIpcDsplyCht_Te_Actl 75;
BA_ "U_T6_MCA_MY2020_Tx" SG_ 1086 EngIpcDsplyAfr_Rt_Actl 1;
BA_ "U_T6_MCA_MY2020_Tx" SG_ 1086 EngMnfld_P_Actl 1;
BA_ "U_P702_MY2021_Tx" SG_ 1086 EngMnfld_P_Actl 1;
BA_ "GenSigStartValueInteger" SG_ 1086 EngMnfld_P_Actl 2068;
BA_ "U_T6_MCA_MY2020_Tx" SG_ 1086 FuelPumpPwr_B_Rq 1;
BA_ "U_P702_MY2021_Tx" SG_ 1086 FuelPumpPwr_B_Rq 1;
BA_ "U_T6_MCA_MY2020_Tx" SG_ 1086 BattULoChrg_U_Cmd 1;
BA_ "U_P702_MY2021_Tx" SG_ 1086 BattULoChrg_U_Cmd 1;
BA_ "U_T6_MCA_MY2020_Tx" SG_ 1086 ElLoadCtl_D_Rq 1;
BA_ "U_P702_MY2021_Tx" SG_ 1086 ElLoadCtl_D_Rq 1;
BA_ "ContentDependant" SG_ 1086 ElLoadCtl_D_Rq 1;
BA_ "U_T6_MCA_MY2020_Tx" SG_ 1071 EngAout_N_Dsply 1;
BA_ "U_P702_MY2021_Tx" SG_ 1071 EngAout_N_Dsply 1;
BA_ "U_T6_MCA_MY2020_Tx" SG_ 1071 CluPdl_PcRate_Actl 1;
BA_ "U_P702_MY2021_Tx" SG_ 1071 CluPdl_PcRate_Actl 1;
BA_ "ContentDependant" SG_ 1071 CluPdl_PcRate_Actl 1;
BA_ "CrossOver_InfoCAN" SG_ 1071 CluPdl_PcRate_Actl 1;
BA_ "U_T6_MCA_MY2020_Tx" SG_ 1071 CluPdlPosPcMeas_D_Qf 1;
BA_ "U_P702_MY2021_Tx" SG_ 1071 CluPdlPosPcMeas_D_Qf 1;
BA_ "U_P702_MY2021_Rx" SG_ 1071 CluPdlPosPcMeas_D_Qf 1;
BA_ "GenSigStartValue" SG_ 1071 CluPdlPosPcMeas_D_Qf 1;
BA_ "MetaData" SG_ 1071 CluPdlPosPcMeas_D_Qf 1;
BA_ "ContentDependant" SG_ 1071 CluPdlPosPcMeas_D_Qf 1;
BA_ "GenSigStartValueInteger" SG_ 1071 CluPdlPosPcMeas_D_Qf 1;
BA_ "CrossOver_InfoCAN" SG_ 1071 CluPdlPosPcMeas_D_Qf 1;
BA_ "U_T6_MCA_MY2020_Tx" SG_ 1071 CluPdlPos_Pc_Meas 1;
BA_ "U_P702_MY2021_Tx" SG_ 1071 CluPdlPos_Pc_Meas 1;
BA_ "U_P702_MY2021_Rx" SG_ 1071 CluPdlPos_Pc_Meas 1;
BA_ "ContentDependant" SG_ 1071 CluPdlPos_Pc_Meas 1;
BA_ "CrossOver_InfoCAN" SG_ 1071 CluPdlPos_Pc_Meas 1;
BA_ "U_T6_MCA_MY2020_Tx" SG_ 1071 EngAoutIdl_N_Ntrl 1;
BA_ "U_P702_MY2021_Tx" SG_ 1071 EngAoutIdl_N_Ntrl 1;
BA_ "U_P702_MY2021_Rx" SG_ 1071 EngAoutIdl_N_Ntrl 1;
BA_ "U_CX727_MY2021_Rx" SG_ 1071 EngAoutIdl_N_Ntrl 1;
BA_ "ContentDependant" SG_ 1071 EngAoutIdl_N_Ntrl 1;
BA_ "CrossOver_InfoCAN" SG_ 1071 EngAoutIdl_N_Ntrl 1;
BA_ "U_CD542_MY2021_Tx" SG_ 1069 ReFuelSysStat_D_Dsply 1;
BA_ "U_CX727_MY2021_Tx" SG_ 1069 ReFuelSysStat_D_Dsply 1;
BA_ "WakeupSignal" SG_ 1069 ReFuelSysStat_D_Dsply 1;
BA_ "U_P702_MY2021_Tx" SG_ 1069 SlMde_D_Stat 1;
BA_ "U_T6_MCA_MY2020_Tx" SG_ 1069 SlMde_D_Stat 1;
BA_ "U_P702_MY2021_Tx" SG_ 1069 SlMde_D_RqDsply 1;
BA_ "U_T6_MCA_MY2020_Tx" SG_ 1069 SlMde_D_RqDsply 1;
BA_ "U_P702_MY2021_Tx" SG_ 1069 IsaOffst_D_Stat 1;
BA_ "U_T6_MCA_MY2020_Tx" SG_ 1069 IsaOffst_D_Stat 1;
BA_ "U_T6_MCA_MY2020_Tx" SG_ 1069 GrllShtrPos_D_Cmd 1;
BA_ "U_P702_MY2021_Tx" SG_ 1069 GrllShtrPos_D_Cmd 1;
BA_ "CrossOver_InfoCAN" SG_ 1069 GrllShtrPos_D_Cmd 1;
BA_ "U_T6_MCA_MY2020_Tx" SG_ 1069 GrllShtrPos_B_Falt 1;
BA_ "U_P702_MY2021_Tx" SG_ 1069 GrllShtrPos_B_Falt 1;
BA_ "CrossOver_InfoCAN" SG_ 1069 GrllShtrPos_B_Falt 1;
BA_ "U_P702_MY2021_Tx" SG_ 1069 ObdWarmUp_B_Complt 1;
BA_ "ContentDependant" SG_ 1069 ObdWarmUp_B_Complt 1;
BA_ "CrossOver_InfoCAN" SG_ 1069 ObdWarmUp_B_Complt 1;
BA_ "U_T6_MCA_MY2020_Tx" SG_ 1069 EngMsgTxt_D_Rq 1;
BA_ "U_P702_MY2021_Tx" SG_ 1069 EngMsgTxt_D_Rq 1;
BA_ "ContentDependant" SG_ 1069 EngMsgTxt_D_Rq 1;
BA_ "CrossOver_InfoCAN" SG_ 1069 EngMsgTxt_D_Rq 1;
BA_ "U_T6_MCA_MY2020_Tx" SG_ 1069 EngClnt_Te_ActlDiag 1;
BA_ "U_P702_MY2021_Tx" SG_ 1069 EngClnt_Te_ActlDiag 1;
BA_ "U_T6_MCA_MY2020_Rx" SG_ 1069 EngClnt_Te_ActlDiag 1;
BA_ "U_P702_MY2021_Rx" SG_ 1069 EngClnt_Te_ActlDiag 1;
BA_ "ContentDependant" SG_ 1069 EngClnt_Te_ActlDiag 1;
BA_ "CrossOver_InfoCAN" SG_ 1069 EngClnt_Te_ActlDiag 1;
BA_ "U_T6_MCA_MY2020_Tx" SG_ 1069 EngLoad_Pc_CalcDiag 1;
BA_ "U_P702_MY2021_Tx" SG_ 1069 EngLoad_Pc_CalcDiag 1;
BA_ "U_T6_MCA_MY2020_Rx" SG_ 1069 EngLoad_Pc_CalcDiag 1;
BA_ "U_P702_MY2021_Rx" SG_ 1069 EngLoad_Pc_CalcDiag 1;
BA_ "ContentDependant" SG_ 1069 EngLoad_Pc_CalcDiag 1;
BA_ "CrossOver_InfoCAN" SG_ 1069 EngLoad_Pc_CalcDiag 1;
BA_ "U_T6_MCA_MY2020_Tx" SG_ 1069 EngAirIn_Te_Actl 1;
BA_ "U_P702_MY2021_Tx" SG_ 1069 EngAirIn_Te_Actl 1;
BA_ "U_T6_MCA_MY2020_Rx" SG_ 1069 EngAirIn_Te_Actl 1;
BA_ "U_P702_MY2021_Rx" SG_ 1069 EngAirIn_Te_Actl 1;
BA_ "CrossOver_InfoCAN" SG_ 1069 EngAirIn_Te_Actl 1;
BA_ "U_T6_MCA_MY2020_Tx" SG_ 1069 ApedPos_Pc_ActlDiag 1;
BA_ "U_P702_MY2021_Tx" SG_ 1069 ApedPos_Pc_ActlDiag 1;
BA_ "U_T6_MCA_MY2020_Rx" SG_ 1069 ApedPos_Pc_ActlDiag 1;
BA_ "U_P702_MY2021_Rx" SG_ 1069 ApedPos_Pc_ActlDiag 1;
BA_ "ContentDependant" SG_ 1069 ApedPos_Pc_ActlDiag 1;
BA_ "CrossOver_InfoCAN" SG_ 1069 ApedPos_Pc_ActlDiag 1;
BA_ "U_T6_MCA_MY2020_Tx" SG_ 1060 RearDiffOilTeWarn_B_Rq 1;
BA_ "U_P702_MY2021_Tx" SG_ 1060 RearDiffOilTeWarn_B_Rq 1;
BA_ "U_T6_MCA_MY2020_Tx" SG_ 1060 RearDiffOil_Te_Actl 1;
BA_ "U_P702_MY2021_Tx" SG_ 1060 RearDiffOil_Te_Actl 1;
BA_ "GenSigStartValue" SG_ 1060 RearDiffOil_Te_Actl 77;
BA_ "GenSigStartValueInteger" SG_ 1060 RearDiffOil_Te_Actl 77;
BA_ "U_T6_MCA_MY2020_Tx" SG_ 1060 BpedDrvMsgTxt_B_Dsply 1;
BA_ "U_P702_MY2021_Tx" SG_ 1060 BpedDrvMsgTxt_B_Dsply 1;
BA_ "U_T6_MCA_MY2020_Tx" SG_ 1060 FuelLvl_Pc_DsplyEng 1;
BA_ "U_P702_MY2021_Tx" SG_ 1060 FuelLvl_Pc_DsplyEng 1;
BA_ "GenSigStartValueInteger" SG_ 1060 FuelLvl_Pc_DsplyEng 48;
BA_ "U_T6_MCA_MY2020_Tx" SG_ 1060 FuelLvlWarn_D_ActlEng 1;
BA_ "U_P702_MY2021_Tx" SG_ 1060 FuelLvlWarn_D_ActlEng 1;
BA_ "U_T6_MCA_MY2020_Tx" SG_ 1060 FuelRange_L_DsplyEng 1;
BA_ "U_P702_MY2021_Tx" SG_ 1060 FuelRange_L_DsplyEng 1;
BA_ "U_T6_MCA_MY2020_Tx" SG_ 1060 SelDrvMdePt_D_Stat 1;
BA_ "U_P702_MY2021_Tx" SG_ 1060 SelDrvMdePt_D_Stat 1;
BA_ "U_P702_MY2021_Rx" SG_ 1060 SelDrvMdePt_D_Stat 1;
BA_ "U_T6_MCA_MY2020_Tx" SG_ 1057 FohEng_D_Rq 1;
BA_ "U_P702_MY2021_Tx" SG_ 1057 FohEng_D_Rq 1;
BA_ "GenSigStartValue" SG_ 1057 FohEng_D_Rq 2;
BA_ "ContentDependant" SG_ 1057 FohEng_D_Rq 1;
BA_ "GenSigStartValueInteger" SG_ 1057 FohEng_D_Rq 2;
BA_ "CrossOver_InfoCAN" SG_ 1057 FohEng_D_Rq 1;
BA_ "U_T6_MCA_MY2020_Tx" SG_ 1057 EngIdlShutDwnTxt_D_Rq 1;
BA_ "U_P702_MY2021_Tx" SG_ 1057 EngIdlShutDwnTxt_D_Rq 1;
BA_ "ECGUsedRxSignal" SG_ 1057 EngIdlShutDown_D_Stat 1;
BA_ "U_T6_MCA_MY2020_Tx" SG_ 1057 EngIdlShutDown_D_Stat 1;
BA_ "U_P702_MY2021_Tx" SG_ 1057 EngIdlShutDown_D_Stat 1;
BA_ "ContentDependant" SG_ 1057 EngIdlShutDown_D_Stat 1;
BA_ "CrossOver_InfoCAN" SG_ 1057 EngIdlShutDown_D_Stat 1;
BA_ "U_T6_MCA_MY2020_Tx" SG_ 1057 FUEL_ALCOHOL_PERCNT 1;
BA_ "U_P702_MY2021_Tx" SG_ 1057 FUEL_ALCOHOL_PERCNT 1;
BA_ "GenSigStartValue" SG_ 1057 FUEL_ALCOHOL_PERCNT 255;
BA_ "ContentDependant" SG_ 1057 FUEL_ALCOHOL_PERCNT 1;
BA_ "GenSigStartValueInteger" SG_ 1057 FUEL_ALCOHOL_PERCNT 255;
BA_ "CrossOver_InfoCAN" SG_ 1057 FUEL_ALCOHOL_PERCNT 1;
BA_ "U_T6_MCA_MY2020_Tx" SG_ 1057 TrnTotTq_Rt_Est 1;
BA_ "U_P702_MY2021_Tx" SG_ 1057 TrnTotTq_Rt_Est 1;
BA_ "ContentDependant" SG_ 1057 TrnTotTq_Rt_Est 1;
BA_ "CrossOver_InfoCAN" SG_ 1057 TrnTotTq_Rt_Est 1;
BA_ "U_T6_MCA_MY2020_Tx" SG_ 1057 TrnTotLss_Tq_Est 1;
BA_ "U_P702_MY2021_Tx" SG_ 1057 TrnTotLss_Tq_Est 1;
BA_ "ContentDependant" SG_ 1057 TrnTotLss_Tq_Est 1;
BA_ "CrossOver_InfoCAN" SG_ 1057 TrnTotLss_Tq_Est 1;
BA_ "U_T6_MCA_MY2020_Tx" SG_ 1057 ECMMILRequest 1;
BA_ "U_P702_MY2021_Tx" SG_ 1057 ECMMILRequest 1;
BA_ "CrossOver_InfoCAN" SG_ 1057 ECMMILRequest 1;
BA_ "U_T6_MCA_MY2020_Tx" SG_ 1057 AirCondFluidHi_P_Actl 1;
BA_ "U_P702_MY2021_Tx" SG_ 1057 AirCondFluidHi_P_Actl 1;
BA_ "CrossOver_InfoCAN" SG_ 1057 AirCondFluidHi_P_Actl 1;
BA_ "U_T6_MCA_MY2020_Tx" SG_ 1057 OilPressureWarning 1;
BA_ "U_P702_MY2021_Tx" SG_ 1057 OilPressureWarning 1;
BA_ "CrossOver_InfoCAN" SG_ 1057 OilPressureWarning 1;
BA_ "U_T6_MCA_MY2020_Tx" SG_ 1057 VehVLimStat_D_Actl 1;
BA_ "U_P702_MY2021_Tx" SG_ 1057 VehVLimStat_D_Actl 1;
BA_ "U_T6_MCA_MY2020_Rx" SG_ 1057 VehVLimStat_D_Actl 1;
BA_ "U_P702_MY2021_Rx" SG_ 1057 VehVLimStat_D_Actl 1;
BA_ "ContentDependant" SG_ 1057 VehVLimStat_D_Actl 1;
BA_ "CrossOver_InfoCAN" SG_ 1057 VehVLimStat_D_Actl 1;
BA_ "U_T6_MCA_MY2020_Tx" SG_ 1057 VehVLimActv_B_Actl 1;
BA_ "U_P702_MY2021_Tx" SG_ 1057 VehVLimActv_B_Actl 1;
BA_ "U_T6_MCA_MY2020_Rx" SG_ 1057 VehVLimActv_B_Actl 1;
BA_ "U_P702_MY2021_Rx" SG_ 1057 VehVLimActv_B_Actl 1;
BA_ "ContentDependant" SG_ 1057 VehVLimActv_B_Actl 1;
BA_ "CrossOver_InfoCAN" SG_ 1057 VehVLimActv_B_Actl 1;
BA_ "U_T6_MCA_MY2020_Tx" SG_ 1057 CoolantFanStepAct 1;
BA_ "U_P702_MY2021_Tx" SG_ 1057 CoolantFanStepAct 1;
BA_ "CrossOver_InfoCAN" SG_ 1057 CoolantFanStepAct 1;
BA_ "ECGUsedRxSignal" SG_ 1055 EcoCochInstNeg_B_Dsply 1;
BA_ "U_T6_MCA_MY2020_Tx" SG_ 1055 EcoCochInstNeg_B_Dsply 1;
BA_ "U_P702_MY2021_Tx" SG_ 1055 EcoCochInstNeg_B_Dsply 1;
BA_ "CrossOver_InfoCAN" SG_ 1055 EcoCochInstNeg_B_Dsply 1;
BA_ "ECGUsedRxSignal" SG_ 1055 EcoCochShif_Pc_Dsply 1;
BA_ "U_T6_MCA_MY2020_Tx" SG_ 1055 EcoCochShif_Pc_Dsply 1;
BA_ "U_P702_MY2021_Tx" SG_ 1055 EcoCochShif_Pc_Dsply 1;
BA_ "GenSigStartValue" SG_ 1055 EcoCochShif_Pc_Dsply 255;
BA_ "GenSigStartValueInteger" SG_ 1055 EcoCochShif_Pc_Dsply 255;
BA_ "ECGUsedRxSignal" SG_ 1055 EcoCochInst_Pc_Dsply 1;
BA_ "U_T6_MCA_MY2020_Tx" SG_ 1055 EcoCochInst_Pc_Dsply 1;
BA_ "U_P702_MY2021_Tx" SG_ 1055 EcoCochInst_Pc_Dsply 1;
BA_ "GenSigStartValue" SG_ 1055 EcoCochInst_Pc_Dsply 100;
BA_ "GenSigStartValueInteger" SG_ 1055 EcoCochInst_Pc_Dsply 1000;
BA_ "ECGUsedRxSignal" SG_ 1055 EcoCochIdlFuel_Pc_Dsply 1;
BA_ "U_T6_MCA_MY2020_Tx" SG_ 1055 EcoCochIdlFuel_Pc_Dsply 1;
BA_ "U_P702_MY2021_Tx" SG_ 1055 EcoCochIdlFuel_Pc_Dsply 1;
BA_ "GenSigStartValue" SG_ 1055 EcoCochIdlFuel_Pc_Dsply 255;
BA_ "GenSigStartValueInteger" SG_ 1055 EcoCochIdlFuel_Pc_Dsply 255;
BA_ "ECGUsedRxSignal" SG_ 1055 EcoCochDecel_Pc_Dsply 1;
BA_ "U_T6_MCA_MY2020_Tx" SG_ 1055 EcoCochDecel_Pc_Dsply 1;
BA_ "U_P702_MY2021_Tx" SG_ 1055 EcoCochDecel_Pc_Dsply 1;
BA_ "GenSigStartValue" SG_ 1055 EcoCochDecel_Pc_Dsply 255;
BA_ "GenSigStartValueInteger" SG_ 1055 EcoCochDecel_Pc_Dsply 255;
BA_ "ECGUsedRxSignal" SG_ 1055 EcoCochCrus_Pc_Dsply 1;
BA_ "U_T6_MCA_MY2020_Tx" SG_ 1055 EcoCochCrus_Pc_Dsply 1;
BA_ "U_P702_MY2021_Tx" SG_ 1055 EcoCochCrus_Pc_Dsply 1;
BA_ "GenSigStartValue" SG_ 1055 EcoCochCrus_Pc_Dsply 255;
BA_ "GenSigStartValueInteger" SG_ 1055 EcoCochCrus_Pc_Dsply 255;
BA_ "ECGUsedRxSignal" SG_ 1055 EcoCochA_Pc_Dsply 1;
BA_ "U_T6_MCA_MY2020_Tx" SG_ 1055 EcoCochA_Pc_Dsply 1;
BA_ "U_P702_MY2021_Tx" SG_ 1055 EcoCochA_Pc_Dsply 1;
BA_ "GenSigStartValue" SG_ 1055 EcoCochA_Pc_Dsply 255;
BA_ "GenSigStartValueInteger" SG_ 1055 EcoCochA_Pc_Dsply 255;
BA_ "U_T6_MCA_MY2020_Tx" SG_ 562 GearNtrl_No_Cs 1;
BA_ "U_P702_MY2021_Tx" SG_ 562 GearNtrl_No_Cs 1;
BA_ "MetaData" SG_ 562 GearNtrl_No_Cs 1;
BA_ "ContentDependant" SG_ 562 GearNtrl_No_Cs 1;
BA_ "U_T6_MCA_MY2020_Tx" SG_ 562 GearNtrl_No_Cnt 1;
BA_ "U_P702_MY2021_Tx" SG_ 562 GearNtrl_No_Cnt 1;
BA_ "MetaData" SG_ 562 GearNtrl_No_Cnt 1;
BA_ "ContentDependant" SG_ 562 GearNtrl_No_Cnt 1;
BA_ "U_T6_MCA_MY2020_Tx" SG_ 562 GearNtrl_D_Stat 1;
BA_ "U_P702_MY2021_Tx" SG_ 562 GearNtrl_D_Stat 1;
BA_ "GenSigSendType" SG_ 562 GearNtrl_D_Stat 3;
BA_ "GenSigStartValue" SG_ 562 GearNtrl_D_Stat 2;
BA_ "GenSigStartValueInteger" SG_ 562 GearNtrl_D_Stat 2;
BA_ "U_T6_MCA_MY2020_Tx" SG_ 523 EngAirFiltMsgTxt_D_Rq 1;
BA_ "U_P702_MY2021_Tx" SG_ 523 EngAirFiltMsgTxt_D_Rq 1;
BA_ "U_T6_MCA_MY2020_Tx" SG_ 523 WaterInFuel_B_Falt 1;
BA_ "U_P702_MY2021_Tx" SG_ 523 WaterInFuel_B_Falt 1;
BA_ "CrossOver_InfoCAN" SG_ 523 WaterInFuel_B_Falt 1;
BA_ "U_T6_MCA_MY2020_Tx" SG_ 523 UreaMnAdd_L2_Actl 1;
BA_ "U_P702_MY2021_Tx" SG_ 523 UreaMnAdd_L2_Actl 1;
BA_ "ECGUsedRxSignal" SG_ 523 VehUreaRnge3_L_DsplyMx 1;
BA_ "U_T6_MCA_MY2020_Tx" SG_ 523 VehUreaRnge3_L_DsplyMx 1;
BA_ "U_P702_MY2021_Tx" SG_ 523 VehUreaRnge3_L_DsplyMx 1;
BA_ "U_T6_MCA_MY2020_Tx" SG_ 523 UreaMxAdd_L2_Actl 1;
BA_ "U_P702_MY2021_Tx" SG_ 523 UreaMxAdd_L2_Actl 1;
BA_ "GenSigStartValue" SG_ 523 UreaMxAdd_L2_Actl 510;
BA_ "GenSigStartValueInteger" SG_ 523 UreaMxAdd_L2_Actl 510;
BA_ "U_T6_MCA_MY2020_Tx" SG_ 517 FapLc_B_Err 1;
BA_ "U_P702_MY2021_Tx" SG_ 517 FapLc_B_Err 1;
BA_ "U_T6_MCA_MY2020_Tx" SG_ 517 BrkTot_Tq_RqFapLc 1;
BA_ "U_P702_MY2021_Tx" SG_ 517 BrkTot_Tq_RqFapLc 1;
BA_ "U_P702_MY2021_Rx" SG_ 517 BrkTot_Tq_RqFapLc 1;
BA_ "U_CX727_MY2021_Rx" SG_ 517 BrkTot_Tq_RqFapLc 1;
BA_ "U_T6_MCA_MY2020_Tx" SG_ 517 TrnAin_Pc_RqDrv 1;
BA_ "U_P702_MY2021_Tx" SG_ 517 TrnAin_Pc_RqDrv 1;
BA_ "U_T6_MCA_MY2020_Tx" SG_ 516 EngAoutNActl_D_QF 1;
BA_ "U_P702_MY2021_Tx" SG_ 516 EngAoutNActl_D_QF 1;
BA_ "U_T6_MCA_MY2020_Rx" SG_ 516 EngAoutNActl_D_QF 1;
BA_ "U_P702_MY2021_Rx" SG_ 516 EngAoutNActl_D_QF 1;
BA_ "GenSigStartValue" SG_ 516 EngAoutNActl_D_QF 1;
BA_ "MetaData" SG_ 516 EngAoutNActl_D_QF 1;
BA_ "GenSigStartValueInteger" SG_ 516 EngAoutNActl_D_QF 1;
BA_ "CrossOver_InfoCAN" SG_ 516 EngAoutNActl_D_QF 1;
BA_ "U_P702_MY2021_Tx" SG_ 516 EngAout3_N_Actl 1;
BA_ "ContentDependant" SG_ 516 EngAout3_N_Actl 1;
BA_ "CrossOver_InfoCAN" SG_ 516 EngAout3_N_Actl 1;
BA_ "U_T6_MCA_MY2020_Tx" SG_ 516 ApedPos_PcRate_ActlArb 1;
BA_ "U_P702_MY2021_Tx" SG_ 516 ApedPos_PcRate_ActlArb 1;
BA_ "U_T6_MCA_MY2020_Rx" SG_ 516 ApedPos_PcRate_ActlArb 1;
BA_ "U_P702_MY2021_Rx" SG_ 516 ApedPos_PcRate_ActlArb 1;
BA_ "CrossOver_InfoCAN" SG_ 516 ApedPos_PcRate_ActlArb 1;
BA_ "ECGUsedRxSignal" SG_ 516 ApedPos_Pc_ActlArb 1;
BA_ "U_T6_MCA_MY2020_Tx" SG_ 516 ApedPos_Pc_ActlArb 1;
BA_ "U_P702_MY2021_Tx" SG_ 516 ApedPos_Pc_ActlArb 1;
BA_ "U_CX727_MY2021_Rx" SG_ 516 ApedPos_Pc_ActlArb 1;
BA_ "U_T6_MCA_MY2020_Rx" SG_ 516 ApedPos_Pc_ActlArb 1;
BA_ "U_P702_MY2021_Rx" SG_ 516 ApedPos_Pc_ActlArb 1;
BA_ "CrossOver_InfoCAN" SG_ 516 ApedPos_Pc_ActlArb 1;
BA_ "U_T6_MCA_MY2020_Tx" SG_ 516 ApedPosPcActl_D_Qf 1;
BA_ "U_P702_MY2021_Tx" SG_ 516 ApedPosPcActl_D_Qf 1;
BA_ "U_CX727_MY2021_Rx" SG_ 516 ApedPosPcActl_D_Qf 1;
BA_ "U_T6_MCA_MY2020_Rx" SG_ 516 ApedPosPcActl_D_Qf 1;
BA_ "U_P702_MY2021_Rx" SG_ 516 ApedPosPcActl_D_Qf 1;
BA_ "GenSigStartValue" SG_ 516 ApedPosPcActl_D_Qf 1;
BA_ "MetaData" SG_ 516 ApedPosPcActl_D_Qf 1;
BA_ "GenSigStartValueInteger" SG_ 516 ApedPosPcActl_D_Qf 1;
BA_ "CrossOver_InfoCAN" SG_ 516 ApedPosPcActl_D_Qf 1;
BA_ "ECGUsedRxSignal" SG_ 516 EngAout_N_Actl 1;
BA_ "U_T6_MCA_MY2020_Tx" SG_ 516 EngAout_N_Actl 1;
BA_ "U_P702_MY2021_Tx" SG_ 516 EngAout_N_Actl 1;
BA_ "U_CX727_MY2021_Rx" SG_ 516 EngAout_N_Actl 1;
BA_ "U_T6_MCA_MY2020_Rx" SG_ 516 EngAout_N_Actl 1;
BA_ "U_P702_MY2021_Rx" SG_ 516 EngAout_N_Actl 1;
BA_ "CrossOver_InfoCAN" SG_ 516 EngAout_N_Actl 1;
BA_ "U_T6_MCA_MY2020_Tx" SG_ 516 ApedPosPcActl_No_Cnt 1;
BA_ "U_P702_MY2021_Tx" SG_ 516 ApedPosPcActl_No_Cnt 1;
BA_ "MetaData" SG_ 516 ApedPosPcActl_No_Cnt 1;
BA_ "ContentDependant" SG_ 516 ApedPosPcActl_No_Cnt 1;
BA_ "CrossOver_InfoCAN" SG_ 516 ApedPosPcActl_No_Cnt 1;
BA_ "U_T6_MCA_MY2020_Tx" SG_ 516 ApedPosPcActl_No_Cs 1;
BA_ "U_P702_MY2021_Tx" SG_ 516 ApedPosPcActl_No_Cs 1;
BA_ "MetaData" SG_ 516 ApedPosPcActl_No_Cs 1;
BA_ "ContentDependant" SG_ 516 ApedPosPcActl_No_Cs 1;
BA_ "CrossOver_InfoCAN" SG_ 516 ApedPosPcActl_No_Cs 1;
BA_ "U_T6_MCA_MY2020_Tx" SG_ 514 StrtrMtrDlyStrt_B_Stat 1;
BA_ "U_P702_MY2021_Tx" SG_ 514 StrtrMtrDlyStrt_B_Stat 1;
BA_ "U_T6_MCA_MY2020_Tx" SG_ 514 VehVTrlrAid_B_Avail 1;
BA_ "U_P702_MY2021_Tx" SG_ 514 VehVTrlrAid_B_Avail 1;
BA_ "U_P702_MY2021_Rx" SG_ 514 VehVTrlrAid_B_Avail 1;
BA_ "U_T6_MCA_MY2020_Tx" SG_ 514 StrtrMtrCtlMsgTxt_D_Rq 1;
BA_ "U_P702_MY2021_Tx" SG_ 514 StrtrMtrCtlMsgTxt_D_Rq 1;
BA_ "CrossOver_InfoCAN" SG_ 514 StrtrMtrCtlMsgTxt_D_Rq 1;
BA_ "U_T6_MCA_MY2020_Tx" SG_ 514 VehVActlEng_No_Cs 1;
BA_ "U_P702_MY2021_Tx" SG_ 514 VehVActlEng_No_Cs 1;
BA_ "U_P702_MY2021_Rx" SG_ 514 VehVActlEng_No_Cs 1;
BA_ "U_CX727_MY2021_Rx" SG_ 514 VehVActlEng_No_Cs 1;
BA_ "MetaData" SG_ 514 VehVActlEng_No_Cs 1;
BA_ "CrossOver_InfoCAN" SG_ 514 VehVActlEng_No_Cs 1;
BA_ "U_T6_MCA_MY2020_Tx" SG_ 514 VehVActlEng_No_Cnt 1;
BA_ "U_P702_MY2021_Tx" SG_ 514 VehVActlEng_No_Cnt 1;
BA_ "U_P702_MY2021_Rx" SG_ 514 VehVActlEng_No_Cnt 1;
BA_ "U_CX727_MY2021_Rx" SG_ 514 VehVActlEng_No_Cnt 1;
BA_ "MetaData" SG_ 514 VehVActlEng_No_Cnt 1;
BA_ "CrossOver_InfoCAN" SG_ 514 VehVActlEng_No_Cnt 1;
BA_ "U_T6_MCA_MY2020_Tx" SG_ 514 Veh_V_RqCcSet 1;
BA_ "U_P702_MY2021_Tx" SG_ 514 Veh_V_RqCcSet 1;
BA_ "U_CX727_MY2021_Rx" SG_ 514 Veh_V_RqCcSet 1;
BA_ "U_T6_MCA_MY2020_Rx" SG_ 514 Veh_V_RqCcSet 1;
BA_ "U_P702_MY2021_Rx" SG_ 514 Veh_V_RqCcSet 1;
BA_ "CrossOver_InfoCAN" SG_ 514 Veh_V_RqCcSet 1;
BA_ "U_T6_MCA_MY2020_Tx" SG_ 514 VehVActlEng_D_Qf 1;
BA_ "U_P702_MY2021_Tx" SG_ 514 VehVActlEng_D_Qf 1;
BA_ "U_CX727_MY2021_Rx" SG_ 514 VehVActlEng_D_Qf 1;
BA_ "U_T6_MCA_MY2020_Rx" SG_ 514 VehVActlEng_D_Qf 1;
BA_ "U_P702_MY2021_Rx" SG_ 514 VehVActlEng_D_Qf 1;
BA_ "MetaData" SG_ 514 VehVActlEng_D_Qf 1;
BA_ "CrossOver_InfoCAN" SG_ 514 VehVActlEng_D_Qf 1;
BA_ "ECGUsedRxSignal" SG_ 514 Veh_V_ActlEng 1;
BA_ "U_T6_MCA_MY2020_Tx" SG_ 514 Veh_V_ActlEng 1;
BA_ "U_P702_MY2021_Tx" SG_ 514 Veh_V_ActlEng 1;
BA_ "U_CX727_MY2021_Rx" SG_ 514 Veh_V_ActlEng 1;
BA_ "U_T6_MCA_MY2020_Rx" SG_ 514 Veh_V_ActlEng 1;
BA_ "U_P702_MY2021_Rx" SG_ 514 Veh_V_ActlEng 1;
BA_ "CrossOver_InfoCAN" SG_ 514 Veh_V_ActlEng 1;
BA_ "ECGUsedRxSignal" SG_ 514 GearRvrse_D_Actl 1;
BA_ "U_T6_MCA_MY2020_Tx" SG_ 514 GearRvrse_D_Actl 1;
BA_ "U_P702_MY2021_Tx" SG_ 514 GearRvrse_D_Actl 1;
BA_ "U_P702_MY2021_Rx" SG_ 514 GearRvrse_D_Actl 1;
BA_ "U_CX727_MY2021_Rx" SG_ 514 GearRvrse_D_Actl 1;
BA_ "GenSigStartValue" SG_ 514 GearRvrse_D_Actl 7;
BA_ "GenSigStartValueInteger" SG_ 514 GearRvrse_D_Actl 7;
BA_ "CrossOver_InfoCAN" SG_ 514 GearRvrse_D_Actl 1;
BA_ "U_T6_MCA_MY2020_Tx" SG_ 514 StrtrMtrCtlMsgTxt_D2_Rq 1;
BA_ "U_P702_MY2021_Tx" SG_ 514 StrtrMtrCtlMsgTxt_D2_Rq 1;
BA_ "U_P702_MY2021_Tx" SG_ 512 PrplWhlTotTqRq_No_Cs 1;
BA_ "U_P702_MY2021_Rx" SG_ 512 PrplWhlTotTqRq_No_Cs 1;
BA_ "MetaData" SG_ 512 PrplWhlTotTqRq_No_Cs 1;
BA_ "ContentDependant" SG_ 512 PrplWhlTotTqRq_No_Cs 1;
BA_ "U_P702_MY2021_Tx" SG_ 512 PrplWhlTotTqRq_No_Cnt 1;
BA_ "U_P702_MY2021_Rx" SG_ 512 PrplWhlTotTqRq_No_Cnt 1;
BA_ "MetaData" SG_ 512 PrplWhlTotTqRq_No_Cnt 1;
BA_ "ContentDependant" SG_ 512 PrplWhlTotTqRq_No_Cnt 1;
BA_ "U_T6_MCA_MY2020_Tx" SG_ 512 PrplWhlTot_Tq_Rq 1;
BA_ "U_P702_MY2021_Tx" SG_ 512 PrplWhlTot_Tq_Rq 1;
BA_ "U_P702_MY2021_Rx" SG_ 512 PrplWhlTot_Tq_Rq 1;
BA_ "U_CX727_MY2021_Rx" SG_ 512 PrplWhlTot_Tq_Rq 1;
BA_ "U_T6_MCA_MY2020_Tx" SG_ 512 PrplWhlTot_Tq_LimMn 1;
BA_ "U_P702_MY2021_Tx" SG_ 512 PrplWhlTot_Tq_LimMn 1;
BA_ "U_P702_MY2021_Rx" SG_ 512 PrplWhlTot_Tq_LimMn 1;
BA_ "U_CX727_MY2021_Rx" SG_ 512 PrplWhlTot_Tq_LimMn 1;
BA_ "U_P702_MY2021_Tx" SG_ 512 PtDrvMde_D_Stat 1;
BA_ "U_T6_MCA_MY2020_Tx" SG_ 512 PtDrvMde_D_Stat 1;
BA_ "U_T6_MCA_MY2020_Tx" SG_ 381 EngOilLife_T_Actl 1;
BA_ "U_P702_MY2021_Tx" SG_ 381 EngOilLife_T_Actl 1;
BA_ "ECGUsedRxSignal" SG_ 381 EngOilSrvcMsgTxt_D_Rq 1;
BA_ "U_T6_MCA_MY2020_Tx" SG_ 381 EngOilSrvcMsgTxt_D_Rq 1;
BA_ "U_P702_MY2021_Tx" SG_ 381 EngOilSrvcMsgTxt_D_Rq 1;
BA_ "U_T6_MCA_MY2020_Tx" SG_ 381 DistToNextOilChange 1;
BA_ "U_P702_MY2021_Tx" SG_ 381 DistToNextOilChange 1;
BA_ "U_T6_MCA_MY2020_Tx" SG_ 381 RunDryPrevent_B_Stat 1;
BA_ "U_P702_MY2021_Tx" SG_ 381 RunDryPrevent_B_Stat 1;
BA_ "ECGUsedRxSignal" SG_ 381 WaterInFuel 1;
BA_ "U_T6_MCA_MY2020_Tx" SG_ 381 WaterInFuel 1;
BA_ "U_P702_MY2021_Tx" SG_ 381 WaterInFuel 1;
BA_ "CrossOver_InfoCAN" SG_ 381 WaterInFuel 1;
BA_ "U_T6_MCA_MY2020_Tx" SG_ 381 GlowIndication 1;
BA_ "U_P702_MY2021_Tx" SG_ 381 GlowIndication 1;
BA_ "CrossOver_InfoCAN" SG_ 381 GlowIndication 1;
BA_ "U_T6_MCA_MY2020_Tx" SG_ 380 EngOilLvlWarn_D_Rq1 1;
BA_ "U_P702_MY2021_Tx" SG_ 380 EngOilLvlWarn_D_Rq1 1;
BA_ "CrossOver_InfoCAN" SG_ 380 EngOilLvlWarn_D_Rq1 1;
BA_ "WakeupSignal" SG_ 380 EngOilLvlWarn_D_Rq1 1;
BA_ "U_T6_MCA_MY2020_Tx" SG_ 380 EngExhBrkOnLamp_B_Rq 1;
BA_ "U_P702_MY2021_Tx" SG_ 380 EngExhBrkOnLamp_B_Rq 1;
BA_ "CrossOver_InfoCAN" SG_ 380 EngExhBrkOnLamp_B_Rq 1;
BA_ "U_T6_MCA_MY2020_Tx" SG_ 380 EngExhBrkAutoLamp_B_Rq 1;
BA_ "U_P702_MY2021_Tx" SG_ 380 EngExhBrkAutoLamp_B_Rq 1;
BA_ "CrossOver_InfoCAN" SG_ 380 EngExhBrkAutoLamp_B_Rq 1;
BA_ "U_T6_MCA_MY2020_Tx" SG_ 380 EngAout_N_MxAllw 1;
BA_ "U_P702_MY2021_Tx" SG_ 380 EngAout_N_MxAllw 1;
BA_ "CrossOver_InfoCAN" SG_ 380 EngAout_N_MxAllw 1;
BA_ "U_T6_MCA_MY2020_Tx" SG_ 380 EngExhBrkMde_D_Actl 1;
BA_ "U_P702_MY2021_Tx" SG_ 380 EngExhBrkMde_D_Actl 1;
BA_ "U_T6_MCA_MY2020_Rx" SG_ 380 EngExhBrkMde_D_Actl 1;
BA_ "U_P702_MY2021_Rx" SG_ 380 EngExhBrkMde_D_Actl 1;
BA_ "CrossOver_InfoCAN" SG_ 380 EngExhBrkMde_D_Actl 1;
BA_ "U_P702_MY2021_Tx" SG_ 377 HvacAirFullOut_B_Rq 1;
BA_ "ECGUsedRxSignal" SG_ 377 FuelFlw_Vl_Dsply 1;
BA_ "U_T6_MCA_MY2020_Tx" SG_ 377 FuelFlw_Vl_Dsply 1;
BA_ "U_P702_MY2021_Tx" SG_ 377 FuelFlw_Vl_Dsply 1;
BA_ "ContentDependant" SG_ 377 FuelFlw_Vl_Dsply 1;
BA_ "CrossOver_InfoCAN" SG_ 377 FuelFlw_Vl_Dsply 1;
BA_ "U_T6_MCA_MY2020_Tx" SG_ 377 FuelFillInlet_B_Dsply 1;
BA_ "U_P702_MY2021_Tx" SG_ 377 FuelFillInlet_B_Dsply 1;
BA_ "ContentDependant" SG_ 377 FuelFillInlet_B_Dsply 1;
BA_ "CrossOver_InfoCAN" SG_ 377 FuelFillInlet_B_Dsply 1;
BA_ "ECGUsedRxSignal" SG_ 377 EngSrvcRqd_B_Rq 1;
BA_ "U_T6_MCA_MY2020_Tx" SG_ 377 EngSrvcRqd_B_Rq 1;
BA_ "U_P702_MY2021_Tx" SG_ 377 EngSrvcRqd_B_Rq 1;
BA_ "CrossOver_InfoCAN" SG_ 377 EngSrvcRqd_B_Rq 1;
BA_ "U_T6_MCA_MY2020_Tx" SG_ 377 OdoCount 1;
BA_ "U_P702_MY2021_Tx" SG_ 377 OdoCount 1;
BA_ "ContentDependant" SG_ 377 OdoCount 1;
BA_ "CrossOver_InfoCAN" SG_ 377 OdoCount 1;
BA_ "ECGUsedRxSignal" SG_ 377 EngOilLife_Pc_Actl 1;
BA_ "U_T6_MCA_MY2020_Tx" SG_ 377 EngOilLife_Pc_Actl 1;
BA_ "U_P702_MY2021_Tx" SG_ 377 EngOilLife_Pc_Actl 1;
BA_ "ContentDependant" SG_ 377 EngOilLife_Pc_Actl 1;
BA_ "CrossOver_InfoCAN" SG_ 377 EngOilLife_Pc_Actl 1;
BA_ "ECGUsedRxSignal" SG_ 377 FuelFilterLamp_B_Dsply 1;
BA_ "U_T6_MCA_MY2020_Tx" SG_ 377 FuelFilterLamp_B_Dsply 1;
BA_ "U_P702_MY2021_Tx" SG_ 377 FuelFilterLamp_B_Dsply 1;
BA_ "CrossOver_InfoCAN" SG_ 377 FuelFilterLamp_B_Dsply 1;
BA_ "U_T6_MCA_MY2020_Tx" SG_ 377 AirCondRec_B_Rq 1;
BA_ "U_P702_MY2021_Tx" SG_ 377 AirCondRec_B_Rq 1;
BA_ "ContentDependant" SG_ 377 AirCondRec_B_Rq 1;
BA_ "CrossOver_InfoCAN" SG_ 377 AirCondRec_B_Rq 1;
BA_ "U_T6_MCA_MY2020_Tx" SG_ 377 AirCondClutch_B_Stats 1;
BA_ "U_P702_MY2021_Tx" SG_ 377 AirCondClutch_B_Stats 1;
BA_ "ContentDependant" SG_ 377 AirCondClutch_B_Stats 1;
BA_ "CrossOver_InfoCAN" SG_ 377 AirCondClutch_B_Stats 1;
BA_ "U_T6_MCA_MY2020_Tx" SG_ 376 GasPrtc_D_RqDsply 1;
BA_ "U_P702_MY2021_Tx" SG_ 376 GasPrtc_D_RqDsply 1;
BA_ "U_T6_MCA_MY2020_Tx" SG_ 376 EngAout_Aa_Actl 1;
BA_ "U_P702_MY2021_Tx" SG_ 376 EngAout_Aa_Actl 1;
BA_ "U_P702_MY2021_Rx" SG_ 376 EngAout_Aa_Actl 1;
BA_ "U_CX727_MY2021_Rx" SG_ 376 EngAout_Aa_Actl 1;
BA_ "ContentDependant" SG_ 376 EngAout_Aa_Actl 1;
BA_ "CrossOver_InfoCAN" SG_ 376 EngAout_Aa_Actl 1;
BA_ "U_T6_MCA_MY2020_Tx" SG_ 376 DynoMde_B_Cmd 1;
BA_ "U_P702_MY2021_Tx" SG_ 376 DynoMde_B_Cmd 1;
BA_ "U_T6_MCA_MY2020_Rx" SG_ 376 DynoMde_B_Cmd 1;
BA_ "U_P702_MY2021_Rx" SG_ 376 DynoMde_B_Cmd 1;
BA_ "U_CX727_MY2021_Rx" SG_ 376 DynoMde_B_Cmd 1;
BA_ "U_T6_MCA_MY2020_Tx" SG_ 376 AslIconDsply_D_Rq 1;
BA_ "U_P702_MY2021_Tx" SG_ 376 AslIconDsply_D_Rq 1;
BA_ "U_T6_MCA_MY2020_Tx" SG_ 376 AslChime_B_Rq 1;
BA_ "U_P702_MY2021_Tx" SG_ 376 AslChime_B_Rq 1;
BA_ "U_P702_MY2021_Tx" SG_ 376 HvacHtrCore2_Te_Actl 1;
BA_ "GenSigStartValueInteger" SG_ 376 HvacHtrCore2_Te_Actl 200;
BA_ "U_T6_MCA_MY2020_Tx" SG_ 376 EcssLamp_D_RqDsply 1;
BA_ "U_P702_MY2021_Tx" SG_ 376 EcssLamp_D_RqDsply 1;
BA_ "U_T6_MCA_MY2020_Tx" SG_ 376 AirAmbTe_D_Qf 1;
BA_ "U_P702_MY2021_Tx" SG_ 376 AirAmbTe_D_Qf 1;
BA_ "U_CX727_MY2021_Rx" SG_ 376 AirAmbTe_D_Qf 1;
BA_ "U_P702_MY2021_Rx" SG_ 376 AirAmbTe_D_Qf 1;
BA_ "GenSigStartValue" SG_ 376 AirAmbTe_D_Qf 1;
BA_ "MetaData" SG_ 376 AirAmbTe_D_Qf 1;
BA_ "GenSigStartValueInteger" SG_ 376 AirAmbTe_D_Qf 1;
BA_ "CrossOver_InfoCAN" SG_ 376 AirAmbTe_D_Qf 1;
BA_ "ECGUsedRxSignal" SG_ 376 AirAmb_Te_ActlFilt 1;
BA_ "U_T6_MCA_MY2020_Tx" SG_ 376 AirAmb_Te_ActlFilt 1;
BA_ "U_P702_MY2021_Tx" SG_ 376 AirAmb_Te_ActlFilt 1;
BA_ "GenSigStartValueInteger" SG_ 376 AirAmb_Te_ActlFilt 512;
BA_ "CrossOver_InfoCAN" SG_ 376 AirAmb_Te_ActlFilt 1;
BA_ "U_T6_MCA_MY2020_Tx" SG_ 376 AirAmb_Te_Actl 1;
BA_ "U_P702_MY2021_Tx" SG_ 376 AirAmb_Te_Actl 1;
BA_ "U_CX727_MY2021_Rx" SG_ 376 AirAmb_Te_Actl 1;
BA_ "U_P702_MY2021_Rx" SG_ 376 AirAmb_Te_Actl 1;
BA_ "GenSigStartValueInteger" SG_ 376 AirAmb_Te_Actl 512;
BA_ "CrossOver_InfoCAN" SG_ 376 AirAmb_Te_Actl 1;
BA_ "U_T6_MCA_MY2020_Tx" SG_ 376 AirAmb_P_Actl 1;
BA_ "U_P702_MY2021_Tx" SG_ 376 AirAmb_P_Actl 1;
BA_ "U_T6_MCA_MY2020_Rx" SG_ 376 AirAmb_P_Actl 1;
BA_ "U_P702_MY2021_Rx" SG_ 376 AirAmb_P_Actl 1;
BA_ "CrossOver_InfoCAN" SG_ 376 AirAmb_P_Actl 1;
BA_ "ECGUsedRxSignal" SG_ 373 DieslPrtc2_D_RqDsply 1;
BA_ "U_T6_MCA_MY2020_Tx" SG_ 373 DieslPrtc2_D_RqDsply 1;
BA_ "U_P702_MY2021_Tx" SG_ 373 DieslPrtc2_D_RqDsply 1;
BA_ "U_T6_MCA_MY2020_Tx" SG_ 373 DieslPrtcRgen_D_Actl 1;
BA_ "U_P702_MY2021_Tx" SG_ 373 DieslPrtcRgen_D_Actl 1;
BA_ "U_T6_MCA_MY2020_Rx" SG_ 373 DieslPrtcRgen_D_Actl 1;
BA_ "U_P702_MY2021_Rx" SG_ 373 DieslPrtcRgen_D_Actl 1;
BA_ "CrossOver_InfoCAN" SG_ 373 DieslPrtcRgen_D_Actl 1;
BA_ "U_T6_MCA_MY2020_Tx" SG_ 373 EngTeColdPrtct_D_Stats 1;
BA_ "U_P702_MY2021_Tx" SG_ 373 EngTeColdPrtct_D_Stats 1;
BA_ "CrossOver_InfoCAN" SG_ 373 EngTeColdPrtct_D_Stats 1;
BA_ "ECGUsedRxSignal" SG_ 373 EngExhOvrTe_B_RqDsply 1;
BA_ "U_T6_MCA_MY2020_Tx" SG_ 373 EngExhOvrTe_B_RqDsply 1;
BA_ "U_P702_MY2021_Tx" SG_ 373 EngExhOvrTe_B_RqDsply 1;
BA_ "CrossOver_InfoCAN" SG_ 373 EngExhOvrTe_B_RqDsply 1;
BA_ "U_P702_MY2021_Tx" SG_ 359 PrplWhlRgenMn_Tq_Actl 1;
BA_ "U_P702_MY2021_Rx" SG_ 359 PrplWhlRgenMn_Tq_Actl 1;
BA_ "U_CX727_MY2021_Rx" SG_ 359 PrplWhlRgenMn_Tq_Actl 1;
BA_ "GenSigStartValueInteger" SG_ 359 PrplWhlRgenMn_Tq_Actl 4095;
BA_ "U_T6_MCA_MY2020_Tx" SG_ 359 ElPw_D_StatStrtStop 1;
BA_ "U_P702_MY2021_Tx" SG_ 359 ElPw_D_StatStrtStop 1;
BA_ "U_P702_MY2021_Rx" SG_ 359 ElPw_D_StatStrtStop 1;
BA_ "CrossOver_InfoCAN" SG_ 359 ElPw_D_StatStrtStop 1;
BA_ "U_T6_MCA_MY2020_Tx" SG_ 359 TrnAin_Tq_Actl 1;
BA_ "U_P702_MY2021_Tx" SG_ 359 TrnAin_Tq_Actl 1;
BA_ "U_P702_MY2021_Rx" SG_ 359 TrnAin_Tq_Actl 1;
BA_ "U_CX727_MY2021_Rx" SG_ 359 TrnAin_Tq_Actl 1;
BA_ "ContentDependant" SG_ 359 TrnAin_Tq_Actl 1;
BA_ "CrossOver_InfoCAN" SG_ 359 TrnAin_Tq_Actl 1;
BA_ "ECGUsedRxSignal" SG_ 359 PrplWhlTot2_Tq_Actl 1;
BA_ "U_T6_MCA_MY2020_Tx" SG_ 359 PrplWhlTot2_Tq_Actl 1;
BA_ "U_P702_MY2021_Tx" SG_ 359 PrplWhlTot2_Tq_Actl 1;
BA_ "U_CX727_MY2021_Rx" SG_ 359 PrplWhlTot2_Tq_Actl 1;
BA_ "U_P702_MY2021_Rx" SG_ 359 PrplWhlTot2_Tq_Actl 1;
BA_ "CrossOver_InfoCAN" SG_ 359 PrplWhlTot2_Tq_Actl 1;
BA_ "ECGUsedRxSignal" SG_ 359 PwPckTq_D_Stat 1;
BA_ "U_T6_MCA_MY2020_Tx" SG_ 359 PwPckTq_D_Stat 1;
BA_ "U_P702_MY2021_Tx" SG_ 359 PwPckTq_D_Stat 1;
BA_ "U_CX727_MY2021_Rx" SG_ 359 PwPckTq_D_Stat 1;
BA_ "U_T6_MCA_MY2020_Rx" SG_ 359 PwPckTq_D_Stat 1;
BA_ "U_P702_MY2021_Rx" SG_ 359 PwPckTq_D_Stat 1;
BA_ "CrossOver_InfoCAN" SG_ 359 PwPckTq_D_Stat 1;
BA_ "ECGUsedRxSignal" SG_ 359 Eng_D_Stat 1;
BA_ "U_T6_MCA_MY2020_Tx" SG_ 359 Eng_D_Stat 1;
BA_ "U_P702_MY2021_Tx" SG_ 359 Eng_D_Stat 1;
BA_ "U_P702_MY2021_Rx" SG_ 359 Eng_D_Stat 1;
BA_ "U_CX727_MY2021_Rx" SG_ 359 Eng_D_Stat 1;
BA_ "CrossOver_InfoCAN" SG_ 359 Eng_D_Stat 1;
BA_ "ECGUsedRxSignal" SG_ 359 PlgActvArb_B_Actl 1;
BA_ "GenSigStartValue" SG_ 359 PlgActvArb_B_Actl 1;
BA_ "ContentDependant" SG_ 359 PlgActvArb_B_Actl 1;
BA_ "GenSigStartValueInteger" SG_ 359 PlgActvArb_B_Actl 1;
BA_ "CrossOver_InfoCAN" SG_ 359 PlgActvArb_B_Actl 1;
BA_ "U_T6_MCA_MY2020_Tx" SG_ 359 ElPw_D_Stat 1;
BA_ "U_P702_MY2021_Tx" SG_ 359 ElPw_D_Stat 1;
BA_ "U_CX727_MY2021_Rx" SG_ 359 ElPw_D_Stat 1;
BA_ "U_T6_MCA_MY2020_Rx" SG_ 359 ElPw_D_Stat 1;
BA_ "U_P702_MY2021_Rx" SG_ 359 ElPw_D_Stat 1;
BA_ "CrossOver_InfoCAN" SG_ 359 ElPw_D_Stat 1;
BA_ "U_T6_MCA_MY2020_Tx" SG_ 359 TrnAinTq_D_Qf 1;
BA_ "U_P702_MY2021_Tx" SG_ 359 TrnAinTq_D_Qf 1;
BA_ "U_P702_MY2021_Rx" SG_ 359 TrnAinTq_D_Qf 1;
BA_ "U_CX727_MY2021_Rx" SG_ 359 TrnAinTq_D_Qf 1;
BA_ "MetaData" SG_ 359 TrnAinTq_D_Qf 1;
BA_ "ContentDependant" SG_ 359 TrnAinTq_D_Qf 1;
BA_ "CrossOver_InfoCAN" SG_ 359 TrnAinTq_D_Qf 1;
BA_ "U_T6_MCA_MY2020_Tx" SG_ 358 StopStrtStdby_D_Indic 1;
BA_ "U_P702_MY2021_Tx" SG_ 358 StopStrtStdby_D_Indic 1;
BA_ "CrossOver_InfoCAN" SG_ 358 StopStrtStdby_D_Indic 1;
BA_ "U_T6_MCA_MY2020_Tx" SG_ 358 StopStrtIODTxt_D_Rq 1;
BA_ "U_P702_MY2021_Tx" SG_ 358 StopStrtIODTxt_D_Rq 1;
BA_ "CrossOver_InfoCAN" SG_ 358 StopStrtIODTxt_D_Rq 1;
BA_ "U_T6_MCA_MY2020_Tx" SG_ 358 StopStrtDrvMde_D_Indic 1;
BA_ "U_P702_MY2021_Tx" SG_ 358 StopStrtDrvMde_D_Indic 1;
BA_ "CrossOver_InfoCAN" SG_ 358 StopStrtDrvMde_D_Indic 1;
BA_ "U_T6_MCA_MY2020_Tx" SG_ 358 StopStrtMsgTxt_D_Rq 1;
BA_ "U_P702_MY2021_Tx" SG_ 358 StopStrtMsgTxt_D_Rq 1;
BA_ "CrossOver_InfoCAN" SG_ 358 StopStrtMsgTxt_D_Rq 1;
BA_ "U_T6_MCA_MY2020_Tx" SG_ 358 OdoTripVerify_L_Actl 1;
BA_ "U_P702_MY2021_Tx" SG_ 358 OdoTripVerify_L_Actl 1;
BA_ "CrossOver_InfoCAN" SG_ 358 OdoTripVerify_L_Actl 1;
BA_ "U_T6_MCA_MY2020_Tx" SG_ 358 HiElPwInhbt_B_Stat 1;
BA_ "U_P702_MY2021_Tx" SG_ 358 HiElPwInhbt_B_Stat 1;
BA_ "ContentDependant" SG_ 358 HiElPwInhbt_B_Stat 1;
BA_ "CrossOver_InfoCAN" SG_ 358 HiElPwInhbt_B_Stat 1;
BA_ "U_T6_MCA_MY2020_Tx" SG_ 358 AutoStopPtDelta_I_Est 1;
BA_ "U_P702_MY2021_Tx" SG_ 358 AutoStopPtDelta_I_Est 1;
BA_ "ContentDependant" SG_ 358 AutoStopPtDelta_I_Est 1;
BA_ "GenSigStartValueInteger" SG_ 358 AutoStopPtDelta_I_Est 127;
BA_ "CrossOver_InfoCAN" SG_ 358 AutoStopPtDelta_I_Est 1;
BA_ "U_T6_MCA_MY2020_Tx" SG_ 357 BPedDrvAppl_D_QF 1;
BA_ "U_P702_MY2021_Tx" SG_ 357 BPedDrvAppl_D_QF 1;
BA_ "U_CX727_MY2021_Rx" SG_ 357 BPedDrvAppl_D_QF 1;
BA_ "U_T6_MCA_MY2020_Rx" SG_ 357 BPedDrvAppl_D_QF 1;
BA_ "U_P702_MY2021_Rx" SG_ 357 BPedDrvAppl_D_QF 1;
BA_ "GenSigStartValue" SG_ 357 BPedDrvAppl_D_QF 1;
BA_ "MetaData" SG_ 357 BPedDrvAppl_D_QF 1;
BA_ "GenSigStartValueInteger" SG_ 357 BPedDrvAppl_D_QF 1;
BA_ "U_T6_MCA_MY2020_Tx" SG_ 357 CmbbDeny_B_ActlPrpl 1;
BA_ "U_P702_MY2021_Tx" SG_ 357 CmbbDeny_B_ActlPrpl 1;
BA_ "U_T6_MCA_MY2020_Tx" SG_ 357 PrplTqMnSat_B_Actl 1;
BA_ "U_P702_MY2021_Tx" SG_ 357 PrplTqMnSat_B_Actl 1;
BA_ "ECGUsedRxSignal" SG_ 357 BpedDrvAppl_D_Actl 1;
BA_ "U_T6_MCA_MY2020_Tx" SG_ 357 BpedDrvAppl_D_Actl 1;
BA_ "U_P702_MY2021_Tx" SG_ 357 BpedDrvAppl_D_Actl 1;
BA_ "U_CX727_MY2021_Rx" SG_ 357 BpedDrvAppl_D_Actl 1;
BA_ "U_T6_MCA_MY2020_Rx" SG_ 357 BpedDrvAppl_D_Actl 1;
BA_ "U_P702_MY2021_Rx" SG_ 357 BpedDrvAppl_D_Actl 1;
BA_ "GenSigStartValue" SG_ 357 BpedDrvAppl_D_Actl 1;
BA_ "GenSigStartValueInteger" SG_ 357 BpedDrvAppl_D_Actl 1;
BA_ "CrossOver_InfoCAN" SG_ 357 BpedDrvAppl_D_Actl 1;
BA_ "U_T6_MCA_MY2020_Tx" SG_ 357 CmbbEngTqMn_B_Actl 1;
BA_ "U_P702_MY2021_Tx" SG_ 357 CmbbEngTqMn_B_Actl 1;
BA_ "U_T6_MCA_MY2020_Tx" SG_ 357 Veh_V_DsplyCcSet 1;
BA_ "U_P702_MY2021_Tx" SG_ 357 Veh_V_DsplyCcSet 1;
BA_ "CrossOver_InfoCAN" SG_ 357 Veh_V_DsplyCcSet 1;
BA_ "U_T6_MCA_MY2020_Tx" SG_ 357 AccEngStat_D_Actl 1;
BA_ "U_P702_MY2021_Tx" SG_ 357 AccEngStat_D_Actl 1;
BA_ "U_T6_MCA_MY2020_Tx" SG_ 357 CcMde_D_Actl 1;
BA_ "U_P702_MY2021_Tx" SG_ 357 CcMde_D_Actl 1;
BA_ "U_T6_MCA_MY2020_Rx" SG_ 357 CcMde_D_Actl 1;
BA_ "U_P702_MY2021_Rx" SG_ 357 CcMde_D_Actl 1;
BA_ "U_CX727_MY2021_Rx" SG_ 357 CcMde_D_Actl 1;
BA_ "U_T6_MCA_MY2020_Tx" SG_ 357 CcStat_D_Actl 1;
BA_ "U_P702_MY2021_Tx" SG_ 357 CcStat_D_Actl 1;
BA_ "U_CX727_MY2021_Rx" SG_ 357 CcStat_D_Actl 1;
BA_ "U_T6_MCA_MY2020_Rx" SG_ 357 CcStat_D_Actl 1;
BA_ "U_P702_MY2021_Rx" SG_ 357 CcStat_D_Actl 1;
BA_ "CrossOver_InfoCAN" SG_ 357 CcStat_D_Actl 1;
BA_ "U_P702_MY2021_Tx" SG_ 357 EngAout_N_MnAllw 1;
BA_ "U_T6_MCA_MY2020_Tx" SG_ 357 CcOvrrdActv_B_Actl 1;
BA_ "U_P702_MY2021_Tx" SG_ 357 CcOvrrdActv_B_Actl 1;
BA_ "U_CX727_MY2021_Rx" SG_ 357 CcOvrrdActv_B_Actl 1;
BA_ "U_T6_MCA_MY2020_Rx" SG_ 357 CcOvrrdActv_B_Actl 1;
BA_ "U_P702_MY2021_Rx" SG_ 357 CcOvrrdActv_B_Actl 1;
BA_ "CrossOver_InfoCAN" SG_ 357 CcOvrrdActv_B_Actl 1;
BA_ "U_T6_MCA_MY2020_Tx" SG_ 357 AccStopMde_D_Rq 1;
BA_ "U_P702_MY2021_Tx" SG_ 357 AccStopMde_D_Rq 1;
BA_ "U_P702_MY2021_Rx" SG_ 357 AccStopMde_D_Rq 1;
BA_ "U_CX727_MY2021_Rx" SG_ 357 AccStopMde_D_Rq 1;
BA_ "ECGUsedRxSignal" SG_ 355 AutoRgenTxt_B_RqDsply 1;
BA_ "U_T6_MCA_MY2020_Tx" SG_ 355 AutoRgenTxt_B_RqDsply 1;
BA_ "U_P702_MY2021_Tx" SG_ 355 AutoRgenTxt_B_RqDsply 1;
BA_ "U_T6_MCA_MY2020_Tx" SG_ 355 AccFllwMdeActv_B_Actl 1;
BA_ "U_P702_MY2021_Tx" SG_ 355 AccFllwMdeActv_B_Actl 1;
BA_ "CrossOver_InfoCAN" SG_ 355 AccFllwMdeActv_B_Actl 1;
BA_ "U_T6_MCA_MY2020_Tx" SG_ 355 EngPtoMde_D_Actl 1;
BA_ "U_P702_MY2021_Tx" SG_ 355 EngPtoMde_D_Actl 1;
BA_ "CrossOver_InfoCAN" SG_ 355 EngPtoMde_D_Actl 1;
BA_ "ECGUsedRxSignal" SG_ 355 ManRgenTxt_D_RqDsply 1;
BA_ "U_T6_MCA_MY2020_Tx" SG_ 355 ManRgenTxt_D_RqDsply 1;
BA_ "U_P702_MY2021_Tx" SG_ 355 ManRgenTxt_D_RqDsply 1;
BA_ "CrossOver_InfoCAN" SG_ 355 ManRgenTxt_D_RqDsply 1;
BA_ "ECGUsedRxSignal" SG_ 355 ManRgenSoot_Pc_RqDsply 1;
BA_ "U_T6_MCA_MY2020_Tx" SG_ 355 ManRgenSoot_Pc_RqDsply 1;
BA_ "U_P702_MY2021_Tx" SG_ 355 ManRgenSoot_Pc_RqDsply 1;
BA_ "CrossOver_InfoCAN" SG_ 355 ManRgenSoot_Pc_RqDsply 1;
BA_ "U_T6_MCA_MY2020_Tx" SG_ 355 DieslMsgTxt_D_Rq 1;
BA_ "U_P702_MY2021_Tx" SG_ 355 DieslMsgTxt_D_Rq 1;
BA_ "U_T6_MCA_MY2020_Tx" SG_ 342 EngOvrhtMitgActv_D_Ind 1;
BA_ "U_P702_MY2021_Tx" SG_ 342 EngOvrhtMitgActv_D_Ind 1;
BA_ "ContentDependant" SG_ 342 EngOvrhtMitgActv_D_Ind 1;
BA_ "CrossOver_InfoCAN" SG_ 342 EngOvrhtMitgActv_D_Ind 1;
BA_ "U_T6_MCA_MY2020_Tx" SG_ 342 EngClntTe_D_Qf 1;
BA_ "U_P702_MY2021_Tx" SG_ 342 EngClntTe_D_Qf 1;
BA_ "U_T6_MCA_MY2020_Rx" SG_ 342 EngClntTe_D_Qf 1;
BA_ "U_P702_MY2021_Rx" SG_ 342 EngClntTe_D_Qf 1;
BA_ "MetaData" SG_ 342 EngClntTe_D_Qf 1;
BA_ "CrossOver_InfoCAN" SG_ 342 EngClntTe_D_Qf 1;
BA_ "U_P702_MY2021_Tx" SG_ 342 EngGoutLss_Tq_Est 1;
BA_ "ContentDependant" SG_ 342 EngGoutLss_Tq_Est 1;
BA_ "CrossOver_InfoCAN" SG_ 342 EngGoutLss_Tq_Est 1;
BA_ "U_T6_MCA_MY2020_Tx" SG_ 342 EngOil_Te_Actl 1;
BA_ "U_P702_MY2021_Tx" SG_ 342 EngOil_Te_Actl 1;
BA_ "CrossOver_InfoCAN" SG_ 342 EngOil_Te_Actl 1;
BA_ "ECGUsedRxSignal" SG_ 342 EngClnt_Te_Actl 1;
BA_ "U_T6_MCA_MY2020_Tx" SG_ 342 EngClnt_Te_Actl 1;
BA_ "U_P702_MY2021_Tx" SG_ 342 EngClnt_Te_Actl 1;
BA_ "U_T6_MCA_MY2020_Rx" SG_ 342 EngClnt_Te_Actl 1;
BA_ "U_P702_MY2021_Rx" SG_ 342 EngClnt_Te_Actl 1;
BA_ "CrossOver_InfoCAN" SG_ 342 EngClnt_Te_Actl 1;
BA_ "U_T6_MCA_MY2020_Tx" SG_ 71 immoTarget1Status 1;
BA_ "U_P702_MY2021_Tx" SG_ 71 immoTarget1Status 1;
BA_ "U_CX727_MY2021_Rx" SG_ 71 immoTarget1Status 1;
BA_ "U_T6_MCA_MY2020_Rx" SG_ 71 immoTarget1Status 1;
BA_ "U_P702_MY2021_Rx" SG_ 71 immoTarget1Status 1;
BA_ "U_T6_MCA_MY2020_Tx" SG_ 71 immoTarget1Data 1;
BA_ "U_P702_MY2021_Tx" SG_ 71 immoTarget1Data 1;
BA_ "U_P702_MY2021_Rx" SG_ 71 immoTarget1Data 1;
BA_ "U_CX727_MY2021_Rx" SG_ 71 immoTarget1Data 1;
BA_ "U_T6_MCA_MY2020_Tx" SG_ 71 immoTarget1Cmd 1;
BA_ "U_P702_MY2021_Tx" SG_ 71 immoTarget1Cmd 1;
BA_ "U_P702_MY2021_Rx" SG_ 71 immoTarget1Cmd 1;
BA_ "U_CX727_MY2021_Rx" SG_ 71 immoTarget1Cmd 1;
BA_ "ECGUsedTxSignal" SG_ 1822 TesterPhysicalResGWM_F1 1;
BA_ "GenSigSendType" SG_ 1822 TesterPhysicalResGWM_F1 3;
BA_ "ECGUsedTxSignal" SG_ 1438 GWM_GWOnBoardTester 1;
BA_ "GenSigStartValue" SG_ 1438 GWM_GWOnBoardTester 255;
BA_ "ContentDependant" SG_ 1438 GWM_GWOnBoardTester 1;
BA_ "GenSigStartValueInteger" SG_ 1438 GWM_GWOnBoardTester 255;
BA_ "ECGUsedTxSignal" SG_ 1438 GWM_GWNMProxy 1;
BA_ "GenSigStartValue" SG_ 1438 GWM_GWNMProxy 255;
BA_ "ContentDependant" SG_ 1438 GWM_GWNMProxy 1;
BA_ "GenSigStartValueInteger" SG_ 1438 GWM_GWNMProxy 255;
BA_ "ECGUsedTxSignal" SG_ 1438 GWM_AutoSarNMReserved4 1;
BA_ "GenSigStartValue" SG_ 1438 GWM_AutoSarNMReserved4 255;
BA_ "ContentDependant" SG_ 1438 GWM_AutoSarNMReserved4 1;
BA_ "GenSigStartValueInteger" SG_ 1438 GWM_AutoSarNMReserved4 255;
BA_ "ECGUsedTxSignal" SG_ 1438 GWM_AutoSarNMReserved3 1;
BA_ "GenSigStartValue" SG_ 1438 GWM_AutoSarNMReserved3 255;
BA_ "ContentDependant" SG_ 1438 GWM_AutoSarNMReserved3 1;
BA_ "GenSigStartValueInteger" SG_ 1438 GWM_AutoSarNMReserved3 255;
BA_ "ECGUsedTxSignal" SG_ 1438 GWM_AutoSarNMReserved2 1;
BA_ "GenSigStartValue" SG_ 1438 GWM_AutoSarNMReserved2 255;
BA_ "ContentDependant" SG_ 1438 GWM_AutoSarNMReserved2 1;
BA_ "GenSigStartValueInteger" SG_ 1438 GWM_AutoSarNMReserved2 255;
BA_ "ECGUsedTxSignal" SG_ 1438 GWM_AutoSarNMReserved1 1;
BA_ "GenSigStartValue" SG_ 1438 GWM_AutoSarNMReserved1 255;
BA_ "ContentDependant" SG_ 1438 GWM_AutoSarNMReserved1 1;
BA_ "GenSigStartValueInteger" SG_ 1438 GWM_AutoSarNMReserved1 255;
BA_ "ECGUsedTxSignal" SG_ 1438 GWM_AutoSarNMNodeId 1;
BA_ "GenSigStartValue" SG_ 1438 GWM_AutoSarNMNodeId 158;
BA_ "ContentDependant" SG_ 1438 GWM_AutoSarNMNodeId 1;
BA_ "GenSigStartValueInteger" SG_ 1438 GWM_AutoSarNMNodeId 158;
BA_ "ECGUsedTxSignal" SG_ 1438 GWM_AutoSarNMControl 1;
BA_ "ContentDependant" SG_ 1438 GWM_AutoSarNMControl 1;
BA_ "U_P702_MY2021_Rx" SG_ 954 GenericSwtch3_No_Actl 1;
BA_ "U_P702_MY2021_Rx" SG_ 954 GenericSwtch2_No_Actl 1;
BA_ "ContentDependant" SG_ 954 GenericSwtch2_No_Actl 1;
BA_ "U_P702_MY2021_Rx" SG_ 954 GenericSwtch1_No_Actl 1;
BA_ "GenSigSendType" SG_ 1006 PersIndexIpmb_D_Actl 3;
BA_ "GenSigStartValue" SG_ 1006 PersIndexIpmb_D_Actl 4;
BA_ "GenSigStartValueInteger" SG_ 1006 PersIndexIpmb_D_Actl 4;
BA_ "CrossOver_InfoCAN" SG_ 1006 PersIndexIpmb_D_Actl 1;
BA_ "GenSigSendType" SG_ 1006 FeatNoIpmbActl 3;
BA_ "CrossOver_InfoCAN" SG_ 1006 FeatNoIpmbActl 1;
BA_ "GenSigSendType" SG_ 1006 FeatConfigIpmbActl 3;
BA_ "CrossOver_InfoCAN" SG_ 1006 FeatConfigIpmbActl 1;
BA_ "U_P702_MY2021_Tx" SG_ 820 AhbStatGfhbFdbk_D_Actl 1;
BA_ "GenSigSendType" SG_ 820 AhbStatGfhbFdbk_D_Actl 3;
BA_ "U_P702_MY2021_Tx" SG_ 820 HeadLghtDrvSide_B_Stat 1;
BA_ "GenSigSendType" SG_ 820 HeadLghtDrvSide_B_Stat 3;
BA_ "U_P702_MY2021_Tx" SG_ 820 HeadLghtHiOn_B_StatHcm 1;
BA_ "GenSigSendType" SG_ 820 HeadLghtHiOn_B_StatHcm 3;
BA_ "CrossOver_InfoCAN" SG_ 820 HeadLghtHiOn_B_StatHcm 1;
BA_ "U_P702_MY2021_Tx" SG_ 820 Adaptive_Hdlmp_Fault 1;
BA_ "GenSigSendType" SG_ 820 Adaptive_Hdlmp_Fault 3;
BA_ "CrossOver_InfoCAN" SG_ 820 Adaptive_Hdlmp_Fault 1;
BA_ "U_P702_MY2021_Rx" SG_ 137 SteWhlOffstRq_D_Stat 1;
BA_ "GenSigStartValue" SG_ 137 SteWhlOffstRq_D_Stat 2;
BA_ "GenSigStartValueInteger" SG_ 137 SteWhlOffstRq_D_Stat 2;
BA_ "U_P702_MY2021_Rx" SG_ 137 SteWhlOffst_An_TotActl 1;
BA_ "GenSigStartValue" SG_ 137 SteWhlOffst_An_TotActl 32765;
BA_ "GenSigStartValueInteger" SG_ 137 SteWhlOffst_An_TotActl 32766;
BA_ "U_P702_MY2021_Rx" SG_ 137 SteWhlBrkOffst_An_Actl 1;
BA_ "GenSigStartValue" SG_ 137 SteWhlBrkOffst_An_Actl 32765;
BA_ "GenSigStartValueInteger" SG_ 137 SteWhlBrkOffst_An_Actl 32766;
BA_ "U_P702_MY2021_Rx" SG_ 137 SteWhlBrkAnActl_No_Cs 1;
BA_ "MetaData" SG_ 137 SteWhlBrkAnActl_No_Cs 1;
BA_ "CrossOver_InfoCAN" SG_ 137 SteWhlBrkAnActl_No_Cs 1;
BA_ "U_P702_MY2021_Rx" SG_ 137 SteWhlBrkAnActl_No_Cnt 1;
BA_ "MetaData" SG_ 137 SteWhlBrkAnActl_No_Cnt 1;
BA_ "CrossOver_InfoCAN" SG_ 137 SteWhlBrkAnActl_No_Cnt 1;
BA_ "ContentDependant" SG_ 129 SelDrvMdeSwtch3_D_Stat4 1;
BA_ "U_P702_MY2021_Rx" SG_ 129 SelDrvMdeSwtch_D_Stat4 1;
BA_ "U_CX727_MY2021_Rx" SG_ 129 SelDrvMdeSwtch_D_Stat4 1;
BA_ "WakeupSignal" SG_ 129 SteWhlSwtchView_B_Stat 1;
BA_ "WakeupSignal" SG_ 129 SteWhlSwtchSet_B_Stat 1;
BA_ "WakeupSignal" SG_ 129 SteWhlSwtchPhon_B_Stat 1;
BA_ "WakeupSignal" SG_ 129 SteWhlSwtchNav_B_Stat 1;
BA_ "WakeupSignal" SG_ 129 SteWhlSwtchMed_B_Stat 1;
BA_ "WakeupSignal" SG_ 129 SteWhlSwtchIod_B_Stat 1;
BA_ "WakeupSignal" SG_ 129 SteWhlSwtchHud_B_Stat 1;
BA_ "WakeupSignal" SG_ 129 SteWhlSwtchBack_B_Stat 1;
BA_ "WakeupSignal" SG_ 129 SteWhlSwtchMenu_B_Stat 1;
BA_ "WakeupSignal" SG_ 129 SteWhlSwtchUp_B_Stat 1;
BA_ "WakeupSignal" SG_ 129 SteWhlSwtchRght_B_Stat 1;
BA_ "WakeupSignal" SG_ 129 SteWhlSwtchOk_B_Stat 1;
BA_ "WakeupSignal" SG_ 129 SteWhlSwtchLeft_B_Stat 1;
BA_ "WakeupSignal" SG_ 129 SteWhlSwtchDown_B_Stat 1;
BA_ "GenSigSendType" SG_ 935 SodRight_D_Stat 3;
BA_ "GenSigStartValue" SG_ 935 SodRight_D_Stat 2;
BA_ "GenSigStartValueInteger" SG_ 935 SodRight_D_Stat 2;
BA_ "CrossOver_InfoCAN" SG_ 935 SodRight_D_Stat 1;
BA_ "GenSigSendType" SG_ 935 CtaAlrtRight2_D_Stat 3;
BA_ "GenSigSendType" SG_ 935 BttRight_D_Stat 3;
BA_ "GenSigSendType" SG_ 935 BttRight_D_RqDrv 3;
BA_ "GenSigSendType" SG_ 935 CtaBrkRightMsgTxt_B_Rq 3;
BA_ "U_P702_MY2021_Rx" SG_ 935 CtaRightBrkEnbl_B_Rq 1;
BA_ "U_CX727_MY2021_Rx" SG_ 935 CtaRightBrkEnbl_B_Rq 1;
BA_ "GenSigSendType" SG_ 935 CtaRightBrkEnbl_B_Rq 3;
BA_ "U_P702_MY2021_Rx" SG_ 935 CtaRightBrkDecel_B_Rq 1;
BA_ "U_CX727_MY2021_Rx" SG_ 935 CtaRightBrkDecel_B_Rq 1;
BA_ "GenSigSendType" SG_ 935 CtaRightBrkDecel_B_Rq 3;
BA_ "GenSigStartValue" SG_ 935 Side_Detect_R_Illum 100;
BA_ "GenSigStartValueInteger" SG_ 935 Side_Detect_R_Illum 100;
BA_ "CrossOver_InfoCAN" SG_ 935 Side_Detect_R_Illum 1;
BA_ "GenSigSendType" SG_ 935 CtaSnsRight_D_Stat 3;
BA_ "CrossOver_InfoCAN" SG_ 935 CtaSnsRight_D_Stat 1;
BA_ "GenSigSendType" SG_ 935 CtaAlrtRight_D_Stat 3;
BA_ "CrossOver_InfoCAN" SG_ 935 CtaAlrtRight_D_Stat 1;
BA_ "GenSigSendType" SG_ 935 CtaRight_D_Stat 3;
BA_ "CrossOver_InfoCAN" SG_ 935 CtaRight_D_Stat 1;
BA_ "GenSigSendType" SG_ 935 SodSnsRight_D_Stat 3;
BA_ "CrossOver_InfoCAN" SG_ 935 SodSnsRight_D_Stat 1;
BA_ "GenSigSendType" SG_ 935 SodAlrtRight_D_Stat 3;
BA_ "CrossOver_InfoCAN" SG_ 935 SodAlrtRight_D_Stat 1;
BA_ "GenSigSendType" SG_ 935 SodDetctRight_D_Stat 3;
BA_ "CrossOver_InfoCAN" SG_ 935 SodDetctRight_D_Stat 1;
BA_ "GenSigStartValue" SG_ 935 SodWarnRight_Prd_Rq 14;
BA_ "GenSigStartValueInteger" SG_ 935 SodWarnRight_Prd_Rq 14;
BA_ "CrossOver_InfoCAN" SG_ 935 SodWarnRight_Prd_Rq 1;
BA_ "U_P702_MY2021_Rx" SG_ 1108 RCMSerialNoByte8 1;
BA_ "U_CX727_MY2021_Rx" SG_ 1108 RCMSerialNoByte8 1;
BA_ "U_P702_MY2021_Rx" SG_ 1108 RCMSerialNoByte7 1;
BA_ "U_CX727_MY2021_Rx" SG_ 1108 RCMSerialNoByte7 1;
BA_ "U_P702_MY2021_Rx" SG_ 1108 RCMSerialNoByte6 1;
BA_ "U_CX727_MY2021_Rx" SG_ 1108 RCMSerialNoByte6 1;
BA_ "U_P702_MY2021_Rx" SG_ 1108 RCMSerialNoByte5 1;
BA_ "U_CX727_MY2021_Rx" SG_ 1108 RCMSerialNoByte5 1;
BA_ "U_P702_MY2021_Rx" SG_ 1108 RCMSerialNoByte4 1;
BA_ "U_CX727_MY2021_Rx" SG_ 1108 RCMSerialNoByte4 1;
BA_ "U_P702_MY2021_Rx" SG_ 1108 RCMSerialNoByte3 1;
BA_ "U_CX727_MY2021_Rx" SG_ 1108 RCMSerialNoByte3 1;
BA_ "U_P702_MY2021_Rx" SG_ 1108 RCMSerialNoByte2 1;
BA_ "U_CX727_MY2021_Rx" SG_ 1108 RCMSerialNoByte2 1;
BA_ "U_P702_MY2021_Rx" SG_ 1108 RCMSerialNoByte1 1;
BA_ "U_CX727_MY2021_Rx" SG_ 1108 RCMSerialNoByte1 1;
BA_ "GenSigStartValue" SG_ 261 ChrgStatDsply_D_Rq 1;
BA_ "GenSigStartValueInteger" SG_ 261 ChrgStatDsply_D_Rq 1;
BA_ "U_P702_MY2021_Rx" SG_ 1146 TrlrAidSwtch_D_RqDrv 1;
BA_ "U_P702_MY2021_Rx" SG_ 1146 TrlrAidCtl_U_RqDrv 1;
BA_ "GenSigStartValue" SG_ 1146 TrlrAidCtl_U_RqDrv 4093;
BA_ "GenSigStartValueInteger" SG_ 1146 TrlrAidCtl_U_RqDrv 4094;
BA_ "U_P702_MY2021_Rx" SG_ 533 TrlrAidMde_D_Rq 1;
BA_ "GenSigStartValue" SG_ 533 OnbChrgGoTOn_D_Rq 2;
BA_ "GenSigStartValueInteger" SG_ 533 OnbChrgGoTOn_D_Rq 2;
BA_ "CrossOver_InfoCAN" SG_ 533 OnbChrgGoTOn_D_Rq 1;
BA_ "MetaData" SG_ 533 OnbChrgGoTMnte_D_Rq 1;
BA_ "CrossOver_InfoCAN" SG_ 533 OnbChrgGoTMnte_D_Rq 1;
BA_ "GenSigStartValue" SG_ 533 OnbChrgGoTHr_T_Rq 30;
BA_ "GenSigStartValueInteger" SG_ 533 OnbChrgGoTHr_T_Rq 30;
BA_ "MetaData" SG_ 533 OnbChrgGoTElement_D_Rq 1;
BA_ "CrossOver_InfoCAN" SG_ 533 OnbChrgGoTElement_D_Rq 1;
BA_ "CrossOver_InfoCAN" SG_ 533 OnbChrgGoTDelete_B_Rq 1;
BA_ "CrossOver_InfoCAN" SG_ 533 OnbChrgClearAll_B_Rq 1;
BA_ "CrossOver_InfoCAN" SG_ 533 OnbChrgGoTUpdate_B_Rq 1;
BA_ "U_P702_MY2021_Rx" SG_ 1041 ElCmpr_Pw_Actl 1;
BA_ "GenSigStartValue" SG_ 1067 BattULoAuxIsol_D_Rq 2;
BA_ "U_P702_MY2021_Rx" SG_ 1067 BattULoAuxIsol_D_Rq 1;
BA_ "GenSigStartValue" SG_ 1067 BattULoAux_U_Rq 3296;
BA_ "U_P702_MY2021_Rx" SG_ 1067 BattULoAux_U_Rq 1;
BA_ "U_P702_MY2021_Rx" SG_ 1067 BattULoAuxSoc_Pc_Actl 1;
BA_ "GenSigStartValue" SG_ 1067 BattULoAuxSoc_Pc_Actl 95;
BA_ "GenSigStartValueInteger" SG_ 1067 BattULoAuxSoc_Pc_Actl 95;
BA_ "U_P702_MY2021_Rx" SG_ 1067 BattULoAux_I_Actl 1;
BA_ "GenSigStartValueInteger" SG_ 1067 BattULoAux_I_Actl 2048;
BA_ "U_P702_MY2021_Rx" SG_ 1067 BattULoAux_D_Qlty 1;
BA_ "U_P702_MY2021_Rx" SG_ 1067 BattULoCrnkStrt_U_Pred 1;
BA_ "U_P702_MY2021_Rx" SG_ 1067 BattULoCrnkBelt_U_Pred 1;
BA_ "U_P702_MY2021_Rx" SG_ 1067 BattULoAux_U_Actl 1;
BA_ "GenSigStartValue" SG_ 1067 BattULoAux_U_Actl 203;
BA_ "GenSigStartValueInteger" SG_ 1067 BattULoAux_U_Actl 203;
BA_ "U_P702_MY2021_Rx" SG_ 1067 BattULoAux_B_Falt 1;
BA_ "CrossOver_InfoCAN" SG_ 1112 BattTracDiagClr_B_Rq 1;
BA_ "U_CX727_MY2021_Rx" SG_ 1112 BattTracChrgSustn_B_Rq 1;
BA_ "U_P702_MY2021_Rx" SG_ 1112 BattTracCnnct_D_Cmd 1;
BA_ "U_P702_MY2021_Rx" SG_ 1112 BattTracHvilOpen_B_Stat 1;
BA_ "U_P702_MY2021_Rx" SG_ 1112 BattTracDcdcDis_B_Rq 1;
BA_ "GenSigStartValue" SG_ 1112 BattTracDelta_Te_Actl 120;
BA_ "GenSigStartValueInteger" SG_ 1112 BattTracDelta_Te_Actl 164;
BA_ "ContentDependant" SG_ 1112 BattTracClntPmp_D_Stat 1;
BA_ "U_P702_MY2021_Rx" SG_ 139 AfsPw_B_Rq 1;
BA_ "U_T6_MCA_MY2020_Rx" SG_ 139 AfsPw_B_Rq 1;
BA_ "U_T6_MCA_MY2020_Rx" SG_ 139 ActvFrontSteLck_D_Stat 1;
BA_ "U_P702_MY2021_Rx" SG_ 139 ActvFrontSteLck_D_Stat 1;
BA_ "U_P702_MY2021_Rx" SG_ 139 SelDrvMdeAdptSte_D_Stat 1;
BA_ "U_P702_MY2021_Rx" SG_ 1121 SelDrvMdeSwtch_No_Actl 1;
BA_ "U_CX727_MY2021_Rx" SG_ 1121 SelDrvMdeSwtch_No_Actl 1;
BA_ "U_P702_MY2021_Rx" SG_ 1121 SelDrvMdeSwtch_D_Stat 1;
BA_ "U_CX727_MY2021_Rx" SG_ 1121 SelDrvMdeSwtch_D_Stat 1;
BA_ "U_P702_MY2021_Rx" SG_ 1121 SelDrvMdeCnt_D_Stat 1;
BA_ "U_CX727_MY2021_Rx" SG_ 1121 SelDrvMdeCnt_D_Stat 1;
BA_ "U_P702_MY2021_Rx" SG_ 1120 DrvSlipCtlMde_B_Rq3 1;
BA_ "CrossOver_InfoCAN" SG_ 1120 DrvSlipCtlMde_B_Rq3 1;
BA_ "U_P702_MY2021_Rx" SG_ 1120 HybMdeSwtch_B_Rq 1;
BA_ "U_P702_MY2021_Rx" SG_ 1120 RearDiffLck_D_RqDrv 1;
BA_ "GenSigStartValue" SG_ 1120 RearDiffLck_D_RqDrv 2;
BA_ "GenSigStartValueInteger" SG_ 1120 RearDiffLck_D_RqDrv 2;
BA_ "U_P702_MY2021_Rx" SG_ 1120 AwdMde_D_RqDrv 1;
BA_ "GenSigStartValue" SG_ 1120 AwdMde_D_RqDrv 5;
BA_ "GenSigStartValueInteger" SG_ 1120 AwdMde_D_RqDrv 5;
BA_ "U_P702_MY2021_Rx" SG_ 1120 HdcSwtchPos_B_Actl 1;
BA_ "U_T6_MCA_MY2020_Rx" SG_ 1050 Outside_Air_Temp_Stat 1;
BA_ "U_P702_MY2021_Rx" SG_ 1050 Outside_Air_Temp_Stat 1;
BA_ "GenSigStartValue" SG_ 1050 Outside_Air_Temp_Stat 254;
BA_ "GenSigStartValueInteger" SG_ 1050 Outside_Air_Temp_Stat 254;
BA_ "CrossOver_InfoCAN" SG_ 1050 Outside_Air_Temp_Stat 1;
BA_ "U_P702_MY2021_Tx" SG_ 1137 RngPerChrgAvg_L_Dsply 1;
BA_ "GenSigStartValue" SG_ 1137 RngPerChrgAvg_L_Dsply 4093;
BA_ "GenSigStartValueInteger" SG_ 1137 RngPerChrgAvg_L_Dsply 4094;
BA_ "GenSigStartValueInteger" SG_ 1255 BalrRight4Prev3Y_L_Actl 64;
BA_ "GenSigStartValueInteger" SG_ 1255 BalrRight4Prev3X_L_Actl 64;
BA_ "GenSigStartValueInteger" SG_ 1255 BalrRight4Prev2Y_L_Actl 64;
BA_ "GenSigStartValueInteger" SG_ 1255 BalrRight4Prev2X_L_Actl 64;
BA_ "GenSigStartValueInteger" SG_ 1255 BalrRight4Prev1Y_L_Actl 64;
BA_ "GenSigStartValueInteger" SG_ 1255 BalrRight4Prev1X_L_Actl 64;
BA_ "GenSigStartValueInteger" SG_ 1255 BalrRight4CurntY_L_Actl 64;
BA_ "GenSigStartValueInteger" SG_ 1255 BalrRight4CurntX_L_Actl 64;
BA_ "GenSigSendType" SG_ 1254 BalrRight3Threat_D_Stat 3;
BA_ "GenSigStartValueInteger" SG_ 1254 BalrRight3Prev3Y_L_Actl 64;
BA_ "GenSigStartValueInteger" SG_ 1254 BalrRight3Prev3X_L_Actl 64;
BA_ "GenSigStartValueInteger" SG_ 1254 BalrRight3Prev2Y_L_Actl 64;
BA_ "GenSigStartValueInteger" SG_ 1254 BalrRight3Prev2X_L_Actl 64;
BA_ "GenSigStartValueInteger" SG_ 1254 BalrRight3Prev1Y_L_Actl 64;
BA_ "GenSigStartValueInteger" SG_ 1254 BalrRight3Prev1X_L_Actl 64;
BA_ "GenSigSendType" SG_ 1254 BalrRight3Fast_B_Stat 3;
BA_ "GenSigSendType" SG_ 1254 BalrRight3Dsply_B_Stat 3;
BA_ "GenSigStartValueInteger" SG_ 1254 BalrRight3CurntY_L_Actl 64;
BA_ "GenSigStartValueInteger" SG_ 1254 BalrRight3CurntX_L_Actl 64;
BA_ "GenSigStartValueInteger" SG_ 1253 BalrRight2Prev3Y_L_Actl 64;
BA_ "GenSigStartValueInteger" SG_ 1253 BalrRight2Prev3X_L_Actl 64;
BA_ "GenSigSendType" SG_ 1253 BalrRight2Threat_D_Stat 3;
BA_ "GenSigStartValueInteger" SG_ 1253 BalrRight2Prev2Y_L_Actl 64;
BA_ "GenSigStartValueInteger" SG_ 1253 BalrRight2Prev2X_L_Actl 64;
BA_ "GenSigStartValueInteger" SG_ 1253 BalrRight2Prev1Y_L_Actl 64;
BA_ "GenSigStartValueInteger" SG_ 1253 BalrRight2Prev1X_L_Actl 64;
BA_ "GenSigSendType" SG_ 1253 BalrRight2Fast_B_Stat 3;
BA_ "GenSigSendType" SG_ 1253 BalrRight2Dsply_B_Stat 3;
BA_ "GenSigStartValueInteger" SG_ 1253 BalrRight2CurntY_L_Actl 64;
BA_ "GenSigStartValueInteger" SG_ 1253 BalrRight2CurntX_L_Actl 64;
BA_ "GenSigStartValueInteger" SG_ 1252 BalrRight1Prev3Y_L_Actl 64;
BA_ "GenSigStartValueInteger" SG_ 1252 BalrRight1Prev3X_L_Actl 64;
BA_ "GenSigSendType" SG_ 1252 BalrRight1Threat_D_Stat 3;
BA_ "GenSigStartValueInteger" SG_ 1252 BalrRight1Prev2Y_L_Actl 64;
BA_ "GenSigStartValueInteger" SG_ 1252 BalrRight1Prev2X_L_Actl 64;
BA_ "GenSigStartValueInteger" SG_ 1252 BalrRight1Prev1Y_L_Actl 64;
BA_ "GenSigStartValueInteger" SG_ 1252 BalrRight1Prev1X_L_Actl 64;
BA_ "GenSigSendType" SG_ 1252 BalrRight1Fast_B_Stat 3;
BA_ "GenSigSendType" SG_ 1252 BalrRight1Dsply_B_Stat 3;
BA_ "GenSigStartValueInteger" SG_ 1252 BalrRight1CurntY_L_Actl 64;
BA_ "GenSigStartValueInteger" SG_ 1252 BalrRight1CurntX_L_Actl 64;
BA_ "GenSigStartValueInteger" SG_ 1251 BalrLeft4Prev3Y_L_Actl 64;
BA_ "GenSigStartValueInteger" SG_ 1251 BalrLeft4Prev3X_L_Actl 64;
BA_ "GenSigStartValueInteger" SG_ 1251 BalrLeft4Prev2Y_L_Actl 64;
BA_ "GenSigStartValueInteger" SG_ 1251 BalrLeft4Prev2X_L_Actl 64;
BA_ "GenSigStartValueInteger" SG_ 1251 BalrLeft4Prev1Y_L_Actl 64;
BA_ "GenSigStartValueInteger" SG_ 1251 BalrLeft4Prev1X_L_Actl 64;
BA_ "GenSigStartValueInteger" SG_ 1251 BalrLeft4CurntY_L_Actl 64;
BA_ "GenSigStartValueInteger" SG_ 1251 BalrLeft4CurntX_L_Actl 64;
BA_ "GenSigStartValueInteger" SG_ 1250 BalrLeft3Prev3Y_L_Actl 64;
BA_ "GenSigStartValueInteger" SG_ 1250 BalrLeft3Prev3X_L_Actl 64;
BA_ "GenSigStartValueInteger" SG_ 1250 BalrLeft3Prev2Y_L_Actl 64;
BA_ "GenSigStartValueInteger" SG_ 1250 BalrLeft3Prev2X_L_Actl 64;
BA_ "GenSigStartValueInteger" SG_ 1250 BalrLeft3Prev1Y_L_Actl 64;
BA_ "GenSigStartValueInteger" SG_ 1250 BalrLeft3Prev1X_L_Actl 64;
BA_ "GenSigStartValueInteger" SG_ 1250 BalrLeft3CurntY_L_Actl 64;
BA_ "GenSigStartValueInteger" SG_ 1250 BalrLeft3CurntX_L_Actl 64;
BA_ "GenSigStartValueInteger" SG_ 1249 BalrLeft2Prev3Y_L_Actl 64;
BA_ "GenSigStartValueInteger" SG_ 1249 BalrLeft2Prev3X_L_Actl 64;
BA_ "GenSigStartValueInteger" SG_ 1249 BalrLeft2Prev2Y_L_Actl 64;
BA_ "GenSigStartValueInteger" SG_ 1249 BalrLeft2Prev2X_L_Actl 64;
BA_ "GenSigStartValueInteger" SG_ 1249 BalrLeft2Prev1Y_L_Actl 64;
BA_ "GenSigStartValueInteger" SG_ 1249 BalrLeft2Prev1X_L_Actl 64;
BA_ "GenSigStartValueInteger" SG_ 1249 BalrLeft2CurntY_L_Actl 64;
BA_ "GenSigStartValueInteger" SG_ 1249 BalrLeft2CurntX_L_Actl 64;
BA_ "GenSigSendType" SG_ 1248 BalrLeft1Threat_D_Stat 3;
BA_ "GenSigStartValueInteger" SG_ 1248 BalrLeft1Prev3Y_L_Actl 64;
BA_ "GenSigStartValueInteger" SG_ 1248 BalrLeft1Prev3X_L_Actl 64;
BA_ "GenSigStartValueInteger" SG_ 1248 BalrLeft1Prev2Y_L_Actl 64;
BA_ "GenSigStartValueInteger" SG_ 1248 BalrLeft1Prev2X_L_Actl 64;
BA_ "GenSigStartValueInteger" SG_ 1248 BalrLeft1Prev1Y_L_Actl 64;
BA_ "GenSigStartValueInteger" SG_ 1248 BalrLeft1Prev1X_L_Actl 64;
BA_ "GenSigSendType" SG_ 1248 BalrLeft1Fast_B_Stat 3;
BA_ "GenSigSendType" SG_ 1248 BalrLeft1Dsply_B_Stat 3;
BA_ "GenSigStartValueInteger" SG_ 1248 BalrLeft1CurntY_L_Actl 64;
BA_ "GenSigStartValueInteger" SG_ 1248 BalrLeft1CurntX_L_Actl 64;
BA_ "U_P702_MY2021_Rx" SG_ 1113 TrlrTrgtAcquire_D_Stat 1;
BA_ "U_P702_MY2021_Rx" SG_ 1113 TrlrRvrse_D_Stat 1;
BA_ "U_P702_MY2021_Rx" SG_ 1113 TrlrAid_D2_Stat 1;
BA_ "U_P702_MY2021_Rx" SG_ 1113 TrlrAidTrgtId_No_Actl 1;
BA_ "U_P702_MY2021_Rx" SG_ 1113 TrlrAid_An3_Actl 1;
BA_ "GenSigStartValueInteger" SG_ 1113 TrlrAid_An3_Actl 720;
BA_ "U_P702_MY2021_Rx" SG_ 1113 TrlrAid_AnRate2_Actl 1;
BA_ "GenSigStartValueInteger" SG_ 1113 TrlrAid_AnRate2_Actl 400;
BA_ "U_P702_MY2021_Rx" SG_ 1113 HitchToVehAxle_L_Calc 1;
BA_ "GenSigStartValue" SG_ 1113 HitchToVehAxle_L_Calc 255;
BA_ "GenSigStartValueInteger" SG_ 1113 HitchToVehAxle_L_Calc 255;
BA_ "GenSigSendType" SG_ 1105 CamraFrntOffRd_B_Stat 3;
BA_ "GenSigSendType" SG_ 1105 TrlrAidSwtchLamp_B_Rq 3;
BA_ "GenSigSendType" SG_ 1105 TrlrHitchMsgTxt_D_Rq 3;
BA_ "GenSigSendType" SG_ 1105 TrlrHitchIcon_D_Rq 3;
BA_ "GenSigSendType" SG_ 1105 TrlrHitchChime_D_Rq 3;
BA_ "U_P702_MY2021_Rx" SG_ 1105 TrlrAidEnbl_D_RqAdas 1;
BA_ "GenSigSendType" SG_ 1105 TrlrAidEnbl_D_RqAdas 3;
BA_ "U_P702_MY2021_Rx" SG_ 1105 TrlrRvrseMsgTxt_D2_Rq 1;
BA_ "GenSigSendType" SG_ 1105 TrlrRvrseMsgTxt_D2_Rq 3;
BA_ "U_P702_MY2021_Rx" SG_ 1105 TrlrRvrseEnbl_D2_Stat 1;
BA_ "GenSigSendType" SG_ 1105 TrlrRvrseEnbl_D2_Stat 3;
BA_ "GenSigSendType" SG_ 1105 RbaMsg_D_Rq 3;
BA_ "U_P702_MY2021_Rx" SG_ 1105 BrkDecel_B_RqRba 1;
BA_ "GenSigSendType" SG_ 1105 BrkDecel_B_RqRba 3;
BA_ "CrossOver_InfoCAN" SG_ 1105 BrkDecel_B_RqRba 1;
BA_ "WakeupSignal" SG_ 1105 BrkDecel_B_RqRba 1;
BA_ "U_P702_MY2021_Rx" SG_ 1105 BrkEnbl_B_RqRba 1;
BA_ "GenSigSendType" SG_ 1105 BrkEnbl_B_RqRba 3;
BA_ "CrossOver_InfoCAN" SG_ 1105 BrkEnbl_B_RqRba 1;
BA_ "WakeupSignal" SG_ 1105 BrkEnbl_B_RqRba 1;
BA_ "GenSigSendType" SG_ 1105 Rba_D_Stat 3;
BA_ "GenSigStartValue" SG_ 1105 Rba_D_Stat 1;
BA_ "GenSigStartValueInteger" SG_ 1105 Rba_D_Stat 1;
BA_ "GenSigSendType" SG_ 1105 RbaAlrt_D_Dsply 3;
BA_ "GenSigSendType" SG_ 1105 RbaMnu_D_Rq 3;
BA_ "GenSigSendType" SG_ 1105 CamraFrntStat_D_Stat 3;
BA_ "GenSigSendType" SG_ 1105 TrlrHitchLamp_D_Rq2 3;
BA_ "GenSigSendType" SG_ 938 SidePrkSnsR2_D_Stat 3;
BA_ "GenSigSendType" SG_ 938 SidePrkSnsR1_D_Stat 3;
BA_ "GenSigSendType" SG_ 938 SidePrkSnsL2_D_Stat 3;
BA_ "GenSigSendType" SG_ 938 ApaMde_D_Stat 3;
BA_ "CrossOver_InfoCAN" SG_ 938 ApaMde_D_Stat 1;
BA_ "GenSigSendType" SG_ 938 ApaActvSd_D_Actl 3;
BA_ "GenSigStartValue" SG_ 938 ApaActvSd_D_Actl 1;
BA_ "GenSigStartValueInteger" SG_ 938 ApaActvSd_D_Actl 1;
BA_ "CrossOver_InfoCAN" SG_ 938 ApaActvSd_D_Actl 1;
BA_ "GenSigSendType" SG_ 938 PrkAidSwtch_B_Stat 3;
BA_ "CrossOver_InfoCAN" SG_ 938 PrkAidSwtch_B_Stat 1;
BA_ "GenSigSendType" SG_ 938 ApaMde_D_Avail 3;
BA_ "CrossOver_InfoCAN" SG_ 938 ApaMde_D_Avail 1;
BA_ "GenSigSendType" SG_ 938 PrkAidSnsFrCrnr_D_Stat 3;
BA_ "CrossOver_InfoCAN" SG_ 938 PrkAidSnsFrCrnr_D_Stat 1;
BA_ "GenSigSendType" SG_ 938 PrkAidSnsFrCntr_D_Stat 3;
BA_ "CrossOver_InfoCAN" SG_ 938 PrkAidSnsFrCntr_D_Stat 1;
BA_ "GenSigSendType" SG_ 938 PrkAidSnsFlCrnr_D_Stat 3;
BA_ "CrossOver_InfoCAN" SG_ 938 PrkAidSnsFlCrnr_D_Stat 1;
BA_ "GenSigSendType" SG_ 938 PrkAidSnsFlCntr_D_Stat 3;
BA_ "CrossOver_InfoCAN" SG_ 938 PrkAidSnsFlCntr_D_Stat 1;
BA_ "U_P702_MY2021_Rx" SG_ 938 PrkBrkEl_B_RqFap 1;
BA_ "U_CX727_MY2021_Rx" SG_ 938 PrkBrkEl_B_RqFap 1;
BA_ "GenSigSendType" SG_ 938 PrkBrkEl_B_RqFap 3;
BA_ "GenSigSendType" SG_ 938 RpaChime_D_Rq 3;
BA_ "CrossOver_InfoCAN" SG_ 938 RpaChime_D_Rq 1;
BA_ "GenSigSendType" SG_ 938 FpaChime_D_Rq 3;
BA_ "CrossOver_InfoCAN" SG_ 938 FpaChime_D_Rq 1;
BA_ "U_P702_MY2021_Rx" SG_ 938 PrkAidMsgTxt_D_Rq 1;
BA_ "GenSigSendType" SG_ 938 PrkAidMsgTxt_D_Rq 3;
BA_ "CrossOver_InfoCAN" SG_ 938 PrkAidMsgTxt_D_Rq 1;
BA_ "GenSigSendType" SG_ 938 SidePrkSnsL1_D_Stat 3;
BA_ "GenSigSendType" SG_ 938 PrkAidAudioMute_B_Rq 3;
BA_ "CrossOver_InfoCAN" SG_ 938 PrkAidAudioMute_B_Rq 1;
BA_ "GenSigSendType" SG_ 939 ApaBrk_D_Rq 3;
BA_ "GenSigSendType" SG_ 939 SidePrkSnsR4_D_Stat 3;
BA_ "GenSigSendType" SG_ 939 SidePrkSnsR3_D_Stat 3;
BA_ "GenSigSendType" SG_ 939 SidePrkSnsL4_D_Stat 3;
BA_ "GenSigSendType" SG_ 939 SidePrkSnsL3_D_Stat 3;
BA_ "GenSigSendType" SG_ 939 PrkAidChime_D_Stat 3;
BA_ "CrossOver_InfoCAN" SG_ 939 PrkAidChime_D_Stat 1;
BA_ "GenSigSendType" SG_ 939 PrkAidSnsRlCntr_D_Stat 3;
BA_ "CrossOver_InfoCAN" SG_ 939 PrkAidSnsRlCntr_D_Stat 1;
BA_ "GenSigSendType" SG_ 939 PrkAidSnsRrCrnr_D_Stat 3;
BA_ "CrossOver_InfoCAN" SG_ 939 PrkAidSnsRrCrnr_D_Stat 1;
BA_ "GenSigSendType" SG_ 939 PrkAidSnsRrCntr_D_Stat 3;
BA_ "CrossOver_InfoCAN" SG_ 939 PrkAidSnsRrCntr_D_Stat 1;
BA_ "GenSigSendType" SG_ 939 PrkAidSnsRlCrnr_D_Stat 3;
BA_ "CrossOver_InfoCAN" SG_ 939 PrkAidSnsRlCrnr_D_Stat 1;
BA_ "GenSigSendType" SG_ 939 PrkAidRear_D_Stat 3;
BA_ "CrossOver_InfoCAN" SG_ 939 PrkAidRear_D_Stat 1;
BA_ "GenSigSendType" SG_ 939 PrkAidFront_D_Stat 3;
BA_ "CrossOver_InfoCAN" SG_ 939 PrkAidFront_D_Stat 1;
BA_ "GenSigSendType" SG_ 939 PrkAid_D_Falt 3;
BA_ "CrossOver_InfoCAN" SG_ 939 PrkAid_D_Falt 1;
BA_ "U_CX727_MY2021_Rx" SG_ 939 ApaLongCtrlEnbl_D_Rq 1;
BA_ "U_T6_MCA_MY2020_Rx" SG_ 939 ApaLongCtrlEnbl_D_Rq 1;
BA_ "U_P702_MY2021_Rx" SG_ 939 ApaLongCtrlEnbl_D_Rq 1;
BA_ "GenSigSendType" SG_ 939 ApaLongCtrlEnbl_D_Rq 3;
BA_ "U_CX727_MY2021_Rx" SG_ 939 ApaBrk_A_Rq 1;
BA_ "U_T6_MCA_MY2020_Rx" SG_ 939 ApaBrk_A_Rq 1;
BA_ "U_P702_MY2021_Rx" SG_ 939 ApaBrk_A_Rq 1;
BA_ "GenSigStartValueInteger" SG_ 939 ApaBrk_A_Rq 255;
BA_ "GenSigSendType" SG_ 939 PrkAidLamp_D_Rq 3;
BA_ "U_T6_MCA_MY2020_Rx" SG_ 937 Veh_V_RqFap 1;
BA_ "U_P702_MY2021_Rx" SG_ 937 Veh_V_RqFap 1;
BA_ "U_T6_MCA_MY2020_Rx" SG_ 937 TrnRngDRqFap_No_Cs 1;
BA_ "U_P702_MY2021_Rx" SG_ 937 TrnRngDRqFap_No_Cs 1;
BA_ "MetaData" SG_ 937 TrnRngDRqFap_No_Cs 1;
BA_ "U_T6_MCA_MY2020_Rx" SG_ 937 TrnRngDRqFap_No_Cnt 1;
BA_ "U_P702_MY2021_Rx" SG_ 937 TrnRngDRqFap_No_Cnt 1;
BA_ "MetaData" SG_ 937 TrnRngDRqFap_No_Cnt 1;
BA_ "U_T6_MCA_MY2020_Rx" SG_ 937 TrnRng_D_RqFap 1;
BA_ "U_P702_MY2021_Rx" SG_ 937 TrnRng_D_RqFap 1;
BA_ "U_T6_MCA_MY2020_Rx" SG_ 937 FapLcDistToObj_L_Actl 1;
BA_ "U_P702_MY2021_Rx" SG_ 937 FapLcDistToObj_L_Actl 1;
BA_ "GenSigStartValue" SG_ 937 FapLcDistToObj_L_Actl 254;
BA_ "GenSigStartValueInteger" SG_ 937 FapLcDistToObj_L_Actl 254;
BA_ "U_T6_MCA_MY2020_Rx" SG_ 936 ApaSys_D_Stat 1;
BA_ "U_P702_MY2021_Rx" SG_ 936 ApaSys_D_Stat 1;
BA_ "U_P702_MY2021_Rx" SG_ 936 EPASExtAngleStatReq 1;
BA_ "U_CX727_MY2021_Rx" SG_ 936 EPASExtAngleStatReq 1;
BA_ "U_P702_MY2021_Rx" SG_ 936 ExtSteeringAngleReq2 1;
BA_ "U_CX727_MY2021_Rx" SG_ 936 ExtSteeringAngleReq2 1;
BA_ "U_P702_MY2021_Tx" SG_ 877 RngImpctDrv_L_Dsply 1;
BA_ "GenSigStartValueInteger" SG_ 877 RngImpctDrv_L_Dsply 255;
BA_ "U_P702_MY2021_Tx" SG_ 877 RngImpctClim_L_Dsply 1;
BA_ "GenSigStartValueInteger" SG_ 877 RngImpctClim_L_Dsply 255;
BA_ "U_P702_MY2021_Tx" SG_ 877 VehElEffAvg_No_Dsply 1;
BA_ "GenSigStartValue" SG_ 877 VehElEffAvg_No_Dsply 126;
BA_ "GenSigStartValueInteger" SG_ 877 VehElEffAvg_No_Dsply 126;
BA_ "U_P702_MY2021_Tx" SG_ 877 PwFlwFuelDrv_D_Dsply 1;
BA_ "GenSigSendType" SG_ 877 PwFlwFuelDrv_D_Dsply 3;
BA_ "CrossOver_InfoCAN" SG_ 877 PwFlwFuelDrv_D_Dsply 1;
BA_ "U_P702_MY2021_Tx" SG_ 877 PwFlwFuelClimt_B_Dsply 1;
BA_ "GenSigSendType" SG_ 877 PwFlwFuelClimt_B_Dsply 3;
BA_ "CrossOver_InfoCAN" SG_ 877 PwFlwFuelClimt_B_Dsply 1;
BA_ "U_P702_MY2021_Tx" SG_ 877 PwFlwFuelBatt_B_Dsply 1;
BA_ "GenSigSendType" SG_ 877 PwFlwFuelBatt_B_Dsply 3;
BA_ "CrossOver_InfoCAN" SG_ 877 PwFlwFuelBatt_B_Dsply 1;
BA_ "U_P702_MY2021_Tx" SG_ 877 PwFlwBattClimt_B_Dsply 1;
BA_ "GenSigSendType" SG_ 877 PwFlwBattClimt_B_Dsply 3;
BA_ "CrossOver_InfoCAN" SG_ 877 PwFlwBattClimt_B_Dsply 1;
BA_ "U_P702_MY2021_Tx" SG_ 877 PwFlwBatt_D_Dsply 1;
BA_ "GenSigSendType" SG_ 877 PwFlwBatt_D_Dsply 3;
BA_ "CrossOver_InfoCAN" SG_ 877 PwFlwBatt_D_Dsply 1;
BA_ "U_P702_MY2021_Rx" SG_ 589 BattTrac2_Pw_LimChrg 1;
BA_ "U_P702_MY2021_Rx" SG_ 589 BattTrac2_Pw_LimDchrg 1;
BA_ "U_P702_MY2021_Rx" SG_ 589 BattTrac2_Pw_DchrgInst 1;
BA_ "U_P702_MY2021_Rx" SG_ 589 BattTrac2_Pw_ChrgInst 1;
BA_ "U_P702_MY2021_Rx" SG_ 588 BattTracSoc2_Pc_Actl 1;
BA_ "GenSigStartValue" SG_ 588 BattTracSoc2_Pc_Actl 16382;
BA_ "GenSigStartValueInteger" SG_ 588 BattTracSoc2_Pc_Actl 16382;
BA_ "U_P702_MY2021_Rx" SG_ 588 BattTrac_Te_Actl 1;
BA_ "GenSigStartValue" SG_ 588 BattTrac_Te_Actl 150;
BA_ "GenSigStartValueInteger" SG_ 588 BattTrac_Te_Actl 150;
BA_ "GenSigStartValue" SG_ 587 BattTracClnt_Te_Actl 164;
BA_ "GenSigStartValueInteger" SG_ 587 BattTracClnt_Te_Actl 164;
BA_ "CrossOver_InfoCAN" SG_ 587 BattTracWarnLamp_B_Rq 1;
BA_ "CrossOver_InfoCAN" SG_ 587 BattTracSrvcRqd_B_Rq 1;
BA_ "U_P702_MY2021_Rx" SG_ 587 BattTracSoc_Pc_MxPrtct 1;
BA_ "GenSigStartValue" SG_ 587 BattTracSoc_Pc_MxPrtct 700;
BA_ "GenSigStartValueInteger" SG_ 587 BattTracSoc_Pc_MxPrtct 700;
BA_ "U_P702_MY2021_Rx" SG_ 587 BattTracSoc_Pc_MnPrtct 1;
BA_ "GenSigStartValue" SG_ 587 BattTracSoc_Pc_MnPrtct 30;
BA_ "GenSigStartValueInteger" SG_ 587 BattTracSoc_Pc_MnPrtct 300;
BA_ "U_P702_MY2021_Rx" SG_ 587 BattTracSoc_Pc_LimLo 1;
BA_ "GenSigStartValue" SG_ 587 BattTracSoc_Pc_LimLo 400;
BA_ "GenSigStartValueInteger" SG_ 587 BattTracSoc_Pc_LimLo 400;
BA_ "U_P702_MY2021_Rx" SG_ 587 BattTracSoc_Pc_LimHi 1;
BA_ "GenSigStartValue" SG_ 587 BattTracSoc_Pc_LimHi 600;
BA_ "GenSigStartValueInteger" SG_ 587 BattTracSoc_Pc_LimHi 600;
BA_ "CrossOver_InfoCAN" SG_ 389 HtrnOvrTeLamp_B_Dsply 1;
BA_ "ECGUsedRxSignal" SG_ 389 HtrnAin_UHi_Actl 1;
BA_ "U_P702_MY2021_Rx" SG_ 389 HtrnAin_UHi_Actl 1;
BA_ "CrossOver_InfoCAN" SG_ 389 HtrnSrvcRqd_B_Dsply 1;
BA_ "ECGUsedRxSignal" SG_ 389 HtrnHvilOpen_B_Actl 1;
BA_ "U_P702_MY2021_Rx" SG_ 389 HtrnHvilOpen_B_Actl 1;
BA_ "GenSigStartValueInteger" SG_ 389 BattTrac_I_EstVsc 15000;
BA_ "U_P702_MY2021_Rx" SG_ 1009 TrlrAidCancl_B_Rq 1;
BA_ "GenSigStartValue" SG_ 1009 CenterStackRing_D_Actl 2;
BA_ "GenSigStartValueInteger" SG_ 1009 CenterStackRing_D_Actl 2;
BA_ "CrossOver_InfoCAN" SG_ 1009 ValetMode_D_Stat 1;
BA_ "ContentDependant" SG_ 360 GsmSrvcRqd_B_Rq 1;
BA_ "CrossOver_InfoCAN" SG_ 360 GsmSrvcRqd_B_Rq 1;
BA_ "U_T6_MCA_MY2020_Rx" SG_ 360 TrnGearPwmFalt_B_Actl 1;
BA_ "U_P702_MY2021_Rx" SG_ 360 TrnGearPwmFalt_B_Actl 1;
BA_ "ContentDependant" SG_ 360 TrnGearPwmFalt_B_Actl 1;
BA_ "CrossOver_InfoCAN" SG_ 360 TrnGearPwmFalt_B_Actl 1;
BA_ "U_T6_MCA_MY2020_Rx" SG_ 360 GearButtnStuck_B_Actl 1;
BA_ "U_P702_MY2021_Rx" SG_ 360 GearButtnStuck_B_Actl 1;
BA_ "ContentDependant" SG_ 360 GearButtnStuck_B_Actl 1;
BA_ "CrossOver_InfoCAN" SG_ 360 GearButtnStuck_B_Actl 1;
BA_ "U_P702_MY2021_Rx" SG_ 122 BattTrac_U_LimLo 1;
BA_ "GenSigStartValue" SG_ 122 BattTrac_U_LimLo 88;
BA_ "GenSigStartValueInteger" SG_ 122 BattTrac_U_LimLo 88;
BA_ "U_P702_MY2021_Rx" SG_ 122 BattTrac_U_LimHi 1;
BA_ "GenSigStartValue" SG_ 122 BattTrac_U_LimHi 163;
BA_ "GenSigStartValueInteger" SG_ 122 BattTrac_U_LimHi 163;
BA_ "U_P702_MY2021_Rx" SG_ 122 VehStrtInhbt_B_RqBatt 1;
BA_ "CrossOver_InfoCAN" SG_ 122 VehStrtInhbt_B_RqBatt 1;
BA_ "U_P702_MY2021_Rx" SG_ 122 BattTracOffFst_D_Actl 1;
BA_ "U_P702_MY2021_Rx" SG_ 122 BattTracOff_B_Actl 1;
BA_ "CrossOver_InfoCAN" SG_ 122 BattTracOff_B_Actl 1;
BA_ "U_P702_MY2021_Rx" SG_ 122 BattTrac_U_Actl 1;
BA_ "GenSigStartValue" SG_ 122 BattTrac_U_Actl 1022;
BA_ "GenSigStartValueInteger" SG_ 122 BattTrac_U_Actl 1022;
BA_ "U_P702_MY2021_Rx" SG_ 122 BattTrac_I_Actl 1;
BA_ "GenSigStartValueInteger" SG_ 122 BattTrac_I_Actl 15000;
VAL_ 1098 AirDamPos_D_Stat 3 "Faulty" 2 "NotUsed" 1 "Down" 0 "Up" ;
VAL_ 1098 EdmSailMdeOn_B_Stat 1 "On" 0 "Off" ;
VAL_ 1098 EdmMsgTxt_D_Rq 15 "NotUsed_4" 14 "NotUsed_3" 13 "NotUsed_2" 12 "NotUsed_1" 11 "OverallGoodScore" 10 "WorkOnCompliance" 9 "GoodCompliance" 8 "WorkOnGearShifting" 7 "GoodGearShifting" 6 "WorkOnEfficientSpeed" 5 "GoodEfficientSpeed" 4 "WorkOnDeceleration" 3 "GoodDeceleration" 2 "WorkOnAcceleration" 1 "GoodAcceleration" 0 "NoMessage" ;
VAL_ 1098 EdmLamp_D_Dsply 15 "NotUsed_7" 14 "NotUsed_6" 13 "NotUsed_5" 12 "NotUsed_4" 11 "NotUsed_3" 10 "NotUsed_2" 9 "NotUsed_1" 8 "CoastingEngineBrake" 7 "CoastingShiftToNeutral" 6 "FreewayJunction" 5 "Curve2" 4 "Curve1" 3 "SpeedLimit" 2 "Crossing" 1 "FreewayExit" 0 "NoRecommendation" ;
VAL_ 1098 EdmCmplnc_B_Dsply 1 "Yes" 0 "No" ;
VAL_ 1086 FuelPumpPwr_B_Rq 1 "On" 0 "Off" ;
VAL_ 1086 ElLoadCtl_D_Rq 7 "Unused3" 6 "Unused2" 5 "Unused1" 4 "HoldAllDrvrInvisibleLoads" 3 "StdDriverInvisibleLoadsOn" 2 "AllDriverInvisibleLoadsOn" 1 "All_Possible_Loads_Off" 0 "No_Request" ;
VAL_ 1071 CluPdlPosPcMeas_D_Qf 3 "OK" 2 "Not_Within_Specifications" 1 "No_Data_Exists" 0 "Faulty" ;
VAL_ 1069 ReFuelSysStat_D_Dsply 7 "NotUsed3" 6 "NotUsed2" 5 "NotUsed1" 4 "Refuel_Err" 3 "Close_Fuel_Door" 2 "Refuel_Ready" 1 "Wait_To_Fuel" 0 "Null" ;
VAL_ 1069 SlMde_D_Stat 3 "IsaNotConfigured" 2 "Manual_Mode" 1 "Auto_Mode" 0 "Null" ;
VAL_ 1069 SlMde_D_RqDsply 3 "NotUsed" 2 "ManualSpeed_LimiterSymbol" 1 "AutoSpeed_LimiterSymbol" 0 "NoSpeed_LimiterSymbol" ;
VAL_ 1069 IsaOffst_D_Stat 15 "Faulty" 14 "Null" 13 "Thirteen" 12 "Twelve" 11 "Eleven" 10 "Ten" 9 "Nine" 8 "Eight" 7 "Seven" 6 "Six" 5 "Five" 4 "Four" 3 "Three" 2 "Two" 1 "One" 0 "Zero" ;
VAL_ 1069 GrllShtrPos_D_Cmd 15 "Fully_Open" 14 "Position14" 13 "Position13" 12 "Position12" 11 "Position11" 10 "Position10" 9 "Position9" 8 "Position8" 7 "Position7" 6 "Position6" 5 "Position5" 4 "Position4" 3 "Position3" 2 "Position2" 1 "Position1" 0 "Fully_Closed" ;
VAL_ 1069 GrllShtrPos_B_Falt 1 "Fault" 0 "No_Fault" ;
VAL_ 1069 ObdWarmUp_B_Complt 1 "Yes" 0 "No" ;
VAL_ 1069 EngMsgTxt_D_Rq 3 "Undefined_2" 2 "Undefined_1" 1 "Power_Reduced_to_LowerTemp" 0 "No_Message" ;
VAL_ 1069 EngAirIn_Te_Actl 1023 "Fault" 1022 "Unknown" ;
VAL_ 1060 RearDiffOilTeWarn_B_Rq 1 "On" 0 "Off" ;
VAL_ 1060 RearDiffOil_Te_Actl 511 "Faulty" ;
VAL_ 1060 BpedDrvMsgTxt_B_Dsply 1 "On" 0 "Off" ;
VAL_ 1060 FuelLvlWarn_D_ActlEng 7 "DteLevel5Lowest" 6 "DteLevel4" 5 "DteLevel3" 4 "DteLevel2NonMyKey" 3 "DteLevel1MyKey" 2 "VeryLow" 1 "Low" 0 "OK" ;
VAL_ 1060 SelDrvMdePt_D_Stat 0 "NotAvailable" 1 "Available" 2 "TemporarilyNotAvailable" 3 "Faulty" ;
VAL_ 1057 FohEng_D_Rq 3 "AutoEnable_ParkEnable" 2 "AutoDisable_ParkEnable" 1 "AutoEnable_ParkDisable" 0 "Disable_Stop" ;
VAL_ 1057 EngIdlShutDwnTxt_D_Rq 3 "NotUsed" 2 "EngineShutdownOnPrevDrive" 1 "FeatureDisabledDueToFault" 0 "NoMessage" ;
VAL_ 1057 EngIdlShutDown_D_Stat 3 "Not_used" 2 "Engine_Shutdown" 1 "Initiated_Countdown" 0 "Normal_Operation" ;
VAL_ 1057 FUEL_ALCOHOL_PERCNT 255 "Invalid" ;
VAL_ 1057 TrnTotTq_Rt_Est 65535 "Fault" 65534 "Unknown" ;
VAL_ 1057 TrnTotLss_Tq_Est 255 "Fault" 254 "Unknown" ;
VAL_ 1057 ECMMILRequest 3 "Not_Used" 2 "Flash" 1 "On" 0 "Off" ;
VAL_ 1057 AirCondFluidHi_P_Actl 255 "Fault" 254 "Unknown" ;
VAL_ 1057 OilPressureWarning 1 "Low_Pressure_Lamp_On" 0 "Normal_Pressure_Lamp_Off" ;
VAL_ 1057 VehVLimStat_D_Actl 7 "Undefined_3" 6 "Undefined_2" 5 "Undefined_1" 4 "ASL_Fault_Condition" 3 "Active_and_Limiting" 2 "Active_but_Not_Limiting" 1 "Standby" 0 "Off" ;
VAL_ 1057 VehVLimActv_B_Actl 1 "Active" 0 "Inactive" ;
VAL_ 1057 CoolantFanStepAct 31 "Unused7" 30 "Unused6" 29 "Unused5" 28 "Unused4" 27 "Unused3" 26 "Unused2" 25 "Unused1" 23 "Step23" 22 "Step22" 21 "Step21" 20 "Step20" 19 "Step19" 18 "Step18" 17 "Step17" 16 "Step16" 15 "Step15" 14 "Step14" 13 "Step13" 12 "Step12" 11 "Step11" 10 "Step10" 9 "Step9" 8 "Step8" 7 "Step7" 6 "Step6" 5 "Step5" 4 "Step4" 3 "Step3" 2 "Step2" 1 "Step1" 24 "Max_Fan_Speed_Req" 0 "Fan_Cmd_Off" ;
VAL_ 1055 EcoCochInstNeg_B_Dsply 1 "True" 0 "False" ;
VAL_ 562 GearNtrl_D_Stat 3 "Faulty" 2 "NoDataExists" 1 "Yes" 0 "No" ;
VAL_ 523 EngAirFiltMsgTxt_D_Rq 7 "NotUsed_2" 6 "NotUsed_1" 5 "EngineAirFilterMonitorFalt" 4 "ResetComplete" 3 "Clogged" 2 "ReplaceNow" 1 "ReplaceSoon" 0 "NoMessage" ;
VAL_ 523 WaterInFuel_B_Falt 1 "Fault" 0 "No_Fault" ;
VAL_ 523 UreaMnAdd_L2_Actl 255 "Faulty" ;
VAL_ 523 UreaMxAdd_L2_Actl 511 "Faulty" ;
VAL_ 517 FapLc_B_Err 1 "Yes" 0 "No" ;
VAL_ 516 EngAoutNActl_D_QF 3 "OK" 2 "Not_Within_Specifications" 1 "No_Data_Exists" 0 "Faulty" ;
VAL_ 516 EngAout3_N_Actl 65535 "Invalid" ;
VAL_ 516 ApedPos_PcRate_ActlArb 255 "Fault" 254 "Unknown" ;
VAL_ 516 ApedPosPcActl_D_Qf 3 "OK" 2 "Not_Within_Specifications" 1 "No_Data_Exists" 0 "Faulty" ;
VAL_ 514 StrtrMtrDlyStrt_B_Stat 1 "Yes" 0 "No" ;
VAL_ 514 VehVTrlrAid_B_Avail 1 "Yes" 0 "No" ;
VAL_ 514 StrtrMtrCtlMsgTxt_D_Rq 7 "Start_In_Gear_Allowed" 6 "Pending_Start_Cancelled" 5 "Start_Pending_Please_Wait" 4 "Cranking_Limit_Exceeded" 3 "Press_Brk_and_Shift_to_P_N" 2 "Press_Clutch_and_Brake" 1 "Press_Clutch_To_Start" 0 "No_Display" ;
VAL_ 514 VehVActlEng_D_Qf 3 "OK" 2 "Not_Within_Specifications" 1 "No_Data_Exists" 0 "Faulty" ;
VAL_ 514 GearRvrse_D_Actl 7 "Fault" 6 "NotUsed_3" 5 "NotUsed_2" 4 "NotUsed_1" 3 "Active_confirmed" 2 "Active_not_confirmed" 1 "Inactive_confirmed" 0 "Inactive_not_confirmed" ;
VAL_ 514 StrtrMtrCtlMsgTxt_D2_Rq 3 "NoRequestPcmStartingMsgCtl" 2 "ShiftToNeutralToStart" 1 "ShiftToParkToStart" 0 "NoRequestBcmStartingMsgCtl" ;
VAL_ 512 PtDrvMde_D_Stat 15 "Faulty" 14 "NotUsed11" 13 "NotUsed10" 12 "NotUsed9" 11 "NotUsed8" 10 "NotUsed7" 9 "NotUsed6" 8 "NotUsed5" 7 "Drag" 6 "Rock" 5 "Baja" 4 "Sand" 3 "TowHaulGradeAssist" 2 "SnowWet" 1 "Sport" 0 "Normal" ;
VAL_ 381 EngOilSrvcMsgTxt_D_Rq 7 "NotUsed3" 6 "NotUsed2" 5 "NotUsed1" 4 "ResetComplete" 3 "ResetInProgress" 2 "ChangeOilNow" 1 "ChangeOilSoon" 0 "NoText" ;
VAL_ 381 RunDryPrevent_B_Stat 1 "True" 0 "False" ;
VAL_ 381 WaterInFuel 1 "On" 0 "Off" ;
VAL_ 381 GlowIndication 1 "On" 0 "Off" ;
VAL_ 380 EngOilLvlWarn_D_Rq1 7 "Undefined_3" 6 "Undefined_2" 5 "Engine_Oil_Monitor_Fault" 3 "Engine_Oil_High" 2 "Engine_Oil_Critical_Low" 1 "Engine_Oil_Low" 0 "No_Message" 4 "Engine_Oil_Critical_High" ;
VAL_ 380 EngExhBrkOnLamp_B_Rq 1 "On" 0 "Off" ;
VAL_ 380 EngExhBrkAutoLamp_B_Rq 1 "On" 0 "Off" ;
VAL_ 380 EngExhBrkMde_D_Actl 6 "ExhBrkDisable_NoError" 5 "ExhBrkActive_AUTO" 4 "ExhBrkActive_ON" 3 "ExhBrkRequest_AUTO" 2 "ExhBrkRequest_ON" 1 "ExhBrkNoRequest_OFF" 0 "ExhBrkUnavailable_Error" ;
VAL_ 377 HvacAirFullOut_B_Rq 1 "Yes" 0 "No" ;
VAL_ 377 FuelFillInlet_B_Dsply 1 "Yes" 0 "No" ;
VAL_ 377 EngSrvcRqd_B_Rq 1 "Engine_Service_Required" 0 "No_engine_service_required" ;
VAL_ 377 OdoCount 255 "Invalid" ;
VAL_ 377 FuelFilterLamp_B_Dsply 1 "On" 0 "Off" ;
VAL_ 377 AirCondRec_B_Rq 1 "Yes" 0 "No" ;
VAL_ 377 AirCondClutch_B_Stats 1 "Yes" 0 "No" ;
VAL_ 376 GasPrtc_D_RqDsply 7 "NotUsed_5" 6 "NotUsed_4" 5 "NotUsed_3" 4 "NotUsed_2" 3 "NotUsed_1" 2 "GpfOverLimit" 1 "GpfAtLimit" 0 "NormalOperation" ;
VAL_ 376 DynoMde_B_Cmd 1 "Two_Wheel_Dyno" 0 "Normal_Operation" ;
VAL_ 376 AslIconDsply_D_Rq 3 "On_Passive_Overridden" 2 "On_Active" 1 "On_Passive" 0 "Off" ;
VAL_ 376 AslChime_B_Rq 1 "Yes" 0 "No" ;
VAL_ 376 HvacHtrCore2_Te_Actl 1023 "Faulty" ;
VAL_ 376 EcssLamp_D_RqDsply 3 "Not_Used" 2 "Flash" 1 "On" 0 "Off" ;
VAL_ 376 AirAmbTe_D_Qf 3 "OK" 2 "Not_Within_Specifications" 1 "No_Data_Exists" 0 "Faulty" ;
VAL_ 376 AirAmb_P_Actl 63 "Fault" 62 "NoDataExists" ;
VAL_ 373 DieslPrtc2_D_RqDsply 15 "NotUsed4" 14 "NotUsed3" 13 "NotUsed2" 12 "NotUsed1" 11 "OCR_ExhFilterClean_Stopped" 10 "OCR_ExhFilterCleaned" 9 "RgnOff_AtLimit" 8 "RgnOff_Overloaded" 7 "RgnOff_Loaded" 6 "Exhaust_Filter_Full" 5 "DPF_Overlimit" 4 "DPF_AtLimit" 3 "ExhFilter_Drive_Completed" 2 "Cleaning_Exhaust_Filter" 1 "DPF_Overloaded" 0 "DPF_Normal_Operation" ;
VAL_ 373 DieslPrtcRgen_D_Actl 3 "Undefined" 2 "Regen_Level_2" 1 "Regen_Level_1" 0 "No_regen" ;
VAL_ 373 EngTeColdPrtct_D_Stats 3 "Engine_Warm_RdcPwr" 2 "OK_to_Drive" 1 "Engine_Warm_PlsWait" 0 "Normal_Operation" ;
VAL_ 373 EngExhOvrTe_B_RqDsply 1 "Active" 0 "Inactive" ;
VAL_ 359 PrplWhlRgenMn_Tq_Actl 8191 "Faulty" ;
VAL_ 359 ElPw_D_StatStrtStop 15 "NotUsed6" 14 "NotUsed5" 13 "NotUsed4" 12 "NotUsed3" 11 "NotUsed2" 10 "NotUsed1" 9 "Supported_Level_4" 8 "Supported_Level_3" 7 "Supported_Level_2" 6 "Supported_Level_1" 5 "Limited_Support" 4 "Fault_Limited" 3 "LV_Event_in_Progress" 2 "Not_Supported_Imminent" 1 "Supported_All" 0 "Not_Supported" ;
VAL_ 359 PrplWhlTot2_Tq_Actl 65535 "Fault" 65534 "NoDataExists" ;
VAL_ 359 PwPckTq_D_Stat 3 "PwPckOn_TqAvailable" 2 "StartInPrgrss_TqNotAvail" 1 "PwPckOn_TqNotAvailable" 0 "PwPckOff_TqNotAvailable" ;
VAL_ 359 Eng_D_Stat 3 "NotUsed" 2 "EngAutoStopped" 1 "EngOn" 0 "EngOff" ;
VAL_ 359 PlgActvArb_B_Actl 1 "On" 0 "Off" ;
VAL_ 359 ElPw_D_Stat 7 "NotUsed_3" 6 "NotUsed_2" 5 "NotUsed_1" 4 "Fault_Limited" 3 "LV_Event_In_Progress" 2 "Not_Supported_Imminent" 1 "Supported" 0 "Not_Supported" ;
VAL_ 359 TrnAinTq_D_Qf 3 "OK" 2 "Not_Within_Specifications" 1 "No_Data_Exists" 0 "Faulty" ;
VAL_ 358 StopStrtStdby_D_Indic 6 "NotUsed2" 5 "Telltale_Struck_Out" 4 "Telltale_Flashing_Amber" 3 "Telltale_On_Amber" 2 "Telltale_Flashing_Green" 1 "Telltale_On_Green" 0 "Telltale_Off" 7 "NotUsed3" ;
VAL_ 358 StopStrtIODTxt_D_Rq 31 "Message31" 30 "Message30" 29 "Message29" 28 "Message28" 27 "Message27" 26 "Message26" 25 "Message25" 24 "Message24" 23 "Message23" 22 "Message22" 21 "Message21" 20 "Message20" 19 "Message19" 18 "Message18" 17 "Message17" 16 "Message16" 15 "Message15" 14 "Message14" 13 "Message13" 12 "Message12" 11 "Message11" 10 "Message10" 9 "Message9" 8 "Message8" 7 "Message7" 6 "Message6" 5 "Message5" 4 "Message4" 3 "Message3" 2 "Message2" 1 "Message1" 0 "NoMessage" ;
VAL_ 358 StopStrtDrvMde_D_Indic 3 "NotUsed" 2 "StartStop_IndirectDeselect" 1 "StopStart_Deselected" 0 "StopStart_Selected" ;
VAL_ 358 StopStrtMsgTxt_D_Rq 15 "Message_15" 14 "Message_14" 13 "Message_13" 12 "Message_12" 11 "Message_11" 10 "Message_10" 9 "Message_9" 8 "Message_8" 7 "Message_7" 6 "Message_6" 5 "Message_5" 4 "Message_4" 3 "Message_3" 2 "Message_2" 1 "Message_1" 0 "NoMessage" ;
VAL_ 358 OdoTripVerify_L_Actl 16777215 "Fault" ;
VAL_ 358 HiElPwInhbt_B_Stat 1 "Inhibit" 0 "No_Inibit" ;
VAL_ 358 AutoStopPtDelta_I_Est 255 "Fault" ;
VAL_ 357 BPedDrvAppl_D_QF 3 "OK" 2 "Not_Within_Specifications" 1 "No_Data_Exists" 0 "Faulty" ;
VAL_ 357 CmbbDeny_B_ActlPrpl 1 "Yes" 0 "No" ;
VAL_ 357 PrplTqMnSat_B_Actl 1 "Yes" 0 "No" ;
VAL_ 357 BpedDrvAppl_D_Actl 3 "_Not_Allowed" 2 "Driver_Braking" 1 "Driver_Not_Braking" 0 "Not_Allowed" ;
VAL_ 357 CmbbEngTqMn_B_Actl 1 "Yes" 0 "No" ;
VAL_ 357 Veh_V_DsplyCcSet 255 "Fault" 254 "Unknown" ;
VAL_ 357 AccEngStat_D_Actl 7 "Undefined_2" 6 "Undefined_1" 5 "ACCSoonCancel_due_Low_Spd" 4 "Shift_Down_Recommendation" 3 "Shift_Up_Recommendation" 2 "ACCNotAllowedToBeActivated" 1 "ACCStandby_due_Auto_Cancel" 0 "Normal_Operation" ;
VAL_ 357 CcMde_D_Actl 7 "TapDownWaiting" 6 "TapUpWaiting" 5 "Resuming_Low" 4 "Resuming_High" 3 "Decelerating" 2 "Accelerating" 1 "Keeping_Speed" 0 "Not_Active" ;
VAL_ 357 CcStat_D_Actl 7 "Undefined_2" 6 "Undefined_1" 5 "Active" 4 "Active_Que_Assist" 3 "Standby" 2 "Standby_Denied" 1 "Denied" 0 "Off" ;
VAL_ 357 CcOvrrdActv_B_Actl 1 "Cruise_Overridden" 0 "Cruise_Req_Not_Overridden" ;
VAL_ 357 AccStopMde_D_Rq 3 "Stop_Mode_Active" 2 "EPBApplyOrBrakeReleaseWarn" 1 "Limit_Rolling_Speed" 0 "Stop_Mode_Not_Active" ;
VAL_ 355 AutoRgenTxt_B_RqDsply 1 "AutExhFilterCleanOFF" 0 "AutExhFilterCleanON" ;
VAL_ 355 AccFllwMdeActv_B_Actl 1 "Active" 0 "Inactive" ;
VAL_ 355 EngPtoMde_D_Actl 7 "Undefined" 6 "Split_Shaft_Stationary" 5 "Not_Used_2" 4 "PTO_Mobile" 3 "Not_Used_1" 2 "PTO_Stationary" 1 "BCP" 0 "Off" ;
VAL_ 355 ManRgenTxt_D_RqDsply 7 "NotUsed3" 6 "NotUsed2" 5 "NotUsed1" 4 "Cleaning_Aborted_Stopped" 3 "Cleaning_Completed" 2 "Cleaning_In_Progress" 1 "Cleaning_Allowed" 0 "Cleaning_Not_Allowed" ;
VAL_ 355 ManRgenSoot_Pc_RqDsply 127 "Fault" ;
VAL_ 355 DieslMsgTxt_D_Rq 3 "NotUsed2" 2 "NotUsed1" 1 "ReducedEnginePower" 0 "NoMessage" ;
VAL_ 342 EngOvrhtMitgActv_D_Ind 3 "Undefined" 2 "Mode2" 1 "Mode1" 0 "Normal_Mode" ;
VAL_ 342 EngClntTe_D_Qf 3 "OK" 2 "Not_Within_Specifications" 1 "No_Data_Exists" 0 "Faulty" ;
VAL_ 342 EngOil_Te_Actl 255 "Fault" 254 "Unknown" ;
VAL_ 71 immoTarget1Status 7 "Unused4" 6 "Unused3" 5 "Unused2" 4 "Unused1" 3 "DISABLED_RESET   " 2 "ENABLED_NONMOTIVE_START" 1 "ENABLED_MOTIVE_START" 0 "DISABLED" ;
VAL_ 71 immoTarget1Cmd 7 "Unused4" 6 "Unused3" 5 "Unused2" 4 "Unused1" 3 "TARGET1_IDBLOCK2" 2 "TARGET1_IDBLOCK1" 1 "CHALLENGE" 0 "IDLE" ;
VAL_ 1006 PersIndexIpmb_D_Actl 7 "Unused_3" 6 "Unused_2" 5 "Unused_1" 4 "Vehicle" 3 "PERS_4" 2 "PERS_3" 1 "PERS_2" 0 "PERS_1" ;
VAL_ 820 AhbStatGfhbFdbk_D_Actl 3 "GfhbHighBeamFullyOn" 2 "GfhbHighBeamPartlyOn" 1 "GfhbHighBeamOff" 0 "GfhbUnavailable" ;
VAL_ 820 HeadLghtDrvSide_B_Stat 1 "Left_Hand_Traffic" 0 "Right_Hand_Traffic" ;
VAL_ 820 HeadLghtHiOn_B_StatHcm 1 "On" 0 "Off" ;
VAL_ 820 Adaptive_Hdlmp_Fault 1 "Yes" 0 "No" ;
VAL_ 137 SteWhlOffstRq_D_Stat 3 "Faulty" 2 "NoDataExists" 1 "Allow_External_Angle_Req" 0 "Deny_External_Angle_Req" ;
VAL_ 137 SteWhlOffst_An_TotActl 32767 "Faulty" 32766 "NoDataExists" ;
VAL_ 137 SteWhlBrkOffst_An_Actl 32767 "Faulty" 32766 "NoDataExists" ;
VAL_ 129 SelDrvMdeSwtch3_D_Stat4 3 "Faulty" 2 "Pressed" 1 "NotPressed" 0 "Null" ;
VAL_ 129 SelDrvMdeSwtch2_D_Stat4 3 "Faulty" 2 "Pressed" 1 "NotPressed" 0 "Null" ;
VAL_ 129 SelDrvMdeSwtch1_D_Stat4 3 "Faulty" 2 "Pressed" 1 "NotPressed" 0 "Null" ;
VAL_ 129 SelDrvMdeSwtch_D_Stat4 3 "Faulty" 2 "SwitchState2" 1 "SwitchState1" 0 "NotPressed" ;
VAL_ 129 SteWhlSwtchView_B_Stat 1 "Pressed" 0 "Not_Pressed" ;
VAL_ 129 SteWhlSwtchSet_B_Stat 1 "Pressed" 0 "Not_Pressed" ;
VAL_ 129 SteWhlSwtchPhon_B_Stat 1 "Pressed" 0 "Not_Pressed" ;
VAL_ 129 SteWhlSwtchNav_B_Stat 1 "Pressed" 0 "Not_Pressed" ;
VAL_ 129 SteWhlSwtchMed_B_Stat 1 "Pressed" 0 "Not_Pressed" ;
VAL_ 129 SteWhlSwtchIod_B_Stat 1 "Pressed" 0 "Not_Pressed" ;
VAL_ 129 SteWhlSwtchHud_B_Stat 1 "Pressed" 0 "Not_Pressed" ;
VAL_ 129 SteWhlSwtchBack_B_Stat 1 "Pressed" 0 "Not_Pressed" ;
VAL_ 129 SteWhlSwtchMenu_B_Stat 1 "Pressed" 0 "Not_Pressed" ;
VAL_ 129 SteEffortInc_B_RqDrv 1 "Pressed" 0 "Not_Pressed" ;
VAL_ 129 SelDrvMdeInc_B_RqDrv 1 "Pressed" 0 "Not_Pressed" ;
VAL_ 129 SelDrvMdeDec_B_RqDrv 1 "Pressed" 0 "Not_Pressed" ;
VAL_ 129 SuspDampInc_B_RqDrv 1 "Pressed" 0 "Not_Pressed" ;
VAL_ 129 SteWhlSwtchUp_B_Stat 1 "Pressed" 0 "Not_Pressed" ;
VAL_ 129 SteWhlSwtchRght_B_Stat 1 "Pressed" 0 "Not_Pressed" ;
VAL_ 129 SteWhlSwtchOk_B_Stat 1 "Pressed" 0 "Not_Pressed" ;
VAL_ 129 SteWhlSwtchLeft_B_Stat 1 "Pressed" 0 "Not_Pressed" ;
VAL_ 129 SteWhlSwtchDown_B_Stat 1 "Pressed" 0 "Not_Pressed" ;
VAL_ 129 SteWhlSwtchHome_B_Stat 1 "Pressed" 0 "Not_Pressed" ;
VAL_ 129 SteWhlSwtchInfo_B_Stat 1 "Pressed" 0 "Not_Pressed" ;
VAL_ 935 SodRight_D_Stat 7 "NotUsed_3" 6 "NotUsed_2" 5 "NotUsed_1" 4 "Invalid" 3 "Disabled" 2 "On" 1 "Trailer_Tow_Off" 0 "Off" ;
VAL_ 935 CtaAlrtRight2_D_Stat 7 "NotUsed3" 6 "NotUsed2" 5 "NotUsed1" 4 "AlertZone4" 3 "AlertZone3" 2 "AlertZone2" 1 "AlertZone1" 0 "Off" ;
VAL_ 935 BttRight_D_Stat 7 "NotUsed" 6 "Disabled" 5 "Off" 4 "OffTemp" 3 "NotConnected" 2 "Pending" 1 "Connected" 0 "NotDetermined" ;
VAL_ 935 BttRight_D_RqDrv 3 "NotUsed" 2 "Request" 1 "NoRequest" 0 "Null" ;
VAL_ 935 CtaBrkRightMsgTxt_B_Rq 1 "Enable" 0 "Disable" ;
VAL_ 935 CtaRightBrkEnbl_B_Rq 1 "Enable" 0 "Disable" ;
VAL_ 935 CtaRightBrkDecel_B_Rq 1 "Enable" 0 "Disable" ;
VAL_ 935 CtaSnsRight_D_Stat 3 "Invalid" 2 "System_Failure" 1 "Blocked" 0 "Clear" ;
VAL_ 935 CtaAlrtRight_D_Stat 1 "On" 0 "Off" ;
VAL_ 935 CtaRight_D_Stat 7 "NotUsed_3" 6 "NotUsed_2" 5 "NotUsed_1" 4 "Invalid" 3 "Disabled" 2 "On" 1 "Trailer_Tow_Off" 0 "Off" ;
VAL_ 935 SodSnsRight_D_Stat 3 "Second_Warning_Audio" 2 "System_Failure" 1 "Blocked" 0 "Clear" ;
VAL_ 935 SodAlrtRight_D_Stat 3 "Bulb_Proveout" 2 "Flash" 1 "On" 0 "Off" ;
VAL_ 935 SodDetctRight_D_Stat 4 "Sensor_Blocked" 3 "Sensor_Fault" 2 "Flash_On" 1 "Alert_On" 0 "AlertOff_FlashOff_SensrClr" ;
VAL_ 1108 RCMSerialNoByte8 255 "Invalid" 254 "Unknown" ;
VAL_ 1108 RCMSerialNoByte7 255 "Invalid" 254 "Unknown" ;
VAL_ 1108 RCMSerialNoByte6 255 "Invalid" 254 "Unknown" ;
VAL_ 1108 RCMSerialNoByte5 255 "Invalid" 254 "Unknown" ;
VAL_ 1108 RCMSerialNoByte4 255 "Invalid" 254 "Unknown" ;
VAL_ 1108 RCMSerialNoByte3 255 "Invalid" 254 "Unknown" ;
VAL_ 1108 RCMSerialNoByte2 255 "Invalid" 254 "Unknown" ;
VAL_ 1108 RCMSerialNoByte1 255 "Invalid" 254 "Unknown" ;
VAL_ 261 ChrgStatDsply_D_Rq 3 "NotUsed_2" 2 "NotUsed_1" 1 "On" 0 "Off" ;
VAL_ 261 NextUsageTimeToggle_Rq 0 "Inactive" 2 "Disable" 1 "Enable" ;
VAL_ 261 LongTermParking_Rq 0 "Inactive" 1 "On" 2 "Off" 3 "NotUsed" ;
VAL_ 261 ModemReset_D_Rq 15 "NotUsed_11" 14 "NotUsed_10" 13 "NotUsed_9" 12 "NotUsed_8" 11 "NotUsed_7" 10 "NotUsed_6" 9 "NotUsed_5" 8 "NotUsed_4" 7 "NotUsed_3" 6 "BrandConnectReset2" 5 "BrandConnectReset1" 4 "CcsReset" 3 "OnlineTrafficReset" 2 "PaakReset" 1 "WifiHotspotReset" 0 "Null" ;
VAL_ 261 StopStrtDrvMde_B_RqBtn3 1 "Pressed" 0 "Not_Pressed" ;
VAL_ 261 TCU_ESN_D_Rq 3 "NotUsed" 2 "TCU_ESN_Request" 1 "NoRequest" 0 "Inactive" ;
VAL_ 261 FactoryReset_Rq 1 "ResetFactoryDefaults" 0 "Inactive" ;
VAL_ 1146 TrlrAidSwtch_D_RqDrv 3 "Faulty" 2 "NotUsed" 1 "Pressed" 0 "Not_Pressed" ;
VAL_ 1146 TrlrAidCtl_U_RqDrv 4095 "Faulty" 4094 "NoDataExists" ;
VAL_ 533 DcacPw_D_Rq 3 "High" 2 "Low" 1 "Off" 0 "Null" ;
VAL_ 533 DcacPwReset_B_Rq 1 "Reset" 0 "Null" ;
VAL_ 533 DcacMdeButtn_B_Stat 1 "Pressed" 0 "Not_Pressed" ;
VAL_ 533 DcacPwButtn_B_Stat 1 "Pressed" 0 "Not_Pressed" ;
VAL_ 533 DcacGfciTestBttn_B_Stat 1 "Pressed" 0 "Not_Pressed" ;
VAL_ 533 DcacPwResetButtn_B_Stat 1 "Pressed" 0 "Not_Pressed" ;
VAL_ 533 DcacPwOffButtn_B_Stat 1 "Pressed" 0 "Not_Pressed" ;
VAL_ 533 DcacPwLoButtn_B_Stat 1 "Pressed" 0 "Not_Pressed" ;
VAL_ 533 DcacPwHiButtn_B_Stat 1 "Pressed" 0 "Not_Pressed" ;
VAL_ 533 DcacPwButtn_B_Falt 1 "Faulted" 0 "NotFaulted" ;
VAL_ 533 TrlrHitch_D_RqMnu 15 "NotUsed_10" 14 "NotUsed_9" 13 "NotUsed_8" 12 "NotUsed_7" 11 "NotUsed_6" 10 "NotUsed_5" 9 "NotUsed_4" 8 "NotUsed_3" 7 "NotUsed_2" 6 "NotUsed_1" 5 "GoToTraileringDomain" 4 "Confirm" 3 "TurnOnTba" 2 "TurnOnAutohitch" 1 "CancelAutohitch" 0 "NoRequest" ;
VAL_ 533 AutoEpbZoomView_B_Stat 1 "Active" 0 "Inactive" ;
VAL_ 533 AutoEpbButtn_B_Stat 1 "Pressed" 0 "Not_Pressed" ;
VAL_ 533 TrlrAidMde_D_Rq 3 "Mode_3" 2 "Mode_2" 1 "Mode_1" 0 "NoRequest" ;
VAL_ 533 TCU_Init_Actvtn_St 3 "NotUsed" 2 "InitialActivateDeny" 1 "InitialActivateAccept" 0 "Invalid" ;
VAL_ 533 TCU_Final_Actvtn_St 3 "NotUsed" 2 "FinalActivateDeny" 1 "FinalActivateAccept" 0 "Invalid" ;
VAL_ 533 OtaTrg_D_Stat 3 "NotUsed_1" 2 "Accepted" 1 "NotAccepted" 0 "Null" ;
VAL_ 533 OnbChrgGoTTouch_D_Rq 3 "NotUsed" 2 "On" 1 "Off" 0 "Null" ;
VAL_ 533 OnbChrgGoTPrcond_D_Rq 3 "High" 2 "Medium" 1 "Low" 0 "Off" ;
VAL_ 533 OnbChrgGoTOn_D_Rq 3 "NotUsed" 2 "On" 1 "Off" 0 "Null" ;
VAL_ 533 OnbChrgGoTMnte_D_Rq 15 "NotUsed_4" 14 "NotUsed_3" 13 "NotUsed_2" 12 "NotUsed_1" 11 "Minute_55" 10 "Minute_50" 9 "Minute_45" 8 "Minute_40" 7 "Minute_35" 6 "Minute_30" 5 "Minute_25" 4 "Minute_20" 3 "Minute_15" 2 "Minute_10" 1 "Minute_5" 0 "Minute_0" ;
VAL_ 533 OnbChrgGoTHr_T_Rq 31 "Faulty" 30 "NoDataExists" ;
VAL_ 533 OnbChrgGoTExtHtr_D_Rq 3 "NotUsed" 2 "On" 1 "Off" 0 "Null" ;
VAL_ 533 OnbChrgGoTDelete_B_Rq 1 "Request" 0 "NoRequest" ;
VAL_ 533 OnbChrgClearAll_B_Rq 1 "Request" 0 "NoRequest" ;
VAL_ 533 PaakMyKey_D_Rq 3 "NotUsed" 2 "ConfirmNewPaakMyKey" 1 "RequestNewPaakMyKey" 0 "None" ;
VAL_ 533 OnbChrgGoTUpdate_B_Rq 1 "Request" 0 "NoRequest" ;
VAL_ 1041 ElCmprUHi_D_Stat 3 "Overvoltage" 2 "Undervoltage" 1 "InRange" 0 "Undetermined" ;
VAL_ 1041 ElCmprOverTe_D_Stat 3 "OverTempStop" 2 "OverTempWarning" 1 "Normal" 0 "Undefined" ;
VAL_ 1041 ElCmpr_N_Actl 255 "Invalid" ;
VAL_ 1041 ElCmpr_Pw_Actl 255 "Invalid" ;
VAL_ 1041 ElCmpr_D_Stat 7 "Signal_Invalid" 6 "Comp_Off_ActlSpd_Abnormal" 5 "Comp_Off_TrgtSpd_OutRange" 4 "Comp_Shutdown" 3 "Comp_Stopped_Self_Protect" 2 "Comp_Degraded" 1 "Comp_On" 0 "Comp_Off" ;
VAL_ 1041 ElCmprPerfErr_D_Falt 3 "NotUsed" 2 "Pass" 1 "Fail" 0 "Not_Diagnose_Yet" ;
VAL_ 1041 ElCmprInnrErr_D_Falt 3 "NotUsed" 2 "Pass" 1 "Fail" 0 "Not_Diagnose_Yet" ;
VAL_ 1041 ElCmprLostComm_D_Falt 3 "NotUsed" 2 "Pass" 1 "Fail" 0 "Not_Diagnose_Yet" ;
VAL_ 1041 ElCmprOverLoad_D_Falt 3 "NotUsed" 2 "Pass" 1 "Fail" 0 "Not_Diagnose_Yet" ;
VAL_ 1041 ElCmprOverTe_D_Falt 3 "NotUsed" 2 "Pass" 1 "Fail" 0 "Not_Diagnose_Yet" ;
VAL_ 1041 ElCmprBattURng_D_Falt 3 "NotUsed" 2 "Pass" 1 "Fail" 0 "Not_Diagnose_Yet" ;
VAL_ 1041 ElCmprBattSysU_D_Falt 3 "NotUsed" 2 "Pass" 1 "Fail" 0 "Not_Diagnose_Yet" ;
VAL_ 1041 ElCmprSysU_D_Falt 3 "NotUsed" 2 "Pass" 1 "Fail" 0 "Not_Diagnose_Yet" ;
VAL_ 1067 BattULoAuxIsol_D_Rq 3 "Undefined" 2 "Retain" 1 "Close" 0 "Open" ;
VAL_ 1067 BattULoAux_U_Rq 4095 "Faulty" ;
VAL_ 1067 BattULoAux_I_Actl 4095 "Faulty" ;
VAL_ 1067 BattULoAux_D_Qlty 3 "OK" 2 "Not_Within_Specifications" 1 "Eval_In_Progress" 0 "Faulty" ;
VAL_ 1067 BattULoAux_U_Actl 255 "Faulty" ;
VAL_ 1067 BattULoAux_B_Falt 1 "Fault" 0 "No_Fault" ;
VAL_ 1112 BattTracDiagClr_B_Rq 1 "On" 0 "Off" ;
VAL_ 1112 BattTracChrgSustn_B_Rq 1 "Active" 0 "Inactive" ;
VAL_ 1112 BattTracCnnct_D_Cmd 7 "NotUsed_3" 6 "NotUsed_2" 5 "NotUsed_1" 4 "WeldCheck" 3 "OkToDischarge" 2 "Closed" 1 "Precharge" 0 "Open" ;
VAL_ 1112 BattTracHvilOpen_B_Stat 1 "Open" 0 "Closed" ;
VAL_ 1112 BattTracDcdcDis_B_Rq 1 "Yes" 0 "No" ;
VAL_ 1112 HtrnClntPump_D_Stat 3 "Faulty" 2 "No_Data_Exists" 1 "On" 0 "Off" ;
VAL_ 1112 BattTracClntPmp_D_Stat 3 "Faulty" 2 "No_Data_Exists" 1 "On" 0 "Off" ;
VAL_ 139 AfsPw_B_Rq 1 "Yes" 0 "No" ;
VAL_ 139 AccButtnGpTogglePress2 1 "Pressed" 0 "Not_Pressed" ;
VAL_ 139 TjaButtnOnOffPress2 1 "Pressed" 0 "Not_Pressed" ;
VAL_ 139 ActvFrontSteMsgTxt_D_Rq 7 "Message7" 6 "Message6" 5 "Message5" 4 "Message4" 3 "Message3" 2 "Message2" 1 "Message1" 0 "NoMessage" ;
VAL_ 139 ActvFrontSteLck_D_Stat 3 "Test_passed" 2 "Test_failed" 1 "Test_cannot_run" 0 "Test_incomplete" ;
VAL_ 139 SelDrvMdeAdptSte_D_Stat 3 "Faulty" 2 "TemporarilyNotAvailable" 1 "Available" 0 "NotAvailable" ;
VAL_ 139 AslButtnOnOffPress2 1 "Button_Pressed" 0 "Button_Not_Pressed" ;
VAL_ 139 AslButtnOnOffCnclPres2 1 "Button_Pressed" 0 "Button_Not_Pressed" ;
VAL_ 139 CcButtnOnPress2 1 "Button_Pressed" 0 "Button_Not_Pressed" ;
VAL_ 139 CcButtnOnOffPress2 1 "Button_Pressed" 0 "Button_Not_Pressed" ;
VAL_ 139 CcButtnOnOffCnclPress2 1 "Button_Pressed" 0 "Button_Not_Pressed" ;
VAL_ 139 CcButtnOffPress2 1 "Button_Pressed" 0 "Button_Not_Pressed" ;
VAL_ 139 CcAsllButtnResPress2 1 "Button_Pressed" 0 "Button_Not_Pressed" ;
VAL_ 139 CcAslButtnSetPress2 1 "Button_Pressed" 0 "Button_Not_Pressed" ;
VAL_ 139 CcAslButtnSetIncPress2 1 "Button_Pressed" 0 "Button_Not_Pressed" ;
VAL_ 139 CcAslButtnSetDecPress2 1 "Button_Pressed" 0 "Button_Not_Pressed" ;
VAL_ 139 CcAslButtnResIncPress2 1 "Button_Pressed" 0 "Button_Not_Pressed" ;
VAL_ 139 CcAslButtnResDecPress2 1 "Button_Pressed" 0 "Button_Not_Pressed" ;
VAL_ 139 CcAslButtnOnPress2 1 "Button_Pressed" 0 "Button_Not_Pressed" ;
VAL_ 139 CcAslButtnOnOffCncl2 1 "Button_Pressed" 0 "Button_Not_Pressed" ;
VAL_ 139 CcAslButtnOffCnclPres2 1 "Button_Pressed" 0 "Button_Not_Pressed" ;
VAL_ 139 CcAslButtnIndxIncPres2 1 "Button_Pressed" 0 "Button_Not_Pressed" ;
VAL_ 139 CcAslButtnIndxDecPres2 1 "Button_Pressed" 0 "Button_Not_Pressed" ;
VAL_ 139 CcAslButtnDeny_B_Actl2 1 "Yes" 0 "No" ;
VAL_ 139 CcAslButtnCnclResPres2 1 "Button_Pressed" 0 "Button_Not_Pressed" ;
VAL_ 139 CcAslButtnCnclPress2 1 "Button_Pressed" 0 "Button_Not_Pressed" ;
VAL_ 139 AccButtnGapIncPress2 1 "Button_Pressed" 0 "Button_Not_Pressed" ;
VAL_ 139 AccButtnGapDecPress2 1 "Button_Pressed" 0 "Button_Not_Pressed" ;
VAL_ 1121 SelDrvMdeSwtch_D_Stat 3 "Faulty" 2 "SwitchState2" 1 "SwitchState1" 0 "NotPressed" ;
VAL_ 1121 SelDrvMdeCnt_D_Stat 4 "FourCounts" 3 "ThreeCounts" 2 "TwoCounts" 1 "OneCount" 0 "ZeroCounts" 7 "SevenOrMoreCounts" 6 "SixCounts" 5 "FiveCounts" ;
VAL_ 1120 DrvSlipCtlMde_B_Rq3 1 "Pressed" 0 "Not_Pressed" ;
VAL_ 1120 HybMdeSwtch_B_Rq 1 "Pressed" 0 "Not_Pressed" ;
VAL_ 1120 TrailCtlSwtch_B_Stat3 1 "Pressed" 0 "Not_Pressed" ;
VAL_ 1120 RearDiffLck_D_RqDrv 3 "Faulty" 2 "NoRequest" 1 "On" 0 "Off" ;
VAL_ 1120 AwdMde_D_RqDrv 7 "Faulty" 6 "NotUsed2" 5 "NoRequest" 4 "Neutral" 3 "FourByFourLow" 2 "FourByFourHigh" 1 "FourByFourAuto" 0 "FourByTwo" ;
VAL_ 1120 HdcSwtchPos_B_Actl 1 "Pressed" 0 "Not_Pressed" ;
VAL_ 1050 AutoHoldSwtch_D_Stat 3 "Faulty" 2 "NotUsed" 1 "Pressed" 0 "Not_Pressed" ;
VAL_ 1050 LpdbPtc3_B_Rq 1 "On" 0 "Off" ;
VAL_ 1050 LpdbPtc2_B_Rq 1 "On" 0 "Off" ;
VAL_ 1050 LpdbPtc1_B_Rq 1 "On" 0 "Off" ;
VAL_ 1050 LpdbHeatWiprPrk_B_Rq 1 "On" 0 "Off" ;
VAL_ 1050 LpdbDfrstRearOn_B_Rq 1 "On" 0 "Off" ;
VAL_ 1050 SteWhlHeat_D_Rq 15 "NotUsed6" 14 "NotUsed5" 13 "NotUsed4" 12 "NotUsed3" 11 "NotUsed2" 10 "NotUsed1" 9 "Reserved_3" 8 "Reserved_2" 7 "Reserved_1" 6 "Level_3_Heating" 5 "Level_3_Heating_LS" 4 "Level_2_Heating" 3 "Level_2_Heating_LS" 2 "Level_1_Heating" 1 "Level_1_Heating_LS" 0 "Off" ;
VAL_ 1050 MirrorHeatOn_B_Rq 1 "True" 0 "False" ;
VAL_ 1050 Remote_Start_QuietMode 1 "Quiet" 0 "Not_Quiet" ;
VAL_ 1050 Outside_Air_Temp_Stat 255 "Invalid" 254 "Unknown" ;
VAL_ 1137 RngPerChrgAvg_L_Dsply 4095 "Faulty" 4094 "NoDataExists" ;
VAL_ 1255 BalrRight4Threat_D_Stat 1 "Yes" 0 "No" ;
VAL_ 1255 BalrRight4Fast_B_Stat 1 "Yes" 0 "No" ;
VAL_ 1255 BalrRight4Dsply_B_Stat 1 "Yes" 0 "No" ;
VAL_ 1254 BalrRight3Threat_D_Stat 1 "Yes" 0 "No" ;
VAL_ 1254 BalrRight3Fast_B_Stat 1 "Yes" 0 "No" ;
VAL_ 1254 BalrRight3Dsply_B_Stat 1 "Yes" 0 "No" ;
VAL_ 1253 BalrRight2Threat_D_Stat 1 "Yes" 0 "No" ;
VAL_ 1253 BalrRight2Fast_B_Stat 1 "Yes" 0 "No" ;
VAL_ 1253 BalrRight2Dsply_B_Stat 1 "Yes" 0 "No" ;
VAL_ 1252 BalrRight1Threat_D_Stat 1 "Yes" 0 "No" ;
VAL_ 1252 BalrRight1Fast_B_Stat 1 "Yes" 0 "No" ;
VAL_ 1252 BalrRight1Dsply_B_Stat 1 "Yes" 0 "No" ;
VAL_ 1251 BalrLeft4Threat_D_Stat 1 "Yes" 0 "No" ;
VAL_ 1251 BalrLeft4Fast_B_Stat 1 "Yes" 0 "No" ;
VAL_ 1251 BalrLeft4Dsply_B_Stat 1 "Yes" 0 "No" ;
VAL_ 1250 BalrLeft3Threat_D_Stat 1 "Yes" 0 "No" ;
VAL_ 1250 BalrLeft3Fast_B_Stat 1 "Yes" 0 "No" ;
VAL_ 1250 BalrLeft3Dsply_B_Stat 1 "Yes" 0 "No" ;
VAL_ 1249 BalrLeft2Threat_D_Stat 1 "Yes" 0 "No" ;
VAL_ 1249 BalrLeft2Fast_B_Stat 1 "Yes" 0 "No" ;
VAL_ 1249 BalrLeft2Dsply_B_Stat 1 "Yes" 0 "No" ;
VAL_ 1248 BalrLeft1Threat_D_Stat 1 "Yes" 0 "No" ;
VAL_ 1248 BalrLeft1Fast_B_Stat 1 "Yes" 0 "No" ;
VAL_ 1248 BalrLeft1Dsply_B_Stat 1 "Yes" 0 "No" ;
VAL_ 1113 TrlrTrgtAcquire_D_Stat 7 "Faulty" 6 "NotUsed_2" 5 "NotUsed_1" 4 "RVCforTBA_Activated" 3 "Processing" 2 "TargetNotAcquired" 1 "TargetAcquired" 0 "Null" ;
VAL_ 1113 TrlrAnOffstDir_D_Calc 3 "NotUSed" 2 "Right" 1 "Left_or_Center" 0 "Null" ;
VAL_ 1113 TrlrAnCalib_B_Complt 1 "Yes" 0 "No" ;
VAL_ 1113 TrlrRvrse_D_Stat 3 "Faulty" 2 "TrailerReverseGuidanceLite" 1 "On" 0 "Off" ;
VAL_ 1113 TrlrAid_D2_Stat 15 "Faulty" 14 "NotUsed_4" 13 "NotUsed_3" 12 "NotUsed_2" 11 "NotUsed_1" 10 "DirtyCamera" 9 "IncorrectLighting" 8 "TrackingLost" 7 "TrackingUnknownConfidence" 6 "TrackingHighConfidence" 5 "TrackingMediumConfidence" 4 "TrackingLowConfidence" 3 "TurnRequested" 2 "DriveStraighRequested" 1 "Initializing" 0 "NotTracking" ;
VAL_ 1113 TrlrAid_An3_Actl 2047 "Faulty" ;
VAL_ 1113 TrlrAid_AnRate2_Actl 1023 "Faulty" ;
VAL_ 1113 HitchToVehAxle_L_Calc 255 "Faulty" ;
VAL_ 1105 CamraFrntOffRd_B_Stat 1 "Active" 0 "Inactive" ;
VAL_ 1105 TrlrAidSwtchLamp_B_Rq 1 "On" 0 "Off" ;
VAL_ 1105 TrlrHitchMsgTxt_D_Rq 31 "Message31" 30 "Message30" 29 "Message29" 28 "Message28" 27 "Message27" 26 "Message26" 25 "Message25" 24 "Message24" 23 "Message23" 22 "Message22" 21 "Message21" 20 "Message20" 19 "Message19" 18 "Message18" 17 "Message17" 16 "Message16" 15 "Message15" 14 "Message14" 13 "Message13" 12 "Message12" 11 "Message11" 10 "Message10" 9 "Message9" 8 "Message8" 7 "Message7" 6 "Message6" 5 "Message5" 4 "Message4" 3 "Message3" 2 "Message2" 1 "Message1" 0 "NoMessage" 63 "Message63" 47 "Message47" ;
VAL_ 1105 TrlrHitchIcon_D_Rq 15 "Icon15" 14 "Icon14" 13 "Icon13" 12 "Icon12" 11 "Icon11" 10 "Icon10" 9 "Icon9" 8 "Icon8" 7 "Icon7" 6 "Icon6" 5 "Icon5" 4 "Icon4" 3 "Icon3" 2 "Icon2" 1 "Icon1" 0 "NoIcon" ;
VAL_ 1105 TrlrHitchChime_D_Rq 7 "NotUsed_1" 6 "NotUsed_1" 5 "WarningChime" 4 "NonCriticalAlertChime" 3 "StopNowChime" 2 "ManeuveringReadyChime" 1 "TrailerFoundChime" 0 "NoChime" ;
VAL_ 1105 TrlrAidEnbl_D_RqAdas 7 "NotUsed_4" 6 "NotUsed_3" 5 "NotUsed_2" 4 "NotUsed_1" 3 "Deactivate" 2 "NotAvailable" 1 "ActiveTba" 0 "Inactive" ;
VAL_ 1105 TrlrRvrseMsgTxt_D2_Rq 63 "Message63" 47 "Message47" 31 "Message31" 30 "Message30" 29 "Message29" 28 "Message28" 27 "Message27" 26 "Message26" 25 "Message25" 24 "Message24" 23 "Message23" 22 "Message22" 21 "Message21" 20 "Message20" 19 "Message19" 18 "Message18" 17 "Message17" 16 "Message16" 15 "Message15" 14 "Message14" 13 "Message13" 12 "Message12" 11 "Message11" 10 "Message10" 9 "Message9" 8 "Message8" 7 "Message7" 6 "Message6" 5 "Message5" 4 "Message4" 3 "Message3" 2 "Message2" 1 "Message1" 0 "NoMessage" ;
VAL_ 1105 TrlrRvrseEnbl_D2_Stat 7 "NotUsed" 6 "TbaActiveExpertActive" 5 "TbaActiveExpertAvail" 4 "TbaOffTrgActive" 3 "TbaOffTrgSetup" 2 "TbaSetup" 1 "TbaActive" 0 "Inactive" ;
VAL_ 1105 RbaMsg_D_Rq 3 "Faulty" 2 "Unavailable" 1 "Off" 0 "Null" ;
VAL_ 1105 BrkDecel_B_RqRba 1 "Enable" 0 "Disable" ;
VAL_ 1105 BrkEnbl_B_RqRba 1 "Enable" 0 "Disable" ;
VAL_ 1105 Rba_D_Stat 3 "NotUsed" 2 "Disabled" 1 "On" 0 "Off" ;
VAL_ 1105 RbaAlrt_D_Dsply 3 "Both" 2 "Text" 1 "Graphic" 0 "Off" ;
VAL_ 1105 RbaMnu_D_Rq 3 "NotUsed" 2 "Active" 1 "Inactive" 0 "None" ;
VAL_ 1105 CamraFrntStat_D_Stat 3 "No_Data_Present" 2 "NotUsed" 1 "On" 0 "Off" ;
VAL_ 1105 TrlrHitchLamp_D_Rq2 1 "On" 0 "Off" ;
VAL_ 938 SidePrkSnsR2_D_Stat 15 "NotUsed" 14 "NotFullyScannedYet" 13 "NoObjectInSector" 12 "Zone12" 11 "Zone11" 10 "Zone10" 9 "Zone9" 8 "Zone8" 7 "Zone7" 6 "Zone6" 5 "Zone5" 4 "Zone4" 3 "Zone3" 2 "Zone2" 1 "Zone1" 0 "Off" ;
VAL_ 938 SidePrkSnsR1_D_Stat 15 "NotUsed" 14 "NotFullyScannedYet" 13 "NoObjectInSector" 12 "Zone12" 11 "Zone11" 10 "Zone10" 9 "Zone9" 8 "Zone8" 7 "Zone7" 6 "Zone6" 5 "Zone5" 4 "Zone4" 3 "Zone3" 2 "Zone2" 1 "Zone1" 0 "Off" ;
VAL_ 938 SidePrkSnsL2_D_Stat 15 "NotUsed" 14 "NotFullyScannedYet" 13 "NoObjectInSector" 12 "Zone12" 11 "Zone11" 10 "Zone10" 9 "Zone9" 8 "Zone8" 7 "Zone7" 6 "Zone6" 5 "Zone5" 4 "Zone4" 3 "Zone3" 2 "Zone2" 1 "Zone1" 0 "Off" ;
VAL_ 938 ApaMde_D_Stat 7 "NotUsed3" 6 "NotUsed2" 5 "NotUsed1" 4 "POA" 3 "PPA" 2 "SAPP" 1 "Off" 0 "Null" ;
VAL_ 938 ApaActvSd_D_Actl 3 "Dirver_Side" 2 "Passenger_Side" 1 "No_Side" 0 "Null" ;
VAL_ 938 PrkAidSwtch_B_Stat 1 "Pressed" 0 "Not_Pressed" ;
VAL_ 938 ApaMde_D_Avail 15 "NotUsed7" 14 "NotUsed6" 13 "NotUsed5" 12 "NotUsed4" 11 "NotUsed3" 10 "NotUsed2" 9 "NotUsed1" 8 "PPA_POA" 7 "SAPP_POA" 6 "POA" 5 "PPA" 4 "SAPP" 3 "SAPP_PPA_POA" 2 "SAPP_PPA" 1 "None" 0 "Null" ;
VAL_ 938 PrkAidSnsFrCrnr_D_Stat 15 "Zone_15" 14 "Zone_14" 13 "Zone_13" 12 "Zone_12" 11 "Zone_11" 10 "Zone_10" 9 "Zone_9" 8 "Zone_8" 7 "Zone_7" 6 "Zone_6" 5 "Zone_5" 4 "Zone_4" 3 "Zone_3" 2 "Zone_2" 1 "Zone_1" 0 "Off" ;
VAL_ 938 PrkAidSnsFrCntr_D_Stat 15 "Zone_15" 14 "Zone_14" 13 "Zone_13" 12 "Zone_12" 11 "Zone_11" 10 "Zone_10" 9 "Zone_9" 8 "Zone_8" 7 "Zone_7" 6 "Zone_6" 5 "Zone_5" 4 "Zone_4" 3 "Zone_3" 2 "Zone_2" 1 "Zone_1" 0 "Off" ;
VAL_ 938 PrkAidSnsFlCrnr_D_Stat 15 "Zone_15" 14 "Zone_14" 13 "Zone_13" 12 "Zone_12" 11 "Zone_11" 10 "Zone_10" 9 "Zone_9" 8 "Zone_8" 7 "Zone_7" 6 "Zone_6" 5 "Zone_5" 4 "Zone_4" 3 "Zone_3" 2 "Zone_2" 1 "Zone_1" 0 "Off" ;
VAL_ 938 PrkAidSnsFlCntr_D_Stat 15 "Zone_15" 14 "Zone_14" 13 "Zone_13" 12 "Zone_12" 11 "Zone_11" 10 "Zone_10" 9 "Zone_9" 8 "Zone_8" 7 "Zone_7" 6 "Zone_6" 5 "Zone_5" 4 "Zone_4" 3 "Zone_3" 2 "Zone_2" 1 "Zone_1" 0 "Off" ;
VAL_ 938 PrkBrkEl_B_RqFap 1 "Yes" 0 "No" ;
VAL_ 938 RpaChime_D_Rq 15 "Zone15_Chime" 14 "Zone14_Chime" 13 "Zone13_Chime" 12 "Zone12_Chime" 11 "Zone11_Chime" 10 "Zone10_Chime" 9 "Zone9_Chime" 8 "Zone8_Chime" 7 "Zone7_Chime" 6 "Zone6_Chime" 5 "Zone5_Chime" 4 "Zone4_Chime" 3 "Zone3_Chime" 2 "Zone2_Chime" 1 "Zone1_Chime" 0 "No_Chime" ;
VAL_ 938 FpaChime_D_Rq 15 "Zone15_Chime" 14 "Zone14_Chime" 13 "Zone13_Chime" 12 "Zone12_Chime" 11 "Zone11_Chime" 10 "Zone10_Chime" 9 "Zone9_Chime" 8 "Zone8_Chime" 7 "Zone7_Chime" 6 "Zone6_Chime" 5 "Zone5_Chime" 4 "Zone4_Chime" 3 "Zone3_Chime" 2 "Zone2_Chime" 1 "Zone1_Chime" 0 "No_Chime" ;
VAL_ 938 PrkAidMsgTxt_D_Rq 15 "All_Sns_Blk" 14 "R_Sns_ON_F_Sns_Blk" 13 "R_Sns_Blk_F_Sns_ON" 12 "R_Sns_Inactive_Trlr_atch" 11 "Not_Avail_Trlr_attchd" 10 "Fail_Mode_no_Chime" 9 "Fail_Mode_with_Chime" 8 "R_Sns_Trlr_F_Sns_Blk" 7 "NotUsed3" 6 "Park_Sys_Alternate_Mode" 5 "R_Snsrs_On_F_Snsrs_On" 4 "NotUsed2" 3 "Reset_Message_Warn" 2 "R_Snsrs_Off_F_Snsrs_On" 1 "R_Snsrs_On_F_Snsrs_Off" 0 "All_Park_Sensors_Off" ;
VAL_ 938 SidePrkSnsL1_D_Stat 15 "NotUsed" 14 "NotFullyScannedYet" 13 "NoObjectInSector" 12 "Zone12" 11 "Zone11" 10 "Zone10" 9 "Zone9" 8 "Zone8" 7 "Zone7" 6 "Zone6" 5 "Zone5" 4 "Zone4" 3 "Zone3" 2 "Zone2" 1 "Zone1" 0 "Off" ;
VAL_ 938 PrkAidAudioMute_B_Rq 1 "Enable" 0 "Disable" ;
VAL_ 939 ApaBrk_D_Rq 3 "NotUsed" 2 "LowDecel" 1 "HighDecel" 0 "NoRequest" ;
VAL_ 939 SidePrkSnsR4_D_Stat 15 "NotUsed" 14 "NotFullyScannedYet" 13 "NoObjectInSector" 12 "Zone12" 11 "Zone11" 10 "Zone10" 9 "Zone9" 8 "Zone8" 7 "Zone7" 6 "Zone6" 5 "Zone5" 4 "Zone4" 3 "Zone3" 2 "Zone2" 1 "Zone1" 0 "Off" ;
VAL_ 939 SidePrkSnsR3_D_Stat 15 "NotUsed" 14 "NotFullyScannedYet" 13 "NoObjectInSector" 12 "Zone12" 11 "Zone11" 10 "Zone10" 9 "Zone9" 8 "Zone8" 7 "Zone7" 6 "Zone6" 5 "Zone5" 4 "Zone4" 3 "Zone3" 2 "Zone2" 1 "Zone1" 0 "Off" ;
VAL_ 939 SidePrkSnsL4_D_Stat 15 "NotUsed" 14 "NotFullyScannedYet" 13 "NoObjectInSector" 12 "Zone12" 11 "Zone11" 10 "Zone10" 9 "Zone9" 8 "Zone8" 7 "Zone7" 6 "Zone6" 5 "Zone5" 4 "Zone4" 3 "Zone3" 2 "Zone2" 1 "Zone1" 0 "Off" ;
VAL_ 939 SidePrkSnsL3_D_Stat 15 "NotUsed" 14 "NotFullyScannedYet" 13 "NoObjectInSector" 12 "Zone12" 11 "Zone11" 10 "Zone10" 9 "Zone9" 8 "Zone8" 7 "Zone7" 6 "Zone6" 5 "Zone5" 4 "Zone4" 3 "Zone3" 2 "Zone2" 1 "Zone1" 0 "Off" ;
VAL_ 939 PrkAidChime_D_Stat 3 "Fault" 2 "No_Data_Exists" 1 "On" 0 "Off" ;
VAL_ 939 PrkAidSnsRlCntr_D_Stat 15 "Zone_15" 14 "Zone_14" 13 "Zone_13" 12 "Zone_12" 11 "Zone_11" 10 "Zone_10" 9 "Zone_9" 8 "Zone_8" 7 "Zone_7" 6 "Zone_6" 5 "Zone_5" 4 "Zone_4" 3 "Zone_3" 2 "Zone_2" 1 "Zone_1" 0 "Off" ;
VAL_ 939 PrkAidSnsRrCrnr_D_Stat 15 "Zone_15" 14 "Zone_14" 13 "Zone_13" 12 "Zone_12" 11 "Zone_11" 10 "Zone_10" 9 "Zone_9" 8 "Zone_8" 7 "Zone_7" 6 "Zone_6" 5 "Zone_5" 4 "Zone_4" 3 "Zone_3" 2 "Zone_2" 1 "Zone_1" 0 "Off" ;
VAL_ 939 PrkAidSnsRrCntr_D_Stat 15 "Zone_15" 14 "Zone_14" 13 "Zone_13" 12 "Zone_12" 11 "Zone_11" 10 "Zone_10" 9 "Zone_9" 8 "Zone_8" 7 "Zone_7" 6 "Zone_6" 5 "Zone_5" 4 "Zone_4" 3 "Zone_3" 2 "Zone_2" 1 "Zone_1" 0 "Off" ;
VAL_ 939 PrkAidSnsRlCrnr_D_Stat 15 "Zone_15" 14 "Zone_14" 13 "Zone_13" 12 "Zone_12" 11 "Zone_11" 10 "Zone_10" 9 "Zone_9" 8 "Zone_8" 7 "Zone_7" 6 "Zone_6" 5 "Zone_5" 4 "Zone_4" 3 "Zone_3" 2 "Zone_2" 1 "Zone_1" 0 "Off" ;
VAL_ 939 PrkAidRear_D_Stat 3 "Faulted" 2 "Unused" 1 "Enabled" 0 "Disabled" ;
VAL_ 939 PrkAidFront_D_Stat 3 "Faulted" 2 "Unused" 1 "Enabled" 0 "Disabled" ;
VAL_ 939 PrkAid_D_Falt 7 "NotUsed2" 6 "NotUsed1" 5 "Failure_Front_PSM_Sensors" 4 "No_Data_Exists" 3 "Failure_Rear_Sensors" 2 "Speaker_Fault" 1 "ECU_Fault" 0 "No_Fault" ;
VAL_ 939 ApaLongCtrlEnbl_D_Rq 1 "Enable" 0 "Disable" ;
VAL_ 939 PrkAidLamp_D_Rq 3 "Not_Used" 2 "Flash" 1 "On" 0 "Off" ;
VAL_ 937 TrnRng_D_RqFap 7 "NotUsed3" 6 "NotUsed2" 5 "NotUsed1" 4 "Backwards" 3 "Forwards" 2 "NoMotion" 1 "Immobilize" 0 "NoRequest" ;
VAL_ 937 FapLcDistToObj_L_Actl 255 "Faulty" 254 "NoDataExists" ;
VAL_ 936 ApaButtnPrssd_B_Stat 1 "Pressed" 0 "Not_Pressed" ;
VAL_ 936 ApaSys_D_Stat 7 "Faulty" 6 "Finished" 5 "NotAccessible" 4 "ApaCancelled" 3 "Overspeed" 2 "On" 1 "Off" 0 "Null" ;
VAL_ 936 ApaSteWhl_D_RqDrv 3 "TakeControl" 2 "RemoveHands" 1 "NoRequest" 0 "Null" ;
VAL_ 936 ApaSteScanMde_D_Stat 3 "Steering" 2 "Scanning" 1 "NotScanning" 0 "Null" ;
VAL_ 936 ApaSelSapp_D_Stat 3 "NotConfigured" 2 "NotSelectable" 1 "Selectable" 0 "Null" ;
VAL_ 936 ApaSelPpa_D_Stat 3 "NotConfigured" 2 "NotSelectable" 1 "Selectable" 0 "Null" ;
VAL_ 936 ApaSelPoa_D_Stat 3 "NotConfigured" 2 "NotSelectable" 1 "Selectable" 0 "Null" ;
VAL_ 936 ApaScan_D_Stat 3 "ParkSlotReady" 2 "ParkSlotFound" 1 "NoParkSlot" 0 "Null" ;
VAL_ 936 ApaLongCtl_D_RqDrv 7 "NotUsed3" 6 "NotUsed2" 5 "ReleaseBrake" 4 "DriveBackward" 3 "DriveForward" 2 "Stop" 1 "NoRequest" 0 "Null" ;
VAL_ 936 ApaGearShif_D_RqDrv 7 "NotUSed2" 6 "NotUsed1" 5 "ShiftToP" 4 "ShiftToN" 3 "ShiftToD" 2 "ShiftToR" 1 "NoRequest" 0 "Null" ;
VAL_ 936 ApaActvSide2_D_Stat 3 "NoSide" 2 "Right" 1 "Left" 0 "Null" ;
VAL_ 936 ApaAcsy_D_RqDrv 7 "CloseDoor" 6 "SelectSideRight" 5 "SelectSideLeft" 4 "CheckForObject" 3 "PressApaButton" 2 "SelectSide" 1 "NoRequest" 0 "Null" ;
VAL_ 936 ApaTrgtDist_D_Stat 15 "Step15" 14 "Step14" 13 "Step13" 12 "Step12" 11 "Step11" 10 "Step10" 9 "Step9" 8 "Step8" 7 "Step7" 6 "Step6" 5 "Step5" 4 "Step4" 3 "Step3" 2 "Step2" 1 "Step1" 0 "Off" ;
VAL_ 936 ApaChime_D_Rq 7 "NotUsed2" 6 "NotUsed1" 5 "Warning_Chime" 4 "Finish_Chime" 3 "Stop_Now_Chime" 2 "Spot_Ready_Chime" 1 "Spot_Found_Chime" 0 "No_Chime" ;
VAL_ 936 EPASExtAngleStatReq 1 "Request" 0 "NoRequest" ;
VAL_ 936 ExtSteeringAngleReq2 32767 "Invalid" 32766 "Unknown" ;
VAL_ 877 VehElEffAvg_No_Dsply 127 "Faulty" 126 "NoDataExists" ;
VAL_ 877 PwFlwFuelDrv_D_Dsply 7 "NotUsed_4" 6 "NotUsed_3" 5 "NotUsed_2" 4 "NotUsed_1" 3 "FlwFromFuelToAllWhls" 2 "FlwFromFuelToFrontWhls" 1 "FlwFromFuelToRearWhls" 0 "NoFlow" ;
VAL_ 877 PwFlwFuelClimt_B_Dsply 1 "On" 0 "Off" ;
VAL_ 877 PwFlwFuelBatt_B_Dsply 1 "On" 0 "Off" ;
VAL_ 877 PwFlwBattClimt_B_Dsply 1 "On" 0 "Off" ;
VAL_ 877 PwFlwBatt_D_Dsply 15 "NotUsed_8" 14 "NotUsed_7" 13 "NotUsed_6" 12 "NotUsed_5" 11 "NotUsed_4" 10 "NotUsed_3" 9 "NotUsed_2" 8 "NotUsed_1" 7 "FlwFromWallToBatt" 6 "FlwFromAllWhlsToBatt" 5 "FlwFromBattToAllWhls" 4 "FlwFromFrontWhlsToBatt" 3 "FlwFromBattToFrontWhls" 2 "FlwFromRearWhlsToBatt" 1 "FlwFromBattToRearWhls" 0 "NoFlow" ;
VAL_ 588 BattTracSoc2_Pc_Actl 16383 "Faulty" 16382 "NoDataExists" ;
VAL_ 588 BattTrac_Te_Actl 1023 "Fault" 1022 "Unknown" ;
VAL_ 587 BattTracWarnLamp_B_Rq 1 "On" 0 "Off" ;
VAL_ 587 BattTracSrvcRqd_B_Rq 1 "On" 0 "Off" ;
VAL_ 389 HtrnOvrTeLamp_B_Dsply 1 "On" 0 "Off" ;
VAL_ 389 HtrnMil_D_Rq 3 "Not_Used" 2 "Flash" 1 "On" 0 "Off" ;
VAL_ 389 HtrnAin_UHi_Actl 1023 "Fault" 1022 "Unknown" ;
VAL_ 389 HtrnSrvcRqd_B_Dsply 1 "On" 0 "Off" ;
VAL_ 389 HtrnHvilOpen_B_Actl 1 "HVIL_is_Open" 0 "Normal_Operation" ;
VAL_ 389 PtWakeupDeltaT_T_Rq 2047 "Fault" 2046 "NoDataExists" ;
VAL_ 389 PreCondActv_B_Actl 1 "On" 0 "Off" ;
VAL_ 389 DrvCondTpRrDefrs_B_Rq 1 "On" 0 "Off" ;
VAL_ 389 BattTrac_I_EstVsc 32767 "Fault" 32766 "NoDataExists" ;
VAL_ 1009 ChrgCordUnlock_B_Rq 1 "Request" 0 "NoRequest" ;
VAL_ 1009 AutoHoldSwtch_D_Stat3 3 "Faulty" 2 "NotUsed" 1 "Pressed" 0 "Not_Pressed" ;
VAL_ 1009 TrlrTrgtAcquire_D_Rq 7 "NotUsed_2" 6 "NotUsed_1" 5 "ActivateRVCforTBA" 4 "CancelAcquisition" 3 "RetryAcquisition" 2 "AcquisitionSuccessful" 1 "StartAcquisition" 0 "Inactive" ;
VAL_ 1009 TrlrAidCancl_B_Rq 1 "Cancel" 0 "Null" ;
VAL_ 1009 CenterStackRing_D_Actl 3 "LimitedOn" 2 "On" 1 "Off" 0 "Null" ;
VAL_ 1009 ValetMode_D_Stat 3 "NotUsed" 2 "On" 1 "Off" 0 "Null" ;
VAL_ 1009 TrlrAidSetup_D_Stat 7 "Faulty" 6 "NotUsed_3" 5 "NotUsed_2" 4 "NotUsed_1" 3 "EnterParameters" 2 "EndSetup" 1 "BeginSetup" 0 "Null" ;
VAL_ 360 GsmSrvcRqd_B_Rq 1 "Yes" 0 "No" ;
VAL_ 360 TrnGearPwmFalt_B_Actl 1 "Yes" 0 "No" ;
VAL_ 360 GearButtnStuck_B_Actl 1 "Yes" 0 "No" ;
VAL_ 122 VehStrtInhbt_B_RqBatt 1 "Yes" 0 "No" ;
VAL_ 122 BattTracOffFst_D_Actl 3 "Unexpected_Contactor_Open" 2 "Restraints_Impact_Event" 1 "Interlock_Open" 0 "Normal" ;
VAL_ 122 BattTracOff_B_Actl 1 "Yes" 0 "No" ;
VAL_ 122 BattTracMil_D_Rq 3 "Not_Used" 2 "Flash" 1 "On" 0 "Off" ;
VAL_ 122 BattTrac_U_Actl 1023 "Fault" 1022 "Unknown" ;
VAL_ 122 BattTrac_I_Actl 32767 "Fault" 32766 "Unknown" ;
